// *************************************************************************** *
// *                                                                           *
// *                      Mentor Graphics Corporation                          *
// *                          All rights reserved                              *
// *                                                                           *
// *************************************************************************** *
// *                                                                           *
// * Description:         CANDB File                                           *
// * Generated at:        2022-07-01 13:40                                     *
// * System:              ZSDB122200                                           *
// * Variant:             DC1E_EU                                              *
// * Network:             BodyExposedCAN                                       *
// *                                                                           *
// *************************************************************************** *
// *                                                                           *
// *             THIS CONFIGURATION MIGHT CONTAIN SOME ERRORS                  *
// *              IF THE INPUT MODEL WAS NOT PROPERLY FORMED!                  *
// *                    Do Not Use this File directly!                         *
// *                                                                           *
// *************************************************************************** *
VERSION "BodyExposedCAN"

NS_ :

BS_ :

BU_ :  CEM ETC HCML HCMR RCML RCMM RCMR

BO_ 1322 CemBodyCanExposedNMFr : 8 CEM
 SG_ PNC16_CEM : 16|1@0+ (1,0) [0|0] "" Vector_XXX
 SG_ PNC17_CEM : 17|1@0+ (1,0) [0|0] "" Vector_XXX
 SG_ PNC18_CEM : 18|1@0+ (1,0) [0|0] "" Vector_XXX
 SG_ PNC19_CEM : 19|1@0+ (1,0) [0|0] "" Vector_XXX
 SG_ PNC20_CEM : 20|1@0+ (1,0) [0|0] "" Vector_XXX
 SG_ PNC21_CEM : 21|1@0+ (1,0) [0|0] "" Vector_XXX
 SG_ PNC22_CEM : 22|1@0+ (1,0) [0|0] "" Vector_XXX
 SG_ PNC23_CEM : 23|1@0+ (1,0) [0|0] "" Vector_XXX
 SG_ PNC24_CEM : 24|1@0+ (1,0) [0|0] "" Vector_XXX
 SG_ PNC25_CEM : 25|1@0+ (1,0) [0|0] "" Vector_XXX
 SG_ PNC26_CEM : 26|1@0+ (1,0) [0|0] "" Vector_XXX
 SG_ PNC27_CEM : 27|1@0+ (1,0) [0|0] "" Vector_XXX
 SG_ PNC28_CEM : 28|1@0+ (1,0) [0|0] "" Vector_XXX
 SG_ PNC29_CEM : 29|1@0+ (1,0) [0|0] "" Vector_XXX
 SG_ PNC30_CEM : 30|1@0+ (1,0) [0|0] "" Vector_XXX
 SG_ PNC31_CEM : 31|1@0+ (1,0) [0|0] "" Vector_XXX
 SG_ PNC32_CEM : 32|1@0+ (1,0) [0|0] "" Vector_XXX
 SG_ PNC33_CEM : 33|1@0+ (1,0) [0|0] "" Vector_XXX
 SG_ PNC34_CEM : 34|1@0+ (1,0) [0|0] "" Vector_XXX
 SG_ PNC35_CEM : 35|1@0+ (1,0) [0|0] "" Vector_XXX
 SG_ PNC36_CEM : 36|1@0+ (1,0) [0|0] "" Vector_XXX
 SG_ PNC37_CEM : 37|1@0+ (1,0) [0|0] "" Vector_XXX
 SG_ PNC38_CEM : 38|1@0+ (1,0) [0|0] "" Vector_XXX
 SG_ PNC39_CEM : 39|1@0+ (1,0) [0|0] "" Vector_XXX
 SG_ PNC40_CEM : 40|1@0+ (1,0) [0|0] "" Vector_XXX
 SG_ PNC41_CEM : 41|1@0+ (1,0) [0|0] "" Vector_XXX
 SG_ PNC42_CEM : 42|1@0+ (1,0) [0|0] "" Vector_XXX
 SG_ NM_PNI_CEM : 14|1@0+ (1,0) [0|0] "" Vector_XXX
 SG_ NM_AW_CEM : 12|1@0+ (1,0) [0|0] "" Vector_XXX
 SG_ NM_CS_CEM : 11|1@0+ (1,0) [0|0] "" Vector_XXX
 SG_ NM_RMR_CEM : 8|1@0+ (1,0) [0|0] "" Vector_XXX
 SG_ NM_NodeID_CEM : 7|8@0+ (1,0) [0|0] "" Vector_XXX

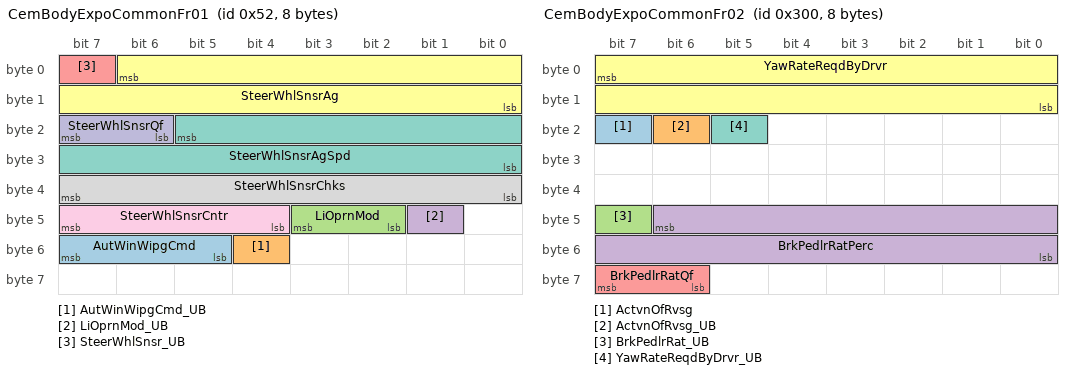
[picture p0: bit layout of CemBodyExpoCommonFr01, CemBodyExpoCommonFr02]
BO_ 82 CemBodyExpoCommonFr01 : 8 CEM
 SG_ AutWinWipgCmd : 55|3@0+ (1,0) [0|7] "" HCML,HCMR
 SG_ AutWinWipgCmd_UB : 52|1@0+ (1,0) [0|1] "" HCML,HCMR
 SG_ LiOprnMod : 43|2@0+ (1,0) [0|3] "" HCML,HCMR
 SG_ LiOprnMod_UB : 41|1@0+ (1,0) [0|1] "" HCML,HCMR
 SG_ SteerWhlSnsr_UB : 7|1@0+ (1,0) [0|1] "" HCML,HCMR
 SG_ SteerWhlSnsrAg : 6|15@0- (0.0009765625,0.0) [-14.5|14.5] "rad" HCML,HCMR
 SG_ SteerWhlSnsrAgSpd : 21|14@0- (0.0078125,0.0) [-50.0|50.0] "rad/s" HCML,HCMR
 SG_ SteerWhlSnsrChks : 39|8@0+ (1.0,0.0) [0.0|255.0] "Unitless" HCML,HCMR
 SG_ SteerWhlSnsrCntr : 47|4@0+ (1.0,0.0) [0.0|15.0] "Unitless" HCML,HCMR
 SG_ SteerWhlSnsrQf : 23|2@0+ (1,0) [0|3] "" HCML,HCMR

BO_ 768 CemBodyExpoCommonFr02 : 8 CEM
 SG_ ActvnOfRvsg : 23|1@0+ (1,0) [0|1] "" RCML,RCMM,RCMR
 SG_ ActvnOfRvsg_UB : 22|1@0+ (1,0) [0|1] "" RCML,RCMM,RCMR
 SG_ BrkPedlrRat_UB : 47|1@0+ (1,0) [0|1] "" HCML,HCMR
 SG_ BrkPedlrRatPerc : 46|15@0+ (0.00390625,0.0) [0.0|100.0] "%" HCML,HCMR
 SG_ BrkPedlrRatQf : 63|2@0+ (1,0) [0|3] "" HCML,HCMR
 SG_ YawRateReqdByDrvr : 7|16@0- (0.000244140625,0.0) [-5.0|5.0] "rad/s" HCML,HCMR
 SG_ YawRateReqdByDrvr_UB : 21|1@0+ (1,0) [0|1] "" HCML,HCMR

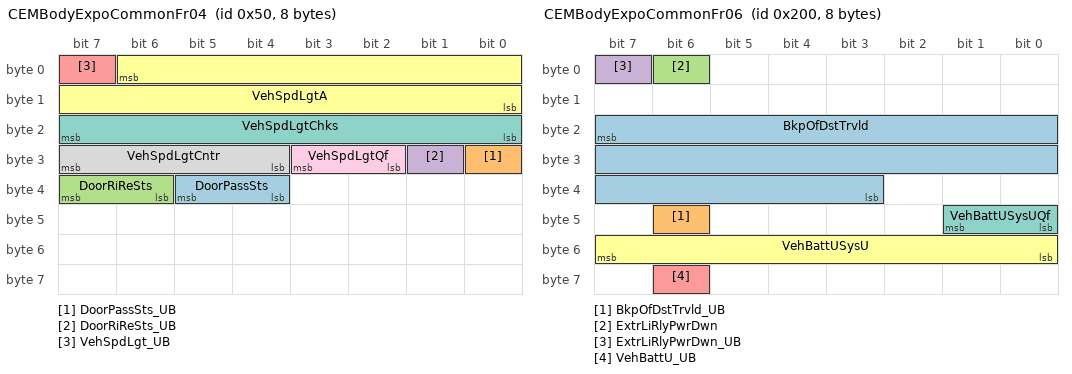
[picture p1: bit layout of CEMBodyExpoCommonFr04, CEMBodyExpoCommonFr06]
BO_ 80 CEMBodyExpoCommonFr04 : 8 CEM
 SG_ DoorPassSts : 37|2@0+ (1,0) [0|3] "" Vector_XXX
 SG_ DoorPassSts_UB : 24|1@0+ (1,0) [0|1] "" Vector_XXX
 SG_ DoorRiReSts : 39|2@0+ (1,0) [0|3] "" Vector_XXX
 SG_ DoorRiReSts_UB : 25|1@0+ (1,0) [0|1] "" Vector_XXX
 SG_ VehSpdLgt_UB : 7|1@0+ (1,0) [0|1] "" HCML,HCMR,RCML,RCMM,RCMR
 SG_ VehSpdLgtA : 6|15@0+ (0.00391,0.0) [0.0|125.0027] "m/s" HCML,HCMR,RCML,RCMM,RCMR
 SG_ VehSpdLgtChks : 23|8@0+ (1.0,0.0) [0.0|255.0] "Unitless" HCML,HCMR,RCML,RCMM,RCMR
 SG_ VehSpdLgtCntr : 31|4@0+ (1.0,0.0) [0.0|15.0] "Unitless" HCML,HCMR,RCML,RCMM,RCMR
 SG_ VehSpdLgtQf : 27|2@0+ (1,0) [0|3] "" HCML,HCMR,RCML,RCMM,RCMR

BO_ 384 CemBodyExpoCommonFr05 : 8 CEM
 SG_ VehCfgPrmBlkIDBytePosn1 : 7|8@0+ (1.0,0.0) [0.0|255.0] "Unitless" HCML,HCMR,RCML,RCMM,RCMR
 SG_ VehCfgPrmCCPBytePosn2 : 15|8@0+ (1.0,0.0) [0.0|255.0] "Unitless" HCML,HCMR,RCML,RCMM,RCMR
 SG_ VehCfgPrmCCPBytePosn3 : 23|8@0+ (1.0,0.0) [0.0|255.0] "Unitless" HCML,HCMR,RCML,RCMM,RCMR
 SG_ VehCfgPrmCCPBytePosn4 : 31|8@0+ (1.0,0.0) [0.0|255.0] "Unitless" HCML,HCMR,RCML,RCMM,RCMR
 SG_ VehCfgPrmCCPBytePosn5 : 39|8@0+ (1.0,0.0) [0.0|255.0] "Unitless" HCML,HCMR,RCML,RCMM,RCMR
 SG_ VehCfgPrmCCPBytePosn6 : 47|8@0+ (1.0,0.0) [0.0|255.0] "Unitless" HCML,HCMR,RCML,RCMM,RCMR
 SG_ VehCfgPrmCCPBytePosn7 : 55|8@0+ (1.0,0.0) [0.0|255.0] "Unitless" HCML,HCMR,RCML,RCMM,RCMR
 SG_ VehCfgPrmCCPBytePosn8 : 63|8@0+ (1.0,0.0) [0.0|255.0] "Unitless" HCML,HCMR,RCML,RCMM,RCMR

BO_ 512 CEMBodyExpoCommonFr06 : 8 CEM
 SG_ BkpOfDstTrvld : 23|21@0+ (1.0,0.0) [0.0|2000000.0] "km" HCML,HCMR,RCML,RCMM,RCMR
 SG_ BkpOfDstTrvld_UB : 46|1@0+ (1,0) [0|1] "" HCML,HCMR,RCML,RCMM,RCMR
 SG_ ExtrLiRlyPwrDwn : 6|1@0+ (1,0) [0|1] "" HCML,HCMR
 SG_ ExtrLiRlyPwrDwn_UB : 7|1@0+ (1,0) [0|1] "" HCML,HCMR
 SG_ VehBattU_UB : 62|1@0+ (1,0) [0|1] "" HCML,HCMR,RCML,RCMM,RCMR
 SG_ VehBattUSysU : 55|8@0+ (0.1,0.0) [0.0|25.0] "Volt" HCML,HCMR,RCML,RCMM,RCMR
 SG_ VehBattUSysUQf : 41|2@0+ (1,0) [0|3] "" HCML,HCMR,RCML,RCMM,RCMR

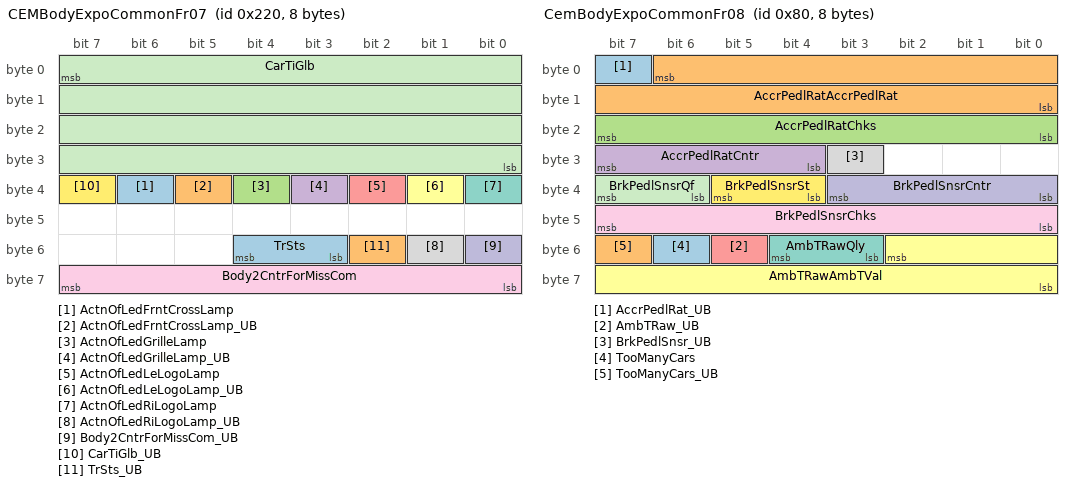
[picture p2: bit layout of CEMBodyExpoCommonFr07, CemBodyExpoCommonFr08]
BO_ 544 CEMBodyExpoCommonFr07 : 8 CEM
 SG_ ActnOfLedFrntCrossLamp : 38|1@0+ (1,0) [0|1] "" HCML,HCMR
 SG_ ActnOfLedFrntCrossLamp_UB : 37|1@0+ (1,0) [0|1] "" HCML,HCMR
 SG_ ActnOfLedGrilleLamp : 36|1@0+ (1,0) [0|1] "" HCML,HCMR
 SG_ ActnOfLedGrilleLamp_UB : 35|1@0+ (1,0) [0|1] "" HCML,HCMR
 SG_ ActnOfLedLeLogoLamp : 34|1@0+ (1,0) [0|1] "" HCML
 SG_ ActnOfLedLeLogoLamp_UB : 33|1@0+ (1,0) [0|1] "" HCML
 SG_ ActnOfLedRiLogoLamp : 32|1@0+ (1,0) [0|1] "" HCMR
 SG_ ActnOfLedRiLogoLamp_UB : 49|1@0+ (1,0) [0|1] "" HCMR
 SG_ Body2CntrForMissCom : 63|8@0+ (1.0,0.0) [0.0|255.0] "Unitless" HCML,HCMR
 SG_ Body2CntrForMissCom_UB : 48|1@0+ (1,0) [0|1] "" HCML,HCMR
 SG_ CarTiGlb : 7|32@0+ (0.1,0.0) [0.0|429496729.5] "s" HCML,HCMR,RCML,RCMM,RCMR
 SG_ CarTiGlb_UB : 39|1@0+ (1,0) [0|1] "" HCML,HCMR,RCML,RCMM,RCMR
 SG_ TrSts : 52|2@0+ (1,0) [0|3] "" RCML,RCMM,RCMR
 SG_ TrSts_UB : 50|1@0+ (1,0) [0|1] "" RCML,RCMM,RCMR

BO_ 128 CemBodyExpoCommonFr08 : 8 CEM
 SG_ AccrPedlRat_UB : 7|1@0+ (1,0) [0|1] "" HCML,HCMR
 SG_ AccrPedlRatAccrPedlRat : 6|15@0+ (0.00390625,0.0) [0.0|100.0] "%" HCML,HCMR
 SG_ AccrPedlRatChks : 23|8@0+ (1.0,0.0) [0.0|255.0] "Unitless" HCML,HCMR
 SG_ AccrPedlRatCntr : 31|4@0+ (1.0,0.0) [0.0|15.0] "Unitless" HCML,HCMR
 SG_ AmbTRaw_UB : 53|1@0+ (1,0) [0|1] "" HCML,HCMR
 SG_ AmbTRawAmbTVal : 50|11@0+ (0.1,-70.0) [-70.0|134.70000000000002] "degC" HCML,HCMR
 SG_ AmbTRawQly : 52|2@0+ (1,0) [0|3] "" HCML,HCMR
 SG_ BrkPedlSnsr_UB : 27|1@0+ (1,0) [0|1] "" HCML,HCMR
 SG_ BrkPedlSnsrChks : 47|8@0+ (1.0,0.0) [0.0|255.0] "Unitless" HCML,HCMR
 SG_ BrkPedlSnsrCntr : 35|4@0+ (1.0,0.0) [0.0|15.0] "Unitless" HCML,HCMR
 SG_ BrkPedlSnsrQf : 39|2@0+ (1,0) [0|3] "" HCML,HCMR
 SG_ BrkPedlSnsrSt : 37|2@0+ (1,0) [0|3] "" HCML,HCMR
 SG_ TooManyCars : 54|1@0+ (1,0) [0|1] "" HCML,HCMR
 SG_ TooManyCars_UB : 55|1@0+ (1,0) [0|1] "" HCML,HCMR

BO_ 387 CemBodyExpoCommonFr09 : 8 CEM
 SG_ VehCfgPrmExtBlkIDBytePosn1 : 7|8@0+ (1.0,0.0) [0.0|255.0] "Unitless" HCML,HCMR,RCML,RCMM,RCMR
 SG_ VehCfgPrmExtCCPBytePosn2 : 15|8@0+ (1.0,0.0) [0.0|255.0] "Unitless" HCML,HCMR,RCML,RCMM,RCMR
 SG_ VehCfgPrmExtCCPBytePosn3 : 23|8@0+ (1.0,0.0) [0.0|255.0] "Unitless" HCML,HCMR,RCML,RCMM,RCMR
 SG_ VehCfgPrmExtCCPBytePosn4 : 31|8@0+ (1.0,0.0) [0.0|255.0] "Unitless" HCML,HCMR,RCML,RCMM,RCMR
 SG_ VehCfgPrmExtCCPBytePosn5 : 39|8@0+ (1.0,0.0) [0.0|255.0] "Unitless" HCML,HCMR,RCML,RCMM,RCMR
 SG_ VehCfgPrmExtCCPBytePosn6 : 47|8@0+ (1.0,0.0) [0.0|255.0] "Unitless" HCML,HCMR,RCML,RCMM,RCMR
 SG_ VehCfgPrmExtCCPBytePosn7 : 55|8@0+ (1.0,0.0) [0.0|255.0] "Unitless" HCML,HCMR,RCML,RCMM,RCMR
 SG_ VehCfgPrmExtCCPBytePosn8 : 63|8@0+ (1.0,0.0) [0.0|255.0] "Unitless" HCML,HCMR,RCML,RCMM,RCMR

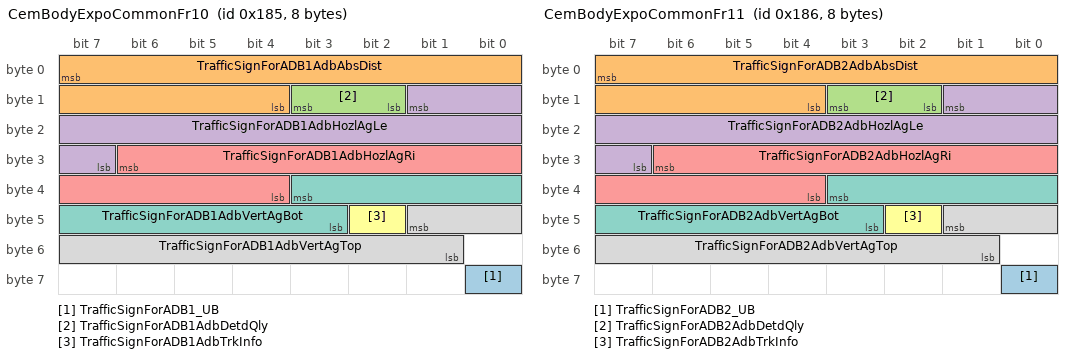
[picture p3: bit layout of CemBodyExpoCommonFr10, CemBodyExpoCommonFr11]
BO_ 389 CemBodyExpoCommonFr10 : 8 CEM
 SG_ TrafficSignForADB1_UB : 56|1@0+ (1,0) [0|1] "" HCML,HCMR
 SG_ TrafficSignForADB1AdbAbsDist : 7|12@0+ (0.2,0.0) [0.0|819.0] "m" HCML,HCMR
 SG_ TrafficSignForADB1AdbDetdQly : 11|2@0+ (1,0) [0|3] "" HCML,HCMR
 SG_ TrafficSignForADB1AdbHozlAgLe : 9|11@0+ (0.05,-40.0) [-40.0|40.0] "Deg" HCML,HCMR
 SG_ TrafficSignForADB1AdbHozlAgRi : 30|11@0+ (0.05,-40.0) [-40.0|40.0] "Deg" HCML,HCMR
 SG_ TrafficSignForADB1AdbTrkInfo : 42|1@0+ (1,0) [0|1] "" HCML,HCMR
 SG_ TrafficSignForADB1AdbVertAgBot : 35|9@0+ (0.05,-3.0) [-3.0|22.55] "Deg" HCML,HCMR
 SG_ TrafficSignForADB1AdbVertAgTop : 41|9@0+ (0.05,-3.0) [-3.0|22.55] "Deg" HCML,HCMR

BO_ 390 CemBodyExpoCommonFr11 : 8 CEM
 SG_ TrafficSignForADB2_UB : 56|1@0+ (1,0) [0|1] "" HCML,HCMR
 SG_ TrafficSignForADB2AdbAbsDist : 7|12@0+ (0.2,0.0) [0.0|819.0] "m" HCML,HCMR
 SG_ TrafficSignForADB2AdbDetdQly : 11|2@0+ (1,0) [0|3] "" HCML,HCMR
 SG_ TrafficSignForADB2AdbHozlAgLe : 9|11@0+ (0.05,-40.0) [-40.0|40.0] "Deg" HCML,HCMR
 SG_ TrafficSignForADB2AdbHozlAgRi : 30|11@0+ (0.05,-40.0) [-40.0|40.0] "Deg" HCML,HCMR
 SG_ TrafficSignForADB2AdbTrkInfo : 42|1@0+ (1,0) [0|1] "" HCML,HCMR
 SG_ TrafficSignForADB2AdbVertAgBot : 35|9@0+ (0.05,-3.0) [-3.0|22.55] "Deg" HCML,HCMR
 SG_ TrafficSignForADB2AdbVertAgTop : 41|9@0+ (0.05,-3.0) [-3.0|22.55] "Deg" HCML,HCMR

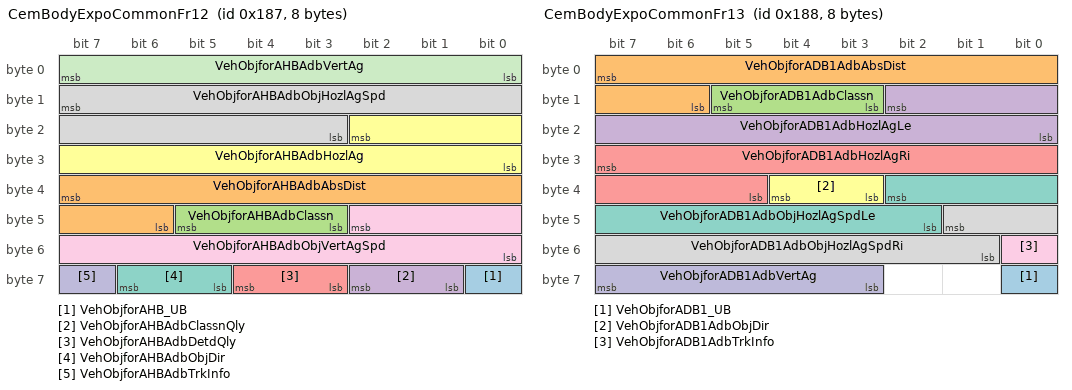
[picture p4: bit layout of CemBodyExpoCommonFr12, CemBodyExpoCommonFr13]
BO_ 391 CemBodyExpoCommonFr12 : 8 CEM
 SG_ VehObjforAHB_UB : 56|1@0+ (1,0) [0|1] "" HCML,HCMR
 SG_ VehObjforAHBAdbAbsDist : 39|10@0+ (1.0,0.0) [0.0|1000.0] "m" HCML,HCMR
 SG_ VehObjforAHBAdbClassn : 45|3@0+ (1,0) [0|7] "" HCML,HCMR
 SG_ VehObjforAHBAdbClassnQly : 58|2@0+ (1,0) [0|3] "" HCML,HCMR
 SG_ VehObjforAHBAdbDetdQly : 60|2@0+ (1,0) [0|3] "" HCML,HCMR
 SG_ VehObjforAHBAdbHozlAg : 18|11@0+ (0.05,-40.0) [-40.0|40.0] "Deg" HCML,HCMR
 SG_ VehObjforAHBAdbObjDir : 62|2@0+ (1,0) [0|3] "" HCML,HCMR
 SG_ VehObjforAHBAdbObjHozlAgSpd : 15|13@0+ (0.05,-144.0) [-144.0|144.0] "DegPerSec" HCML,HCMR
 SG_ VehObjforAHBAdbObjVertAgSpd : 42|11@0+ (0.2,-144.0) [-144.0|144.0] "DegPerSec" HCML,HCMR
 SG_ VehObjforAHBAdbTrkInfo : 63|1@0+ (1,0) [0|1] "" HCML,HCMR
 SG_ VehObjforAHBAdbVertAg : 7|8@0+ (0.2,-15.0) [-15.0|15.0] "Deg" HCML,HCMR

BO_ 392 CemBodyExpoCommonFr13 : 8 CEM
 SG_ VehObjforADB1_UB : 56|1@0+ (1,0) [0|1] "" HCML,HCMR
 SG_ VehObjforADB1AdbAbsDist : 7|10@0+ (1.0,0.0) [0.0|1000.0] "m" HCML,HCMR
 SG_ VehObjforADB1AdbClassn : 13|3@0+ (1,0) [0|7] "" HCML,HCMR
 SG_ VehObjforADB1AdbHozlAgLe : 10|11@0+ (0.05,-40.0) [-40.0|40.0] "Deg" HCML,HCMR
 SG_ VehObjforADB1AdbHozlAgRi : 31|11@0+ (0.05,-40.0) [-40.0|40.0] "Deg" HCML,HCMR
 SG_ VehObjforADB1AdbObjDir : 36|2@0+ (1,0) [0|3] "" HCML,HCMR
 SG_ VehObjforADB1AdbObjHozlAgSpdLe : 34|9@0+ (0.2,-50.0) [-50.0|52.2] "DegPerSec" HCML,HCMR
 SG_ VehObjforADB1AdbObjHozlAgSpdRi : 41|9@0+ (0.2,-50.0) [-50.0|52.2] "DegPerSec" HCML,HCMR
 SG_ VehObjforADB1AdbTrkInfo : 48|1@0+ (1,0) [0|1] "" HCML,HCMR
 SG_ VehObjforADB1AdbVertAg : 63|5@0+ (0.5,-3.0) [-3.0|12.5] "Deg" HCML,HCMR

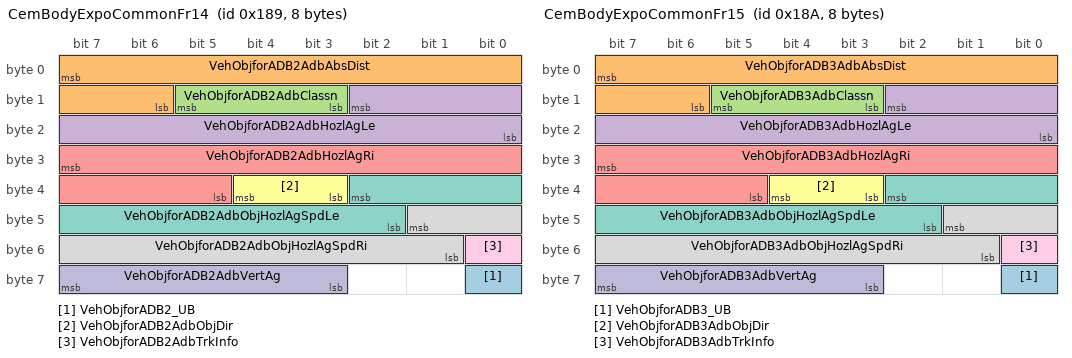
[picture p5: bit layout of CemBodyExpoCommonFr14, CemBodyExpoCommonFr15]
BO_ 393 CemBodyExpoCommonFr14 : 8 CEM
 SG_ VehObjforADB2_UB : 56|1@0+ (1,0) [0|1] "" HCML,HCMR
 SG_ VehObjforADB2AdbAbsDist : 7|10@0+ (1.0,0.0) [0.0|1000.0] "m" HCML,HCMR
 SG_ VehObjforADB2AdbClassn : 13|3@0+ (1,0) [0|7] "" HCML,HCMR
 SG_ VehObjforADB2AdbHozlAgLe : 10|11@0+ (0.05,-40.0) [-40.0|40.0] "Deg" HCML,HCMR
 SG_ VehObjforADB2AdbHozlAgRi : 31|11@0+ (0.05,-40.0) [-40.0|40.0] "Deg" HCML,HCMR
 SG_ VehObjforADB2AdbObjDir : 36|2@0+ (1,0) [0|3] "" HCML,HCMR
 SG_ VehObjforADB2AdbObjHozlAgSpdLe : 34|9@0+ (0.2,-50.0) [-50.0|52.2] "DegPerSec" HCML,HCMR
 SG_ VehObjforADB2AdbObjHozlAgSpdRi : 41|9@0+ (0.2,-50.0) [-50.0|52.2] "DegPerSec" HCML,HCMR
 SG_ VehObjforADB2AdbTrkInfo : 48|1@0+ (1,0) [0|1] "" HCML,HCMR
 SG_ VehObjforADB2AdbVertAg : 63|5@0+ (0.5,-3.0) [-3.0|12.5] "Deg" HCML,HCMR

BO_ 394 CemBodyExpoCommonFr15 : 8 CEM
 SG_ VehObjforADB3_UB : 56|1@0+ (1,0) [0|1] "" HCML,HCMR
 SG_ VehObjforADB3AdbAbsDist : 7|10@0+ (1.0,0.0) [0.0|1000.0] "m" HCML,HCMR
 SG_ VehObjforADB3AdbClassn : 13|3@0+ (1,0) [0|7] "" HCML,HCMR
 SG_ VehObjforADB3AdbHozlAgLe : 10|11@0+ (0.05,-40.0) [-40.0|40.0] "Deg" HCML,HCMR
 SG_ VehObjforADB3AdbHozlAgRi : 31|11@0+ (0.05,-40.0) [-40.0|40.0] "Deg" HCML,HCMR
 SG_ VehObjforADB3AdbObjDir : 36|2@0+ (1,0) [0|3] "" HCML,HCMR
 SG_ VehObjforADB3AdbObjHozlAgSpdLe : 34|9@0+ (0.2,-50.0) [-50.0|52.2] "DegPerSec" HCML,HCMR
 SG_ VehObjforADB3AdbObjHozlAgSpdRi : 41|9@0+ (0.2,-50.0) [-50.0|52.2] "DegPerSec" HCML,HCMR
 SG_ VehObjforADB3AdbTrkInfo : 48|1@0+ (1,0) [0|1] "" HCML,HCMR
 SG_ VehObjforADB3AdbVertAg : 63|5@0+ (0.5,-3.0) [-3.0|12.5] "Deg" HCML,HCMR

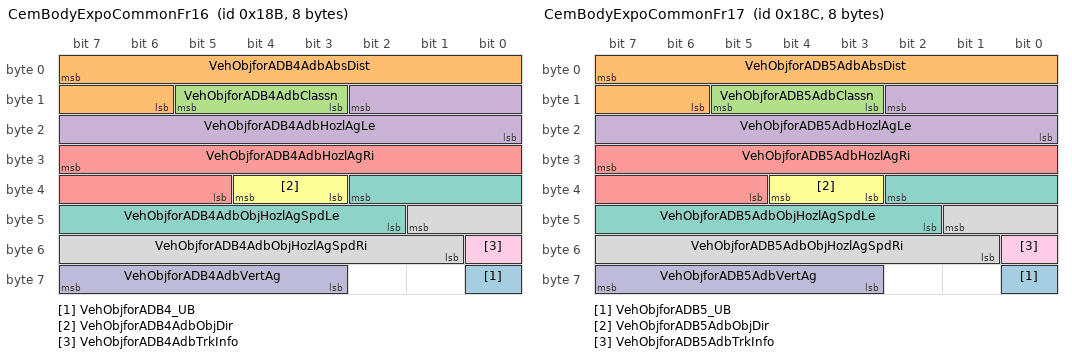
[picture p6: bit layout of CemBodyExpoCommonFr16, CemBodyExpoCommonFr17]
BO_ 395 CemBodyExpoCommonFr16 : 8 CEM
 SG_ VehObjforADB4_UB : 56|1@0+ (1,0) [0|1] "" HCML,HCMR
 SG_ VehObjforADB4AdbAbsDist : 7|10@0+ (1.0,0.0) [0.0|1000.0] "m" HCML,HCMR
 SG_ VehObjforADB4AdbClassn : 13|3@0+ (1,0) [0|7] "" HCML,HCMR
 SG_ VehObjforADB4AdbHozlAgLe : 10|11@0+ (0.05,-40.0) [-40.0|40.0] "Deg" HCML,HCMR
 SG_ VehObjforADB4AdbHozlAgRi : 31|11@0+ (0.05,-40.0) [-40.0|40.0] "Deg" HCML,HCMR
 SG_ VehObjforADB4AdbObjDir : 36|2@0+ (1,0) [0|3] "" HCML,HCMR
 SG_ VehObjforADB4AdbObjHozlAgSpdLe : 34|9@0+ (0.2,-50.0) [-50.0|52.2] "DegPerSec" HCML,HCMR
 SG_ VehObjforADB4AdbObjHozlAgSpdRi : 41|9@0+ (0.2,-50.0) [-50.0|52.2] "DegPerSec" HCML,HCMR
 SG_ VehObjforADB4AdbTrkInfo : 48|1@0+ (1,0) [0|1] "" HCML,HCMR
 SG_ VehObjforADB4AdbVertAg : 63|5@0+ (0.5,-3.0) [-3.0|12.5] "Deg" HCML,HCMR

BO_ 396 CemBodyExpoCommonFr17 : 8 CEM
 SG_ VehObjforADB5_UB : 56|1@0+ (1,0) [0|1] "" HCML,HCMR
 SG_ VehObjforADB5AdbAbsDist : 7|10@0+ (1.0,0.0) [0.0|1000.0] "m" HCML,HCMR
 SG_ VehObjforADB5AdbClassn : 13|3@0+ (1,0) [0|7] "" HCML,HCMR
 SG_ VehObjforADB5AdbHozlAgLe : 10|11@0+ (0.05,-40.0) [-40.0|40.0] "Deg" HCML,HCMR
 SG_ VehObjforADB5AdbHozlAgRi : 31|11@0+ (0.05,-40.0) [-40.0|40.0] "Deg" HCML,HCMR
 SG_ VehObjforADB5AdbObjDir : 36|2@0+ (1,0) [0|3] "" HCML,HCMR
 SG_ VehObjforADB5AdbObjHozlAgSpdLe : 34|9@0+ (0.2,-50.0) [-50.0|52.2] "DegPerSec" HCML,HCMR
 SG_ VehObjforADB5AdbObjHozlAgSpdRi : 41|9@0+ (0.2,-50.0) [-50.0|52.2] "DegPerSec" HCML,HCMR
 SG_ VehObjforADB5AdbTrkInfo : 48|1@0+ (1,0) [0|1] "" HCML,HCMR
 SG_ VehObjforADB5AdbVertAg : 63|5@0+ (0.5,-3.0) [-3.0|12.5] "Deg" HCML,HCMR

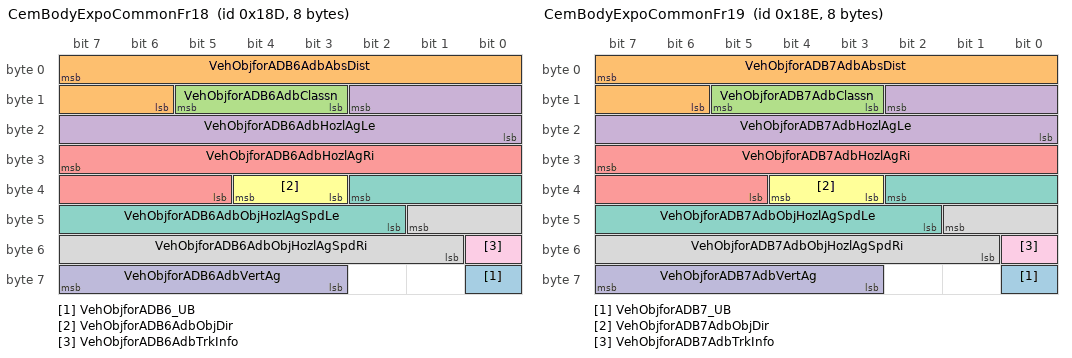
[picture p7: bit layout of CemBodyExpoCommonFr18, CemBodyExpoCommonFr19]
BO_ 397 CemBodyExpoCommonFr18 : 8 CEM
 SG_ VehObjforADB6_UB : 56|1@0+ (1,0) [0|1] "" HCML,HCMR
 SG_ VehObjforADB6AdbAbsDist : 7|10@0+ (1.0,0.0) [0.0|1000.0] "m" HCML,HCMR
 SG_ VehObjforADB6AdbClassn : 13|3@0+ (1,0) [0|7] "" HCML,HCMR
 SG_ VehObjforADB6AdbHozlAgLe : 10|11@0+ (0.05,-40.0) [-40.0|40.0] "Deg" HCML,HCMR
 SG_ VehObjforADB6AdbHozlAgRi : 31|11@0+ (0.05,-40.0) [-40.0|40.0] "Deg" HCML,HCMR
 SG_ VehObjforADB6AdbObjDir : 36|2@0+ (1,0) [0|3] "" HCML,HCMR
 SG_ VehObjforADB6AdbObjHozlAgSpdLe : 34|9@0+ (0.2,-50.0) [-50.0|52.2] "DegPerSec" HCML,HCMR
 SG_ VehObjforADB6AdbObjHozlAgSpdRi : 41|9@0+ (0.2,-50.0) [-50.0|52.2] "DegPerSec" HCML,HCMR
 SG_ VehObjforADB6AdbTrkInfo : 48|1@0+ (1,0) [0|1] "" HCML,HCMR
 SG_ VehObjforADB6AdbVertAg : 63|5@0+ (0.5,-3.0) [-3.0|12.5] "Deg" HCML,HCMR

BO_ 398 CemBodyExpoCommonFr19 : 8 CEM
 SG_ VehObjforADB7_UB : 56|1@0+ (1,0) [0|1] "" HCML,HCMR
 SG_ VehObjforADB7AdbAbsDist : 7|10@0+ (1.0,0.0) [0.0|1000.0] "m" HCML,HCMR
 SG_ VehObjforADB7AdbClassn : 13|3@0+ (1,0) [0|7] "" HCML,HCMR
 SG_ VehObjforADB7AdbHozlAgLe : 10|11@0+ (0.05,-40.0) [-40.0|40.0] "Deg" HCML,HCMR
 SG_ VehObjforADB7AdbHozlAgRi : 31|11@0+ (0.05,-40.0) [-40.0|40.0] "Deg" HCML,HCMR
 SG_ VehObjforADB7AdbObjDir : 36|2@0+ (1,0) [0|3] "" HCML,HCMR
 SG_ VehObjforADB7AdbObjHozlAgSpdLe : 34|9@0+ (0.2,-50.0) [-50.0|52.2] "DegPerSec" HCML,HCMR
 SG_ VehObjforADB7AdbObjHozlAgSpdRi : 41|9@0+ (0.2,-50.0) [-50.0|52.2] "DegPerSec" HCML,HCMR
 SG_ VehObjforADB7AdbTrkInfo : 48|1@0+ (1,0) [0|1] "" HCML,HCMR
 SG_ VehObjforADB7AdbVertAg : 63|5@0+ (0.5,-3.0) [-3.0|12.5] "Deg" HCML,HCMR

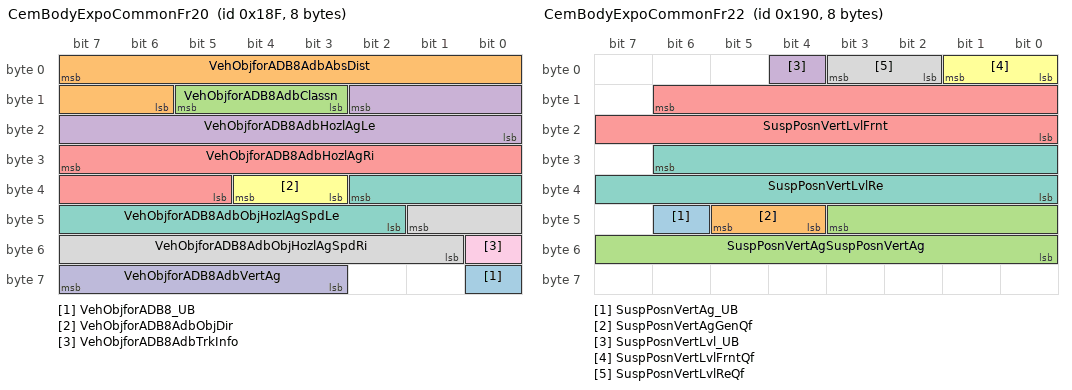
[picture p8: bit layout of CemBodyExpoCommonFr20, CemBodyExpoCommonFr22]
BO_ 399 CemBodyExpoCommonFr20 : 8 CEM
 SG_ VehObjforADB8_UB : 56|1@0+ (1,0) [0|1] "" HCML,HCMR
 SG_ VehObjforADB8AdbAbsDist : 7|10@0+ (1.0,0.0) [0.0|1000.0] "m" HCML,HCMR
 SG_ VehObjforADB8AdbClassn : 13|3@0+ (1,0) [0|7] "" HCML,HCMR
 SG_ VehObjforADB8AdbHozlAgLe : 10|11@0+ (0.05,-40.0) [-40.0|40.0] "Deg" HCML,HCMR
 SG_ VehObjforADB8AdbHozlAgRi : 31|11@0+ (0.05,-40.0) [-40.0|40.0] "Deg" HCML,HCMR
 SG_ VehObjforADB8AdbObjDir : 36|2@0+ (1,0) [0|3] "" HCML,HCMR
 SG_ VehObjforADB8AdbObjHozlAgSpdLe : 34|9@0+ (0.2,-50.0) [-50.0|52.2] "DegPerSec" HCML,HCMR
 SG_ VehObjforADB8AdbObjHozlAgSpdRi : 41|9@0+ (0.2,-50.0) [-50.0|52.2] "DegPerSec" HCML,HCMR
 SG_ VehObjforADB8AdbTrkInfo : 48|1@0+ (1,0) [0|1] "" HCML,HCMR
 SG_ VehObjforADB8AdbVertAg : 63|5@0+ (0.5,-3.0) [-3.0|12.5] "Deg" HCML,HCMR

BO_ 64 CemBodyExpoCommonFr21 : 8 CEM
 SG_ CameraStsforAHBC : 62|2@0+ (1,0) [0|3] "" HCML,HCMR
 SG_ CameraStsforAHBC_UB : 60|1@0+ (1,0) [0|1] "" HCML,HCMR
 SG_ RainLi : 47|1@0+ (1,0) [0|1] "" HCML,HCMR
 SG_ RainLi_UB : 63|1@0+ (1,0) [0|1] "" HCML,HCMR
 SG_ VehModMngtGlbSafe1_UB : 32|1@0+ (1,0) [0|1] "" HCML,HCMR,RCML,RCMM,RCMR
 SG_ VehModMngtGlbSafe1CarModSts1 : 39|3@0+ (1,0) [0|7] "" HCML,HCMR,RCML,RCMM,RCMR
 SG_ VehModMngtGlbSafe1CarModSubtypWdCarModSubtyp : 35|3@0+ (1.0,0.0) [0.0|7.0] "Unitless" HCML,HCMR,RCML,RCMM,RCMR
 SG_ VehModMngtGlbSafe1Chks : 7|8@0+ (1.0,0.0) [0.0|255.0] "Unitless" HCML,HCMR,RCML,RCMM,RCMR
 SG_ VehModMngtGlbSafe1Cntr : 15|4@0+ (1.0,0.0) [0.0|15.0] "Unitless" HCML,HCMR,RCML,RCMM,RCMR
 SG_ VehModMngtGlbSafe1EgyLvlElecMai : 27|4@0+ (1.0,0.0) [0.0|15.0] "Unitless" HCML,HCMR,RCML,RCMM,RCMR
 SG_ VehModMngtGlbSafe1EgyLvlElecSubtyp : 31|4@0+ (1.0,0.0) [0.0|15.0] "Unitless" HCML,HCMR,RCML,RCMM,RCMR
 SG_ VehModMngtGlbSafe1FltEgyCnsWdSts : 36|1@0+ (1,0) [0|1] "" HCML,HCMR,RCML,RCMM,RCMR
 SG_ VehModMngtGlbSafe1PwrLvlElecMai : 19|4@0+ (1.0,0.0) [0.0|15.0] "Unitless" HCML,HCMR,RCML,RCMM,RCMR
 SG_ VehModMngtGlbSafe1PwrLvlElecSubtyp : 23|4@0+ (1.0,0.0) [0.0|15.0] "Unitless" HCML,HCMR,RCML,RCMM,RCMR
 SG_ VehModMngtGlbSafe1UsgModSts : 11|4@0+ (1,0) [0|15] "" HCML,HCMR,RCML,RCMM,RCMR
 SG_ WipgAutFrntMod : 59|2@0+ (1,0) [0|3] "" HCML,HCMR
 SG_ WipgAutFrntMod_UB : 57|1@0+ (1,0) [0|1] "" HCML,HCMR

BO_ 400 CemBodyExpoCommonFr22 : 8 CEM
 SG_ SuspPosnVertAg_UB : 46|1@0+ (1,0) [0|1] "" HCML,HCMR
 SG_ SuspPosnVertAgGenQf : 45|2@0+ (1,0) [0|3] "" HCML,HCMR
 SG_ SuspPosnVertAgSuspPosnVertAg : 43|12@0- (0.000127894181,0.0) [-0.26167149432599995|0.26179938850699996] "rad" HCML,HCMR
 SG_ SuspPosnVertLvl_UB : 4|1@0+ (1,0) [0|1] "" HCML,HCMR
 SG_ SuspPosnVertLvlFrnt : 14|15@0- (0.000062,0.0) [-0.999998|1.00006] "m" HCML,HCMR
 SG_ SuspPosnVertLvlFrntQf : 1|2@0+ (1,0) [0|3] "" HCML,HCMR
 SG_ SuspPosnVertLvlRe : 30|15@0- (0.000062,0.0) [-0.999998|1.00006] "m" HCML,HCMR
 SG_ SuspPosnVertLvlReQf : 3|2@0+ (1,0) [0|3] "" HCML,HCMR

BO_ 1432 CemBodyExpoDevDiagFr01 : 8 CEM
 SG_ CEMdevelpsignalgrouprespFunctiondevpsignalgroup1 : 7|8@0+ (1.0,0.0) [0.0|255.0] "Unitless" ETC
 SG_ CEMdevelpsignalgrouprespFunctiondevpsignalgroup2 : 15|8@0+ (1.0,0.0) [0.0|255.0] "Unitless" ETC
 SG_ CEMdevelpsignalgrouprespFunctiondevpsignalgroup3 : 23|8@0+ (1.0,0.0) [0.0|255.0] "Unitless" ETC
 SG_ CEMdevelpsignalgrouprespFunctiondevpsignalgroup4 : 31|8@0+ (1.0,0.0) [0.0|255.0] "Unitless" ETC
 SG_ CEMdevelpsignalgrouprespFunctiondevpsignalgroup5 : 39|8@0+ (1.0,0.0) [0.0|255.0] "Unitless" ETC
 SG_ CEMdevelpsignalgrouprespFunctiondevpsignalgroup6 : 47|8@0+ (1.0,0.0) [0.0|255.0] "Unitless" ETC
 SG_ CEMdevelpsignalgrouprespFunctiondevpsignalgroup7 : 55|8@0+ (1.0,0.0) [0.0|255.0] "Unitless" ETC
 SG_ CEMdevelpsignalgrouprespFunctiondevpsignalgroup8 : 63|8@0+ (1.0,0.0) [0.0|255.0] "Unitless" ETC

BO_ 1431 CemBodyExpoDevFr02 : 8 CEM
 SG_ CEMdevelpsignalgroupcheckFunctiondevpsignalgroup1 : 7|8@0+ (1.0,0.0) [0.0|255.0] "Unitless" ETC
 SG_ CEMdevelpsignalgroupcheckFunctiondevpsignalgroup2 : 15|8@0+ (1.0,0.0) [0.0|255.0] "Unitless" ETC
 SG_ CEMdevelpsignalgroupcheckFunctiondevpsignalgroup3 : 23|8@0+ (1.0,0.0) [0.0|255.0] "Unitless" ETC
 SG_ CEMdevelpsignalgroupcheckFunctiondevpsignalgroup4 : 31|8@0+ (1.0,0.0) [0.0|255.0] "Unitless" ETC
 SG_ CEMdevelpsignalgroupcheckFunctiondevpsignalgroup5 : 39|8@0+ (1.0,0.0) [0.0|255.0] "Unitless" ETC
 SG_ CEMdevelpsignalgroupcheckFunctiondevpsignalgroup6 : 47|8@0+ (1.0,0.0) [0.0|255.0] "Unitless" ETC
 SG_ CEMdevelpsignalgroupcheckFunctiondevpsignalgroup7 : 55|8@0+ (1.0,0.0) [0.0|255.0] "Unitless" ETC
 SG_ CEMdevelpsignalgroupcheckFunctiondevpsignalgroup8 : 63|8@0+ (1.0,0.0) [0.0|255.0] "Unitless" ETC

BO_ 28 CemBodyExpoFr01 : 8 CEM
 SG_ CarpetLiActvReq : 47|2@0+ (1,0) [0|3] "" Vector_XXX
 SG_ CarpetLiActvReq_UB : 45|1@0+ (1,0) [0|1] "" Vector_XXX
 SG_ ExtrLiShowActvnReq : 44|1@0+ (1,0) [0|1] "" HCML,HCMR,RCML,RCMM,RCMR
 SG_ ExtrLiShowActvnReq_UB : 43|1@0+ (1,0) [0|1] "" HCML,HCMR,RCML,RCMM,RCMR
 SG_ ExtrLiShowFileTxReq : 42|1@0+ (1,0) [0|1] "" HCML,HCMR,RCML,RCMM,RCMR
 SG_ ExtrLiShowFileTxReq_UB : 41|1@0+ (1,0) [0|1] "" HCML,HCMR,RCML,RCMM,RCMR

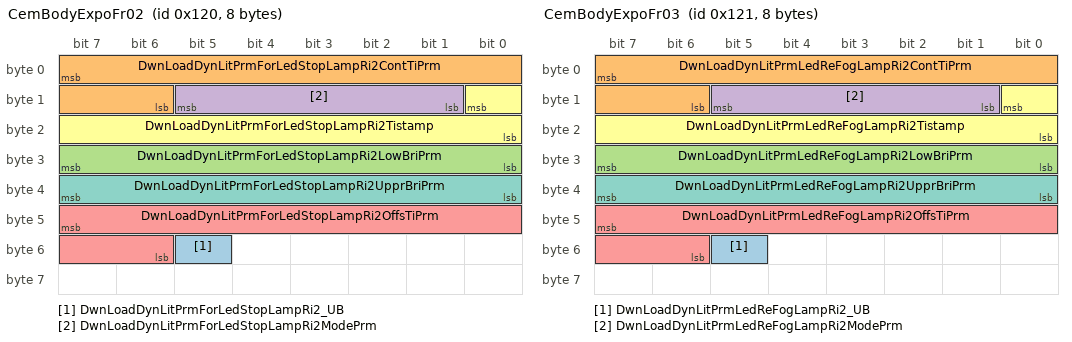
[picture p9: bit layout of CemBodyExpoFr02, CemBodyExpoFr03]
BO_ 288 CemBodyExpoFr02 : 8 CEM
 SG_ DwnLoadDynLitPrmForLedStopLampRi2_UB : 53|1@0+ (1,0) [0|1] "" RCMM,RCMR
 SG_ DwnLoadDynLitPrmForLedStopLampRi2ContTiPrm : 7|10@0+ (1.0,0.0) [0.0|1000.0] "Milliseconds" RCMM,RCMR
 SG_ DwnLoadDynLitPrmForLedStopLampRi2LowBriPrm : 31|8@0+ (1.0,0.0) [0.0|100.0] "%" RCMM,RCMR
 SG_ DwnLoadDynLitPrmForLedStopLampRi2ModePrm : 13|5@0+ (1,0) [0|31] "" RCMM,RCMR
 SG_ DwnLoadDynLitPrmForLedStopLampRi2OffsTiPrm : 47|10@0+ (1.0,0.0) [0.0|1000.0] "Milliseconds" RCMM,RCMR
 SG_ DwnLoadDynLitPrmForLedStopLampRi2Tistamp : 8|9@0+ (1.0,0.0) [0.0|511.0] "Unitless" RCMM,RCMR
 SG_ DwnLoadDynLitPrmForLedStopLampRi2UpprBriPrm : 39|8@0+ (1.0,0.0) [0.0|100.0] "%" RCMM,RCMR

BO_ 289 CemBodyExpoFr03 : 8 CEM
 SG_ DwnLoadDynLitPrmLedReFogLampRi2_UB : 53|1@0+ (1,0) [0|1] "" RCMM,RCMR
 SG_ DwnLoadDynLitPrmLedReFogLampRi2ContTiPrm : 7|10@0+ (1.0,0.0) [0.0|1000.0] "Milliseconds" RCMM,RCMR
 SG_ DwnLoadDynLitPrmLedReFogLampRi2LowBriPrm : 31|8@0+ (1.0,0.0) [0.0|100.0] "%" RCMM,RCMR
 SG_ DwnLoadDynLitPrmLedReFogLampRi2ModePrm : 13|5@0+ (1,0) [0|31] "" RCMM,RCMR
 SG_ DwnLoadDynLitPrmLedReFogLampRi2OffsTiPrm : 47|10@0+ (1.0,0.0) [0.0|1000.0] "Milliseconds" RCMM,RCMR
 SG_ DwnLoadDynLitPrmLedReFogLampRi2Tistamp : 8|9@0+ (1.0,0.0) [0.0|511.0] "Unitless" RCMM,RCMR
 SG_ DwnLoadDynLitPrmLedReFogLampRi2UpprBriPrm : 39|8@0+ (1.0,0.0) [0.0|100.0] "%" RCMM,RCMR

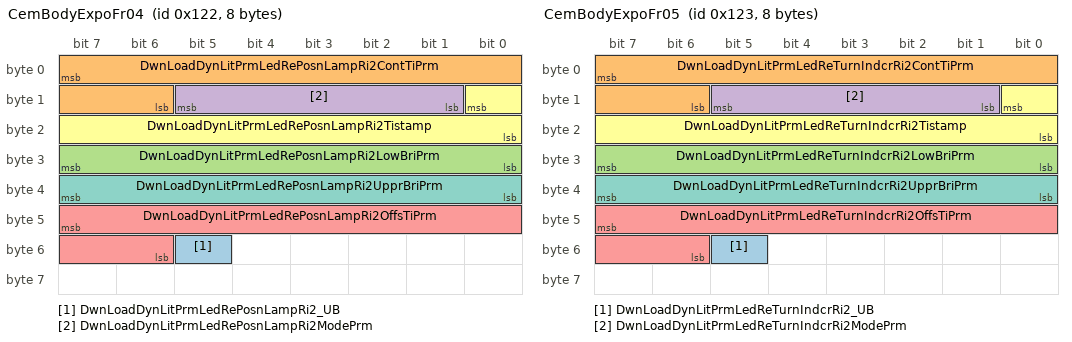
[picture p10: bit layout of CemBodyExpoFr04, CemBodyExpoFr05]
BO_ 290 CemBodyExpoFr04 : 8 CEM
 SG_ DwnLoadDynLitPrmLedRePosnLampRi2_UB : 53|1@0+ (1,0) [0|1] "" RCMM,RCMR
 SG_ DwnLoadDynLitPrmLedRePosnLampRi2ContTiPrm : 7|10@0+ (1.0,0.0) [0.0|1000.0] "Milliseconds" RCMM,RCMR
 SG_ DwnLoadDynLitPrmLedRePosnLampRi2LowBriPrm : 31|8@0+ (1.0,0.0) [0.0|100.0] "%" RCMM,RCMR
 SG_ DwnLoadDynLitPrmLedRePosnLampRi2ModePrm : 13|5@0+ (1,0) [0|31] "" RCMM,RCMR
 SG_ DwnLoadDynLitPrmLedRePosnLampRi2OffsTiPrm : 47|10@0+ (1.0,0.0) [0.0|1000.0] "Milliseconds" RCMM,RCMR
 SG_ DwnLoadDynLitPrmLedRePosnLampRi2Tistamp : 8|9@0+ (1.0,0.0) [0.0|511.0] "Unitless" RCMM,RCMR
 SG_ DwnLoadDynLitPrmLedRePosnLampRi2UpprBriPrm : 39|8@0+ (1.0,0.0) [0.0|100.0] "%" RCMM,RCMR

BO_ 291 CemBodyExpoFr05 : 8 CEM
 SG_ DwnLoadDynLitPrmLedReTurnIndcrRi2_UB : 53|1@0+ (1,0) [0|1] "" RCMM,RCMR
 SG_ DwnLoadDynLitPrmLedReTurnIndcrRi2ContTiPrm : 7|10@0+ (1.0,0.0) [0.0|1000.0] "Milliseconds" RCMM,RCMR
 SG_ DwnLoadDynLitPrmLedReTurnIndcrRi2LowBriPrm : 31|8@0+ (1.0,0.0) [0.0|100.0] "%" RCMM,RCMR
 SG_ DwnLoadDynLitPrmLedReTurnIndcrRi2ModePrm : 13|5@0+ (1,0) [0|31] "" RCMM,RCMR
 SG_ DwnLoadDynLitPrmLedReTurnIndcrRi2OffsTiPrm : 47|10@0+ (1.0,0.0) [0.0|1000.0] "Milliseconds" RCMM,RCMR
 SG_ DwnLoadDynLitPrmLedReTurnIndcrRi2Tistamp : 8|9@0+ (1.0,0.0) [0.0|511.0] "Unitless" RCMM,RCMR
 SG_ DwnLoadDynLitPrmLedReTurnIndcrRi2UpprBriPrm : 39|8@0+ (1.0,0.0) [0.0|100.0] "%" RCMM,RCMR

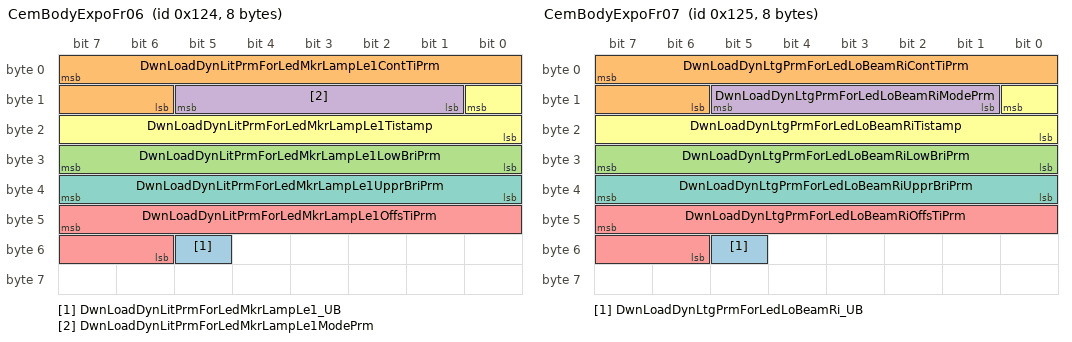
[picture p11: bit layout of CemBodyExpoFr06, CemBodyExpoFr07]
BO_ 292 CemBodyExpoFr06 : 8 CEM
 SG_ DwnLoadDynLitPrmForLedMkrLampLe1_UB : 53|1@0+ (1,0) [0|1] "" RCML
 SG_ DwnLoadDynLitPrmForLedMkrLampLe1ContTiPrm : 7|10@0+ (1.0,0.0) [0.0|1000.0] "Milliseconds" RCML
 SG_ DwnLoadDynLitPrmForLedMkrLampLe1LowBriPrm : 31|8@0+ (1.0,0.0) [0.0|100.0] "%" RCML
 SG_ DwnLoadDynLitPrmForLedMkrLampLe1ModePrm : 13|5@0+ (1,0) [0|31] "" RCML
 SG_ DwnLoadDynLitPrmForLedMkrLampLe1OffsTiPrm : 47|10@0+ (1.0,0.0) [0.0|1000.0] "Milliseconds" RCML
 SG_ DwnLoadDynLitPrmForLedMkrLampLe1Tistamp : 8|9@0+ (1.0,0.0) [0.0|511.0] "Unitless" RCML
 SG_ DwnLoadDynLitPrmForLedMkrLampLe1UpprBriPrm : 39|8@0+ (1.0,0.0) [0.0|100.0] "%" RCML

BO_ 293 CemBodyExpoFr07 : 8 CEM
 SG_ DwnLoadDynLtgPrmForLedLoBeamRi_UB : 53|1@0+ (1,0) [0|1] "" HCMR
 SG_ DwnLoadDynLtgPrmForLedLoBeamRiContTiPrm : 7|10@0+ (1.0,0.0) [0.0|1000.0] "Milliseconds" HCMR
 SG_ DwnLoadDynLtgPrmForLedLoBeamRiLowBriPrm : 31|8@0+ (1.0,0.0) [0.0|100.0] "%" HCMR
 SG_ DwnLoadDynLtgPrmForLedLoBeamRiModePrm : 13|5@0+ (1,0) [0|31] "" HCMR
 SG_ DwnLoadDynLtgPrmForLedLoBeamRiOffsTiPrm : 47|10@0+ (1.0,0.0) [0.0|1000.0] "Milliseconds" HCMR
 SG_ DwnLoadDynLtgPrmForLedLoBeamRiTistamp : 8|9@0+ (1.0,0.0) [0.0|511.0] "Unitless" HCMR
 SG_ DwnLoadDynLtgPrmForLedLoBeamRiUpprBriPrm : 39|8@0+ (1.0,0.0) [0.0|100.0] "%" HCMR

BO_ 294 CemBodyExpoFr08 : 8 CEM
 SG_ DwnLoadDynLitPrmForLedMkrLampLe2_UB : 53|1@0+ (1,0) [0|1] "" RCML,RCMM
 SG_ DwnLoadDynLitPrmForLedMkrLampLe2ContTiPrm : 7|10@0+ (1.0,0.0) [0.0|1000.0] "Milliseconds" RCML,RCMM
 SG_ DwnLoadDynLitPrmForLedMkrLampLe2LowBriPrm : 31|8@0+ (1.0,0.0) [0.0|100.0] "%" RCML,RCMM
 SG_ DwnLoadDynLitPrmForLedMkrLampLe2ModePrm : 13|5@0+ (1,0) [0|31] "" RCML,RCMM
 SG_ DwnLoadDynLitPrmForLedMkrLampLe2OffsTiPrm : 47|10@0+ (1.0,0.0) [0.0|1000.0] "Milliseconds" RCML,RCMM
 SG_ DwnLoadDynLitPrmForLedMkrLampLe2Tistamp : 8|9@0+ (1.0,0.0) [0.0|511.0] "Unitless" RCML,RCMM
 SG_ DwnLoadDynLitPrmForLedMkrLampLe2UpprBriPrm : 39|8@0+ (1.0,0.0) [0.0|100.0] "%" RCML,RCMM

BO_ 295 CemBodyExpoFr09 : 8 CEM
 SG_ DwnLoadDynLitPrmForLedMkrLampRi1_UB : 53|1@0+ (1,0) [0|1] "" RCMR
 SG_ DwnLoadDynLitPrmForLedMkrLampRi1ContTiPrm : 7|10@0+ (1.0,0.0) [0.0|1000.0] "Milliseconds" RCMR
 SG_ DwnLoadDynLitPrmForLedMkrLampRi1LowBriPrm : 31|8@0+ (1.0,0.0) [0.0|100.0] "%" RCMR
 SG_ DwnLoadDynLitPrmForLedMkrLampRi1ModePrm : 13|5@0+ (1,0) [0|31] "" RCMR
 SG_ DwnLoadDynLitPrmForLedMkrLampRi1OffsTiPrm : 47|10@0+ (1.0,0.0) [0.0|1000.0] "Milliseconds" RCMR
 SG_ DwnLoadDynLitPrmForLedMkrLampRi1Tistamp : 8|9@0+ (1.0,0.0) [0.0|511.0] "Unitless" RCMR
 SG_ DwnLoadDynLitPrmForLedMkrLampRi1UpprBriPrm : 39|8@0+ (1.0,0.0) [0.0|100.0] "%" RCMR

BO_ 296 CemBodyExpoFr10 : 8 CEM
 SG_ DwnLoadDynLitPrmForLedStopLampLe1_UB : 53|1@0+ (1,0) [0|1] "" RCML
 SG_ DwnLoadDynLitPrmForLedStopLampLe1ContTiPrm : 7|10@0+ (1.0,0.0) [0.0|1000.0] "Milliseconds" RCML
 SG_ DwnLoadDynLitPrmForLedStopLampLe1LowBriPrm : 31|8@0+ (1.0,0.0) [0.0|100.0] "%" RCML
 SG_ DwnLoadDynLitPrmForLedStopLampLe1ModePrm : 13|5@0+ (1,0) [0|31] "" RCML
 SG_ DwnLoadDynLitPrmForLedStopLampLe1OffsTiPrm : 47|10@0+ (1.0,0.0) [0.0|1000.0] "Milliseconds" RCML
 SG_ DwnLoadDynLitPrmForLedStopLampLe1Tistamp : 8|9@0+ (1.0,0.0) [0.0|511.0] "Unitless" RCML
 SG_ DwnLoadDynLitPrmForLedStopLampLe1UpprBriPrm : 39|8@0+ (1.0,0.0) [0.0|100.0] "%" RCML

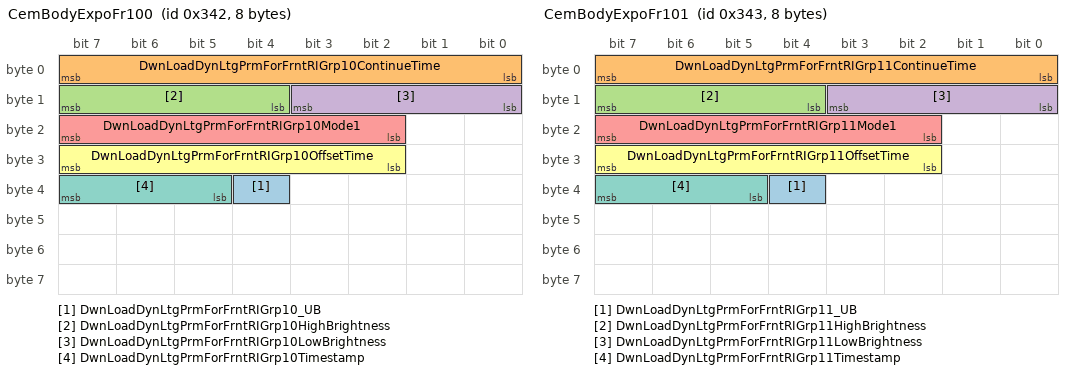
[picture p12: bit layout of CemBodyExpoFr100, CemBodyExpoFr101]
BO_ 834 CemBodyExpoFr100 : 8 CEM
 SG_ DwnLoadDynLtgPrmForFrntRIGrp10_UB : 36|1@0+ (1,0) [0|1] "" HCMR
 SG_ DwnLoadDynLtgPrmForFrntRIGrp10ContinueTime : 7|8@0+ (1.0,0.0) [0.0|255.0] "Unitless" HCMR
 SG_ DwnLoadDynLtgPrmForFrntRIGrp10HighBrightness : 15|4@0+ (1.0,0.0) [0.0|10.0] "Unitless" HCMR
 SG_ DwnLoadDynLtgPrmForFrntRIGrp10LowBrightness : 11|4@0+ (1.0,0.0) [0.0|10.0] "Unitless" HCMR
 SG_ DwnLoadDynLtgPrmForFrntRIGrp10Mode1 : 23|6@0+ (1,0) [0|63] "" HCMR
 SG_ DwnLoadDynLtgPrmForFrntRIGrp10OffsetTime : 31|6@0+ (1.0,0.0) [0.0|63.0] "Unitless" HCMR
 SG_ DwnLoadDynLtgPrmForFrntRIGrp10Timestamp : 39|3@0+ (1.0,0.0) [0.0|7.0] "Unitless" HCMR

BO_ 835 CemBodyExpoFr101 : 8 CEM
 SG_ DwnLoadDynLtgPrmForFrntRIGrp11_UB : 36|1@0+ (1,0) [0|1] "" HCMR
 SG_ DwnLoadDynLtgPrmForFrntRIGrp11ContinueTime : 7|8@0+ (1.0,0.0) [0.0|255.0] "Unitless" HCMR
 SG_ DwnLoadDynLtgPrmForFrntRIGrp11HighBrightness : 15|4@0+ (1.0,0.0) [0.0|10.0] "Unitless" HCMR
 SG_ DwnLoadDynLtgPrmForFrntRIGrp11LowBrightness : 11|4@0+ (1.0,0.0) [0.0|10.0] "Unitless" HCMR
 SG_ DwnLoadDynLtgPrmForFrntRIGrp11Mode1 : 23|6@0+ (1,0) [0|63] "" HCMR
 SG_ DwnLoadDynLtgPrmForFrntRIGrp11OffsetTime : 31|6@0+ (1.0,0.0) [0.0|63.0] "Unitless" HCMR
 SG_ DwnLoadDynLtgPrmForFrntRIGrp11Timestamp : 39|3@0+ (1.0,0.0) [0.0|7.0] "Unitless" HCMR

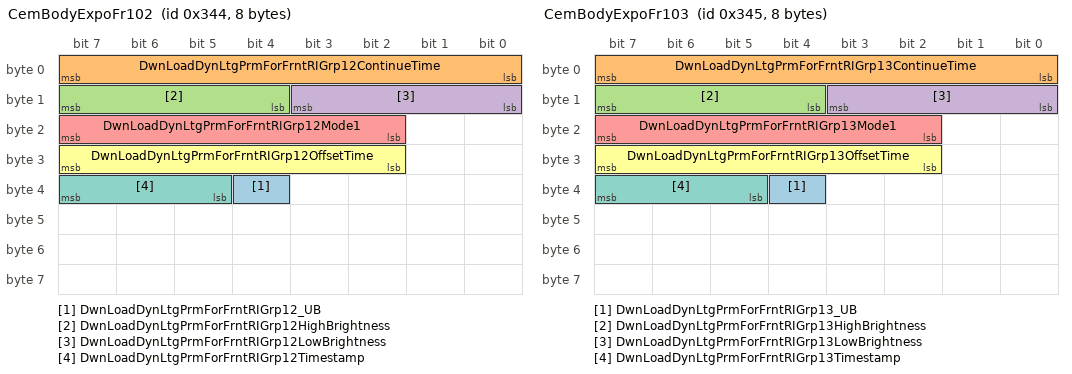
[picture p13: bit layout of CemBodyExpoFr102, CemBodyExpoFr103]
BO_ 836 CemBodyExpoFr102 : 8 CEM
 SG_ DwnLoadDynLtgPrmForFrntRIGrp12_UB : 36|1@0+ (1,0) [0|1] "" HCMR
 SG_ DwnLoadDynLtgPrmForFrntRIGrp12ContinueTime : 7|8@0+ (1.0,0.0) [0.0|255.0] "Unitless" HCMR
 SG_ DwnLoadDynLtgPrmForFrntRIGrp12HighBrightness : 15|4@0+ (1.0,0.0) [0.0|10.0] "Unitless" HCMR
 SG_ DwnLoadDynLtgPrmForFrntRIGrp12LowBrightness : 11|4@0+ (1.0,0.0) [0.0|10.0] "Unitless" HCMR
 SG_ DwnLoadDynLtgPrmForFrntRIGrp12Mode1 : 23|6@0+ (1,0) [0|63] "" HCMR
 SG_ DwnLoadDynLtgPrmForFrntRIGrp12OffsetTime : 31|6@0+ (1.0,0.0) [0.0|63.0] "Unitless" HCMR
 SG_ DwnLoadDynLtgPrmForFrntRIGrp12Timestamp : 39|3@0+ (1.0,0.0) [0.0|7.0] "Unitless" HCMR

BO_ 837 CemBodyExpoFr103 : 8 CEM
 SG_ DwnLoadDynLtgPrmForFrntRIGrp13_UB : 36|1@0+ (1,0) [0|1] "" HCMR
 SG_ DwnLoadDynLtgPrmForFrntRIGrp13ContinueTime : 7|8@0+ (1.0,0.0) [0.0|255.0] "Unitless" HCMR
 SG_ DwnLoadDynLtgPrmForFrntRIGrp13HighBrightness : 15|4@0+ (1.0,0.0) [0.0|10.0] "Unitless" HCMR
 SG_ DwnLoadDynLtgPrmForFrntRIGrp13LowBrightness : 11|4@0+ (1.0,0.0) [0.0|10.0] "Unitless" HCMR
 SG_ DwnLoadDynLtgPrmForFrntRIGrp13Mode1 : 23|6@0+ (1,0) [0|63] "" HCMR
 SG_ DwnLoadDynLtgPrmForFrntRIGrp13OffsetTime : 31|6@0+ (1.0,0.0) [0.0|63.0] "Unitless" HCMR
 SG_ DwnLoadDynLtgPrmForFrntRIGrp13Timestamp : 39|3@0+ (1.0,0.0) [0.0|7.0] "Unitless" HCMR

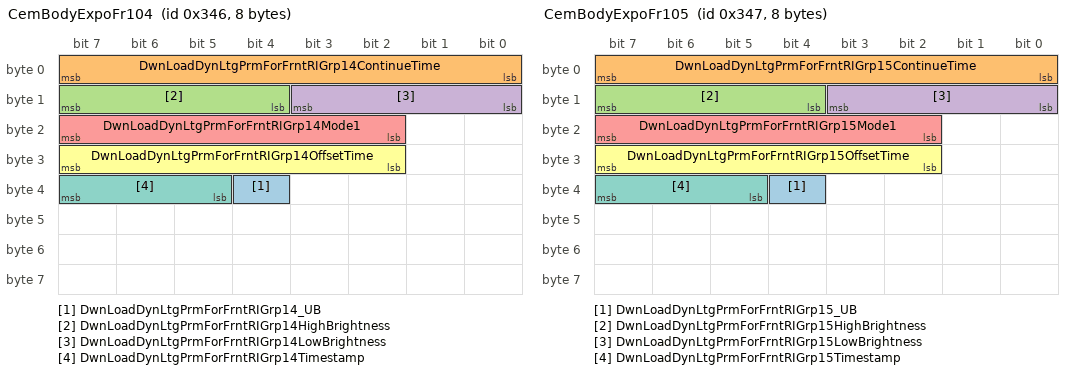
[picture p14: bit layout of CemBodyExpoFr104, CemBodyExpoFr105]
BO_ 838 CemBodyExpoFr104 : 8 CEM
 SG_ DwnLoadDynLtgPrmForFrntRIGrp14_UB : 36|1@0+ (1,0) [0|1] "" HCMR
 SG_ DwnLoadDynLtgPrmForFrntRIGrp14ContinueTime : 7|8@0+ (1.0,0.0) [0.0|255.0] "Unitless" HCMR
 SG_ DwnLoadDynLtgPrmForFrntRIGrp14HighBrightness : 15|4@0+ (1.0,0.0) [0.0|10.0] "Unitless" HCMR
 SG_ DwnLoadDynLtgPrmForFrntRIGrp14LowBrightness : 11|4@0+ (1.0,0.0) [0.0|10.0] "Unitless" HCMR
 SG_ DwnLoadDynLtgPrmForFrntRIGrp14Mode1 : 23|6@0+ (1,0) [0|63] "" HCMR
 SG_ DwnLoadDynLtgPrmForFrntRIGrp14OffsetTime : 31|6@0+ (1.0,0.0) [0.0|63.0] "Unitless" HCMR
 SG_ DwnLoadDynLtgPrmForFrntRIGrp14Timestamp : 39|3@0+ (1.0,0.0) [0.0|7.0] "Unitless" HCMR

BO_ 839 CemBodyExpoFr105 : 8 CEM
 SG_ DwnLoadDynLtgPrmForFrntRIGrp15_UB : 36|1@0+ (1,0) [0|1] "" HCMR
 SG_ DwnLoadDynLtgPrmForFrntRIGrp15ContinueTime : 7|8@0+ (1.0,0.0) [0.0|255.0] "Unitless" HCMR
 SG_ DwnLoadDynLtgPrmForFrntRIGrp15HighBrightness : 15|4@0+ (1.0,0.0) [0.0|10.0] "Unitless" HCMR
 SG_ DwnLoadDynLtgPrmForFrntRIGrp15LowBrightness : 11|4@0+ (1.0,0.0) [0.0|10.0] "Unitless" HCMR
 SG_ DwnLoadDynLtgPrmForFrntRIGrp15Mode1 : 23|6@0+ (1,0) [0|63] "" HCMR
 SG_ DwnLoadDynLtgPrmForFrntRIGrp15OffsetTime : 31|6@0+ (1.0,0.0) [0.0|63.0] "Unitless" HCMR
 SG_ DwnLoadDynLtgPrmForFrntRIGrp15Timestamp : 39|3@0+ (1.0,0.0) [0.0|7.0] "Unitless" HCMR

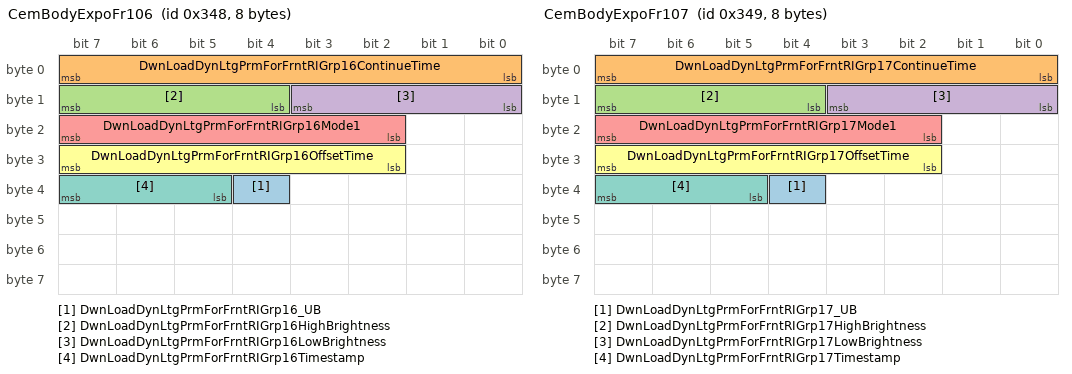
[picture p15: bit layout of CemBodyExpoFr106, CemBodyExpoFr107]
BO_ 840 CemBodyExpoFr106 : 8 CEM
 SG_ DwnLoadDynLtgPrmForFrntRIGrp16_UB : 36|1@0+ (1,0) [0|1] "" HCMR
 SG_ DwnLoadDynLtgPrmForFrntRIGrp16ContinueTime : 7|8@0+ (1.0,0.0) [0.0|255.0] "Unitless" HCMR
 SG_ DwnLoadDynLtgPrmForFrntRIGrp16HighBrightness : 15|4@0+ (1.0,0.0) [0.0|10.0] "Unitless" HCMR
 SG_ DwnLoadDynLtgPrmForFrntRIGrp16LowBrightness : 11|4@0+ (1.0,0.0) [0.0|10.0] "Unitless" HCMR
 SG_ DwnLoadDynLtgPrmForFrntRIGrp16Mode1 : 23|6@0+ (1,0) [0|63] "" HCMR
 SG_ DwnLoadDynLtgPrmForFrntRIGrp16OffsetTime : 31|6@0+ (1.0,0.0) [0.0|63.0] "Unitless" HCMR
 SG_ DwnLoadDynLtgPrmForFrntRIGrp16Timestamp : 39|3@0+ (1.0,0.0) [0.0|7.0] "Unitless" HCMR

BO_ 841 CemBodyExpoFr107 : 8 CEM
 SG_ DwnLoadDynLtgPrmForFrntRIGrp17_UB : 36|1@0+ (1,0) [0|1] "" HCMR
 SG_ DwnLoadDynLtgPrmForFrntRIGrp17ContinueTime : 7|8@0+ (1.0,0.0) [0.0|255.0] "Unitless" HCMR
 SG_ DwnLoadDynLtgPrmForFrntRIGrp17HighBrightness : 15|4@0+ (1.0,0.0) [0.0|10.0] "Unitless" HCMR
 SG_ DwnLoadDynLtgPrmForFrntRIGrp17LowBrightness : 11|4@0+ (1.0,0.0) [0.0|10.0] "Unitless" HCMR
 SG_ DwnLoadDynLtgPrmForFrntRIGrp17Mode1 : 23|6@0+ (1,0) [0|63] "" HCMR
 SG_ DwnLoadDynLtgPrmForFrntRIGrp17OffsetTime : 31|6@0+ (1.0,0.0) [0.0|63.0] "Unitless" HCMR
 SG_ DwnLoadDynLtgPrmForFrntRIGrp17Timestamp : 39|3@0+ (1.0,0.0) [0.0|7.0] "Unitless" HCMR

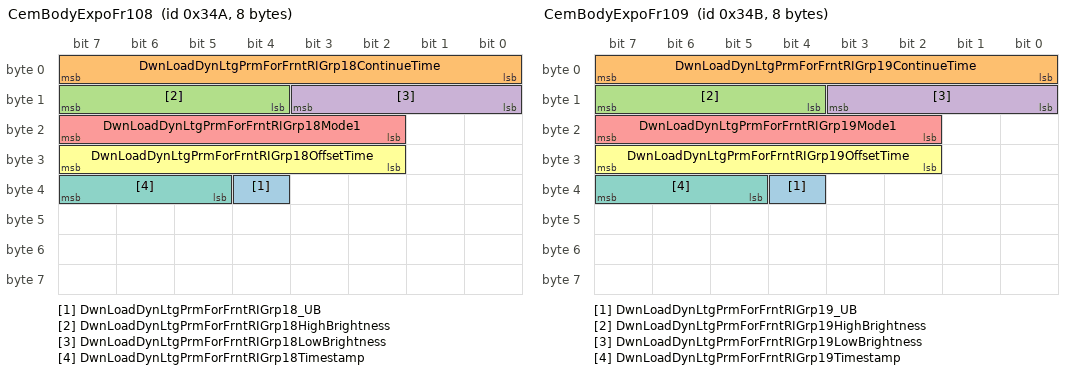
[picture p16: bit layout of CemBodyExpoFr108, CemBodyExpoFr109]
BO_ 842 CemBodyExpoFr108 : 8 CEM
 SG_ DwnLoadDynLtgPrmForFrntRIGrp18_UB : 36|1@0+ (1,0) [0|1] "" HCMR
 SG_ DwnLoadDynLtgPrmForFrntRIGrp18ContinueTime : 7|8@0+ (1.0,0.0) [0.0|255.0] "Unitless" HCMR
 SG_ DwnLoadDynLtgPrmForFrntRIGrp18HighBrightness : 15|4@0+ (1.0,0.0) [0.0|10.0] "Unitless" HCMR
 SG_ DwnLoadDynLtgPrmForFrntRIGrp18LowBrightness : 11|4@0+ (1.0,0.0) [0.0|10.0] "Unitless" HCMR
 SG_ DwnLoadDynLtgPrmForFrntRIGrp18Mode1 : 23|6@0+ (1,0) [0|63] "" HCMR
 SG_ DwnLoadDynLtgPrmForFrntRIGrp18OffsetTime : 31|6@0+ (1.0,0.0) [0.0|63.0] "Unitless" HCMR
 SG_ DwnLoadDynLtgPrmForFrntRIGrp18Timestamp : 39|3@0+ (1.0,0.0) [0.0|7.0] "Unitless" HCMR

BO_ 843 CemBodyExpoFr109 : 8 CEM
 SG_ DwnLoadDynLtgPrmForFrntRIGrp19_UB : 36|1@0+ (1,0) [0|1] "" HCMR
 SG_ DwnLoadDynLtgPrmForFrntRIGrp19ContinueTime : 7|8@0+ (1.0,0.0) [0.0|255.0] "Unitless" HCMR
 SG_ DwnLoadDynLtgPrmForFrntRIGrp19HighBrightness : 15|4@0+ (1.0,0.0) [0.0|10.0] "Unitless" HCMR
 SG_ DwnLoadDynLtgPrmForFrntRIGrp19LowBrightness : 11|4@0+ (1.0,0.0) [0.0|10.0] "Unitless" HCMR
 SG_ DwnLoadDynLtgPrmForFrntRIGrp19Mode1 : 23|6@0+ (1,0) [0|63] "" HCMR
 SG_ DwnLoadDynLtgPrmForFrntRIGrp19OffsetTime : 31|6@0+ (1.0,0.0) [0.0|63.0] "Unitless" HCMR
 SG_ DwnLoadDynLtgPrmForFrntRIGrp19Timestamp : 39|3@0+ (1.0,0.0) [0.0|7.0] "Unitless" HCMR

BO_ 297 CemBodyExpoFr11 : 8 CEM
 SG_ DwnLoadDynLitPrmForLedStopLampLe2_UB : 53|1@0+ (1,0) [0|1] "" RCML,RCMM
 SG_ DwnLoadDynLitPrmForLedStopLampLe2ContTiPrm : 7|10@0+ (1.0,0.0) [0.0|1000.0] "Milliseconds" RCML,RCMM
 SG_ DwnLoadDynLitPrmForLedStopLampLe2LowBriPrm : 31|8@0+ (1.0,0.0) [0.0|100.0] "%" RCML,RCMM
 SG_ DwnLoadDynLitPrmForLedStopLampLe2ModePrm : 13|5@0+ (1,0) [0|31] "" RCML,RCMM
 SG_ DwnLoadDynLitPrmForLedStopLampLe2OffsTiPrm : 47|10@0+ (1.0,0.0) [0.0|1000.0] "Milliseconds" RCML,RCMM
 SG_ DwnLoadDynLitPrmForLedStopLampLe2Tistamp : 8|9@0+ (1.0,0.0) [0.0|511.0] "Unitless" RCML,RCMM
 SG_ DwnLoadDynLitPrmForLedStopLampLe2UpprBriPrm : 39|8@0+ (1.0,0.0) [0.0|100.0] "%" RCML,RCMM

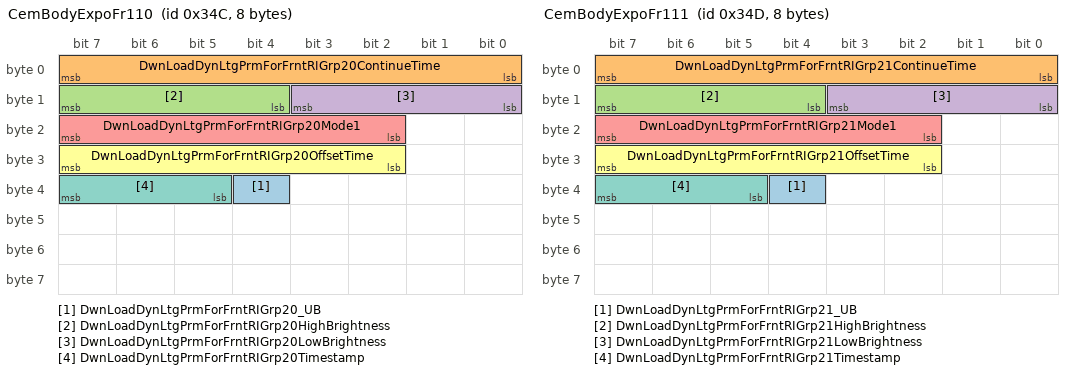
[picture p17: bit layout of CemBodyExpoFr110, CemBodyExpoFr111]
BO_ 844 CemBodyExpoFr110 : 8 CEM
 SG_ DwnLoadDynLtgPrmForFrntRIGrp20_UB : 36|1@0+ (1,0) [0|1] "" HCMR
 SG_ DwnLoadDynLtgPrmForFrntRIGrp20ContinueTime : 7|8@0+ (1.0,0.0) [0.0|255.0] "Unitless" HCMR
 SG_ DwnLoadDynLtgPrmForFrntRIGrp20HighBrightness : 15|4@0+ (1.0,0.0) [0.0|10.0] "Unitless" HCMR
 SG_ DwnLoadDynLtgPrmForFrntRIGrp20LowBrightness : 11|4@0+ (1.0,0.0) [0.0|10.0] "Unitless" HCMR
 SG_ DwnLoadDynLtgPrmForFrntRIGrp20Mode1 : 23|6@0+ (1,0) [0|63] "" HCMR
 SG_ DwnLoadDynLtgPrmForFrntRIGrp20OffsetTime : 31|6@0+ (1.0,0.0) [0.0|63.0] "Unitless" HCMR
 SG_ DwnLoadDynLtgPrmForFrntRIGrp20Timestamp : 39|3@0+ (1.0,0.0) [0.0|7.0] "Unitless" HCMR

BO_ 845 CemBodyExpoFr111 : 8 CEM
 SG_ DwnLoadDynLtgPrmForFrntRIGrp21_UB : 36|1@0+ (1,0) [0|1] "" HCMR
 SG_ DwnLoadDynLtgPrmForFrntRIGrp21ContinueTime : 7|8@0+ (1.0,0.0) [0.0|255.0] "Unitless" HCMR
 SG_ DwnLoadDynLtgPrmForFrntRIGrp21HighBrightness : 15|4@0+ (1.0,0.0) [0.0|10.0] "Unitless" HCMR
 SG_ DwnLoadDynLtgPrmForFrntRIGrp21LowBrightness : 11|4@0+ (1.0,0.0) [0.0|10.0] "Unitless" HCMR
 SG_ DwnLoadDynLtgPrmForFrntRIGrp21Mode1 : 23|6@0+ (1,0) [0|63] "" HCMR
 SG_ DwnLoadDynLtgPrmForFrntRIGrp21OffsetTime : 31|6@0+ (1.0,0.0) [0.0|63.0] "Unitless" HCMR
 SG_ DwnLoadDynLtgPrmForFrntRIGrp21Timestamp : 39|3@0+ (1.0,0.0) [0.0|7.0] "Unitless" HCMR

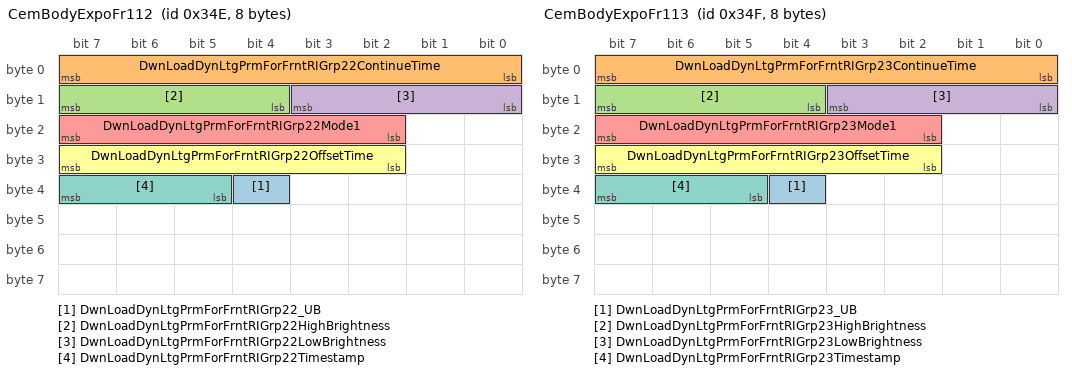
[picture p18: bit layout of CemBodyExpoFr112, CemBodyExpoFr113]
BO_ 846 CemBodyExpoFr112 : 8 CEM
 SG_ DwnLoadDynLtgPrmForFrntRIGrp22_UB : 36|1@0+ (1,0) [0|1] "" HCMR
 SG_ DwnLoadDynLtgPrmForFrntRIGrp22ContinueTime : 7|8@0+ (1.0,0.0) [0.0|255.0] "Unitless" HCMR
 SG_ DwnLoadDynLtgPrmForFrntRIGrp22HighBrightness : 15|4@0+ (1.0,0.0) [0.0|10.0] "Unitless" HCMR
 SG_ DwnLoadDynLtgPrmForFrntRIGrp22LowBrightness : 11|4@0+ (1.0,0.0) [0.0|10.0] "Unitless" HCMR
 SG_ DwnLoadDynLtgPrmForFrntRIGrp22Mode1 : 23|6@0+ (1,0) [0|63] "" HCMR
 SG_ DwnLoadDynLtgPrmForFrntRIGrp22OffsetTime : 31|6@0+ (1.0,0.0) [0.0|63.0] "Unitless" HCMR
 SG_ DwnLoadDynLtgPrmForFrntRIGrp22Timestamp : 39|3@0+ (1.0,0.0) [0.0|7.0] "Unitless" HCMR

BO_ 847 CemBodyExpoFr113 : 8 CEM
 SG_ DwnLoadDynLtgPrmForFrntRIGrp23_UB : 36|1@0+ (1,0) [0|1] "" HCMR
 SG_ DwnLoadDynLtgPrmForFrntRIGrp23ContinueTime : 7|8@0+ (1.0,0.0) [0.0|255.0] "Unitless" HCMR
 SG_ DwnLoadDynLtgPrmForFrntRIGrp23HighBrightness : 15|4@0+ (1.0,0.0) [0.0|10.0] "Unitless" HCMR
 SG_ DwnLoadDynLtgPrmForFrntRIGrp23LowBrightness : 11|4@0+ (1.0,0.0) [0.0|10.0] "Unitless" HCMR
 SG_ DwnLoadDynLtgPrmForFrntRIGrp23Mode1 : 23|6@0+ (1,0) [0|63] "" HCMR
 SG_ DwnLoadDynLtgPrmForFrntRIGrp23OffsetTime : 31|6@0+ (1.0,0.0) [0.0|63.0] "Unitless" HCMR
 SG_ DwnLoadDynLtgPrmForFrntRIGrp23Timestamp : 39|3@0+ (1.0,0.0) [0.0|7.0] "Unitless" HCMR

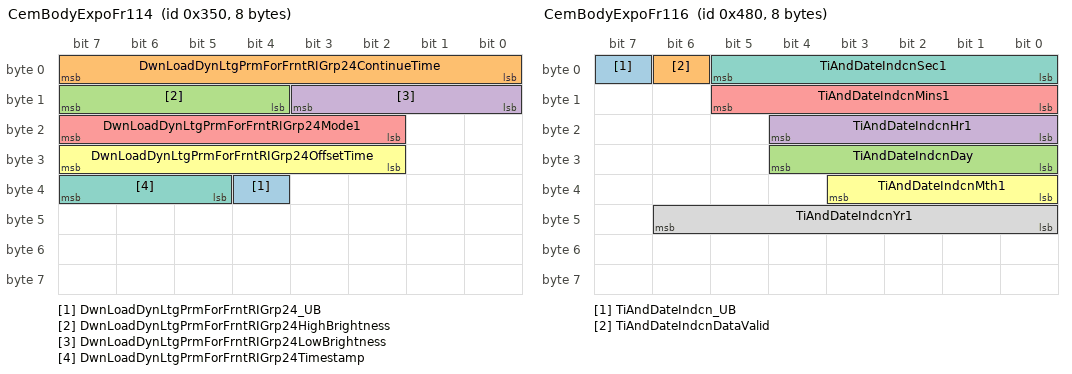
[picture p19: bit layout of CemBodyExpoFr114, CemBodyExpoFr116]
BO_ 848 CemBodyExpoFr114 : 8 CEM
 SG_ DwnLoadDynLtgPrmForFrntRIGrp24_UB : 36|1@0+ (1,0) [0|1] "" HCMR
 SG_ DwnLoadDynLtgPrmForFrntRIGrp24ContinueTime : 7|8@0+ (1.0,0.0) [0.0|255.0] "Unitless" HCMR
 SG_ DwnLoadDynLtgPrmForFrntRIGrp24HighBrightness : 15|4@0+ (1.0,0.0) [0.0|10.0] "Unitless" HCMR
 SG_ DwnLoadDynLtgPrmForFrntRIGrp24LowBrightness : 11|4@0+ (1.0,0.0) [0.0|10.0] "Unitless" HCMR
 SG_ DwnLoadDynLtgPrmForFrntRIGrp24Mode1 : 23|6@0+ (1,0) [0|63] "" HCMR
 SG_ DwnLoadDynLtgPrmForFrntRIGrp24OffsetTime : 31|6@0+ (1.0,0.0) [0.0|63.0] "Unitless" HCMR
 SG_ DwnLoadDynLtgPrmForFrntRIGrp24Timestamp : 39|3@0+ (1.0,0.0) [0.0|7.0] "Unitless" HCMR

BO_ 784 CemBodyExpoFr115 : 8 CEM
 SG_ ActvnOfADB : 1|1@0+ (1,0) [0|1] "" HCML,HCMR
 SG_ ActvnOfADB_UB : 0|1@0+ (1,0) [0|1] "" HCML,HCMR
 SG_ ActvnOfLiForComity : 7|1@0+ (1,0) [0|1] "" HCML,HCMR
 SG_ ActvnOfLiForComity_UB : 6|1@0+ (1,0) [0|1] "" HCML,HCMR
 SG_ ActvnOfLiForSpkr : 5|1@0+ (1,0) [0|1] "" HCML,HCMR
 SG_ ActvnOfLiForSpkr_UB : 4|1@0+ (1,0) [0|1] "" HCML,HCMR
 SG_ ActvnOfLiForWait : 3|1@0+ (1,0) [0|1] "" HCML,HCMR
 SG_ ActvnOfLiForWait_UB : 2|1@0+ (1,0) [0|1] "" HCML,HCMR
 SG_ CabPressPodCalc : 15|3@0+ (1,0) [0|7] "" Vector_XXX
 SG_ CabPressPodCalc_UB : 12|1@0+ (1,0) [0|1] "" Vector_XXX
 SG_ DoorDrvrLatPawlSt : 11|2@0+ (1,0) [0|3] "" Vector_XXX
 SG_ DoorDrvrLatPawlSt_UB : 9|1@0+ (1,0) [0|1] "" Vector_XXX
 SG_ DoorDrvrLatPosn : 31|2@0+ (1,0) [0|3] "" Vector_XXX
 SG_ DoorDrvrLatPosn_UB : 29|1@0+ (1,0) [0|1] "" Vector_XXX
 SG_ DoorLeReLatPawlSt : 23|2@0+ (1,0) [0|3] "" Vector_XXX
 SG_ DoorLeReLatPawlSt_UB : 21|1@0+ (1,0) [0|1] "" Vector_XXX
 SG_ DoorLeReLatPosn : 28|2@0+ (1,0) [0|3] "" Vector_XXX
 SG_ DoorLeReLatPosn_UB : 26|1@0+ (1,0) [0|1] "" Vector_XXX
 SG_ DoorPassLatPawlSt : 20|2@0+ (1,0) [0|3] "" Vector_XXX
 SG_ DoorPassLatPawlSt_UB : 18|1@0+ (1,0) [0|1] "" Vector_XXX
 SG_ DoorPassLatPosn : 25|2@0+ (1,0) [0|3] "" Vector_XXX
 SG_ DoorPassLatPosn_UB : 39|1@0+ (1,0) [0|1] "" Vector_XXX
 SG_ DoorRiReLatPawlSt : 17|2@0+ (1,0) [0|3] "" Vector_XXX
 SG_ DoorRiReLatPawlSt_UB : 8|1@0+ (1,0) [0|1] "" Vector_XXX
 SG_ DoorRiReLatPosn : 38|2@0+ (1,0) [0|3] "" Vector_XXX
 SG_ DoorRiReLatPosn_UB : 36|1@0+ (1,0) [0|1] "" Vector_XXX
 SG_ LockgCenSts_UB : 56|1@0+ (1,0) [0|1] "" Vector_XXX
 SG_ LockgCenStsLockSt : 59|2@0+ (1,0) [0|3] "" Vector_XXX
 SG_ LockgCenStsTrigSrc : 63|4@0+ (1,0) [0|15] "" Vector_XXX
 SG_ LockgCenStsUpdEve : 57|1@0+ (1,0) [0|1] "" Vector_XXX
 SG_ VehMtnSt_UB : 47|1@0+ (1,0) [0|1] "" Vector_XXX
 SG_ VehMtnStChks : 55|8@0+ (1.0,0.0) [0.0|255.0] "Unitless" Vector_XXX
 SG_ VehMtnStCntr : 46|4@0+ (1.0,0.0) [0.0|15.0] "Unitless" Vector_XXX
 SG_ VehMtnStVehMtnSt : 42|3@0+ (1,0) [0|7] "" Vector_XXX

BO_ 1152 CemBodyExpoFr116 : 8 CEM
 SG_ TiAndDateIndcn_UB : 7|1@0+ (1,0) [0|1] "" HCML,HCMR,RCML,RCMM,RCMR
 SG_ TiAndDateIndcnDataValid : 6|1@0+ (1,0) [0|1] "" HCML,HCMR,RCML,RCMM,RCMR
 SG_ TiAndDateIndcnDay : 28|5@0+ (1.0,0.0) [1.0|31.0] "Days" HCML,HCMR,RCML,RCMM,RCMR
 SG_ TiAndDateIndcnHr1 : 20|5@0+ (1.0,0.0) [0.0|23.0] "hours" HCML,HCMR,RCML,RCMM,RCMR
 SG_ TiAndDateIndcnMins1 : 13|6@0+ (1.0,0.0) [0.0|59.0] "Mins" HCML,HCMR,RCML,RCMM,RCMR
 SG_ TiAndDateIndcnMth1 : 35|4@0+ (1.0,0.0) [1.0|12.0] "Month" HCML,HCMR,RCML,RCMM,RCMR
 SG_ TiAndDateIndcnSec1 : 5|6@0+ (1.0,0.0) [0.0|59.0] "s" HCML,HCMR,RCML,RCMM,RCMR
 SG_ TiAndDateIndcnYr1 : 46|7@0+ (1.0,0.0) [0.0|99.0] "Year" HCML,HCMR,RCML,RCMM,RCMR

BO_ 361 CemBodyExpoFr117 : 8 CEM
 SG_ CarpetLiDownloadFinish : 58|1@0+ (1,0) [0|1] "" Vector_XXX
 SG_ CarpetLiDownloadFinish_UB : 56|1@0+ (1,0) [0|1] "" Vector_XXX
 SG_ CarpetLiDownloadReq : 57|1@0+ (1,0) [0|1] "" Vector_XXX
 SG_ CarpetLiDownloadReq_UB : 40|1@0+ (1,0) [0|1] "" Vector_XXX
 SG_ CarpetLiDowSwt : 60|1@0+ (1,0) [0|1] "" Vector_XXX
 SG_ CarpetLiDowSwt_UB : 59|1@0+ (1,0) [0|1] "" Vector_XXX
 SG_ DoorDrvrAutoManReq : 63|2@0+ (1,0) [0|3] "" Vector_XXX
 SG_ DoorDrvrAutoManReq_UB : 61|1@0+ (1,0) [0|1] "" Vector_XXX
 SG_ DoorOpenerDrvrReq_UB : 21|1@0+ (1,0) [0|1] "" Vector_XXX
 SG_ DoorOpenerDrvrReqChks : 7|8@0+ (1.0,0.0) [0.0|255.0] "Unitless" Vector_XXX
 SG_ DoorOpenerDrvrReqCntr : 15|4@0+ (1.0,0.0) [0.0|15.0] "Unitless" Vector_XXX
 SG_ DoorOpenerDrvrReqDoorOpenerReq : 23|2@0+ (1,0) [0|3] "" Vector_XXX
 SG_ DoorOpenerDrvrReqTrigSrc : 11|3@0+ (1,0) [0|7] "" Vector_XXX
 SG_ DoorOpenerLeReReq_UB : 45|1@0+ (1,0) [0|1] "" Vector_XXX
 SG_ DoorOpenerLeReReqChks : 31|8@0+ (1.0,0.0) [0.0|255.0] "Unitless" Vector_XXX
 SG_ DoorOpenerLeReReqCntr : 39|4@0+ (1.0,0.0) [0.0|15.0] "Unitless" Vector_XXX
 SG_ DoorOpenerLeReReqDoorOpenerReq : 47|2@0+ (1,0) [0|3] "" Vector_XXX
 SG_ DoorOpenerLeReReqTrigSrc : 35|3@0+ (1,0) [0|7] "" Vector_XXX
 SG_ OpenDrvrSwt : 20|1@0+ (1,0) [0|1] "" Vector_XXX
 SG_ OpenDrvrSwt_UB : 19|1@0+ (1,0) [0|1] "" Vector_XXX
 SG_ OpenLeReSwt : 18|1@0+ (1,0) [0|1] "" Vector_XXX
 SG_ OpenLeReSwt_UB : 17|1@0+ (1,0) [0|1] "" Vector_XXX
 SG_ OpenPassSwt : 44|1@0+ (1,0) [0|1] "" Vector_XXX
 SG_ OpenPassSwt_UB : 43|1@0+ (1,0) [0|1] "" Vector_XXX
 SG_ OpenRiReSwt : 42|1@0+ (1,0) [0|1] "" Vector_XXX
 SG_ OpenRiReSwt_UB : 41|1@0+ (1,0) [0|1] "" Vector_XXX
 SG_ PawlDrvrSwt : 55|1@0+ (1,0) [0|1] "" Vector_XXX
 SG_ PawlDrvrSwt_UB : 54|1@0+ (1,0) [0|1] "" Vector_XXX
 SG_ PawlLeReSwt : 53|1@0+ (1,0) [0|1] "" Vector_XXX
 SG_ PawlLeReSwt_UB : 52|1@0+ (1,0) [0|1] "" Vector_XXX
 SG_ PawlPassSwt : 51|1@0+ (1,0) [0|1] "" Vector_XXX
 SG_ PawlPassSwt_UB : 50|1@0+ (1,0) [0|1] "" Vector_XXX
 SG_ PawlRiReSwt : 49|1@0+ (1,0) [0|1] "" Vector_XXX
 SG_ PawlRiReSwt_UB : 48|1@0+ (1,0) [0|1] "" Vector_XXX

// Node Comments
CM_ BU_ CEM "Central Electronic Module";
CM_ BU_ ETC "External Tester Connector";
CM_ BU_ HCML "Headlamp Control Module Left";
CM_ BU_ HCMR "Headlamp Control Module Right";

// Signal Comments
CM_ SG_ 82 AutWinWipgCmd "Wiping speed command.";
CM_ SG_ 82 LiOprnMod "Information about day, night, twilight and tunnel detection.";
CM_ SG_ 82 SteerWhlSnsrAg "Actual steering wheel angle from the actual centre position of the steering wheel. ";
CM_ SG_ 82 SteerWhlSnsrAgSpd "Actual steering wheel angle from the actual centre position of the steering wheel. Steering angle speed with steering wheel rotation direction.  ";
CM_ SG_ 82 SteerWhlSnsrChks "Checksum for steering wheel sensor data.";
CM_ SG_ 82 SteerWhlSnsrCntr "Counter value for steering wheel sensor data.";
CM_ SG_ 82 SteerWhlSnsrQf "Qf for steering wheel sensor information";
CM_ SG_ 768 ActvnOfRvsg "Activation of Reverse Light";
CM_ SG_ 768 BrkPedlrRatPerc "Brake pedal Ratio in percentage value";
CM_ SG_ 768 BrkPedlrRatQf "quality factor";
CM_ SG_ 768 YawRateReqdByDrvr "When the vehicle is making a left turn this signal is supposed to show positive numbers. Unfiltered and offset compensated plausibility check";
CM_ SG_ 80 DoorPassSts "DoorPassSts - Passenger Door Status
Ukwn - Unknown status
Opend - Opened
Clsd - Closed";
CM_ SG_ 80 DoorRiReSts "DoorRiReSts - Right Rear Side Door Status
Ukwn - Unknown status
Opend - Opened
Clsd - Closed";
CM_ SG_ 80 VehSpdLgtA "Vehicle speed longitudinal based on wheel speed sensors and longitudinal acceleration.";
CM_ SG_ 80 VehSpdLgtChks "Checksum";
CM_ SG_ 80 VehSpdLgtCntr "Counter";
CM_ SG_ 80 VehSpdLgtQf "Quality factor for vehicle speed as measured by wheel speed sensors and longitudinal acceleration.";
CM_ SG_ 384 VehCfgPrmBlkIDBytePosn1 "signal block counter.";
CM_ SG_ 384 VehCfgPrmCCPBytePosn2 " (BlockID-1)*7 + 1. ";
CM_ SG_ 384 VehCfgPrmCCPBytePosn3 " (BlockID-1)*7 + 2. ";
CM_ SG_ 384 VehCfgPrmCCPBytePosn4 " (BlockID-1)*7 + 3. ";
CM_ SG_ 384 VehCfgPrmCCPBytePosn5 " (BlockID-1)*7 + 4. ";
CM_ SG_ 384 VehCfgPrmCCPBytePosn6 " (BlockID-1)*7 + 5. ";
CM_ SG_ 384 VehCfgPrmCCPBytePosn7 " (BlockID-1)*7 + 6. ";
CM_ SG_ 384 VehCfgPrmCCPBytePosn8 " (BlockID-1)*7 + 7. ";
CM_ SG_ 512 BkpOfDstTrvld "total traveled distance.";
CM_ SG_ 512 ExtrLiRlyPwrDwn "Informs HCMs about upcoming shut down of Exterior Light Relay.";
CM_ SG_ 512 VehBattUSysU "Vehicle System Voltage At 12V side";
CM_ SG_ 512 VehBattUSysUQf "Present vehicle voltage measured by CEM with QF";
CM_ SG_ 544 ActnOfLedFrntCrossLamp "Activate LED Front Middle Cross Lamp.";
CM_ SG_ 544 ActnOfLedGrilleLamp "Activate LED Front Grille Lamp.";
CM_ SG_ 544 ActnOfLedLeLogoLamp "Activate LED Left Logo Light Lamp.";
CM_ SG_ 544 ActnOfLedRiLogoLamp "Activate LED Right Logo Light Lamp.";
CM_ SG_ 544 Body2CntrForMissCom "Body Exposed detection for Diagnostic";
CM_ SG_ 544 CarTiGlb "Presents a tiime value that shall be used by all ECUs to time-stamp diagnsotic trouble codes (DTC) according to the requirements for Global DTC snapshot data.";
CM_ SG_ 544 TrSts "TrSts - Tailgate or Bootlid Status
Ukwn - Unknown status
Opend - Opened
Clsd - Closed";
CM_ SG_ 128 AccrPedlRatAccrPedlRat "Accelerator Pedal Position with adapted 0 point. Value as percentage of fully pressed pedal";
CM_ SG_ 128 AccrPedlRatChks "Accelerator Pedal Position with adapted 0 point. Value as percentage of fully pressed pedal. Checksum";
CM_ SG_ 128 AccrPedlRatCntr "Accelerator Pedal Position with adapted 0 point. Value as percentage of fully pressed pedal. Counter";
CM_ SG_ 128 AmbTRawAmbTVal "Unfiltered ambient temp raw data in deg C. Ambient temp value";
CM_ SG_ 128 AmbTRawQly "Unfiltered ambient temp raw data in deg C. Quality Factor of the ambient temp";
CM_ SG_ 128 BrkPedlSnsrChks "E2E protection, checksum. ";
CM_ SG_ 128 BrkPedlSnsrCntr "E2E protection, counter.";
CM_ SG_ 128 BrkPedlSnsrQf "Brake pedal state, quality factor";
CM_ SG_ 128 BrkPedlSnsrSt "brake pedal state, pressed or not pressed.";
CM_ SG_ 128 TooManyCars "Whether there are too many cars";
CM_ SG_ 387 VehCfgPrmExtBlkIDBytePosn1 "CarConfigExtended BlockID";
CM_ SG_ 387 VehCfgPrmExtCCPBytePosn2 "CarConfigExtended BytePos2";
CM_ SG_ 387 VehCfgPrmExtCCPBytePosn3 "CarConfigExtended BytePos3";
CM_ SG_ 387 VehCfgPrmExtCCPBytePosn4 "CarConfigExtended BytePos4";
CM_ SG_ 387 VehCfgPrmExtCCPBytePosn5 "CarConfigExtended BytePos5";
CM_ SG_ 387 VehCfgPrmExtCCPBytePosn6 "CarConfigExtended BytePos6";
CM_ SG_ 387 VehCfgPrmExtCCPBytePosn7 "CarConfigExtended BytePos7";
CM_ SG_ 387 VehCfgPrmExtCCPBytePosn8 "CarConfigExtended BytePos8";
CM_ SG_ 389 TrafficSignForADB1AdbAbsDist "refer to VehObjforADB1";
CM_ SG_ 389 TrafficSignForADB1AdbDetdQly "refer to VehObjforADB1";
CM_ SG_ 389 TrafficSignForADB1AdbHozlAgLe "refer to VehObjforADB1";
CM_ SG_ 389 TrafficSignForADB1AdbHozlAgRi "refer to VehObjforADB1";
CM_ SG_ 389 TrafficSignForADB1AdbTrkInfo "refer to VehObjforADB1";
CM_ SG_ 389 TrafficSignForADB1AdbVertAgBot "angle between ego vehicle camera and the bottom of object ";
CM_ SG_ 389 TrafficSignForADB1AdbVertAgTop "angle between ego vehicle camera and the top of object ";
CM_ SG_ 390 TrafficSignForADB2AdbAbsDist "refer to VehObjforADB1";
CM_ SG_ 390 TrafficSignForADB2AdbDetdQly "refer to VehObjforADB1";
CM_ SG_ 390 TrafficSignForADB2AdbHozlAgLe "refer to VehObjforADB1";
CM_ SG_ 390 TrafficSignForADB2AdbHozlAgRi "refer to VehObjforADB1";
CM_ SG_ 390 TrafficSignForADB2AdbTrkInfo "refer to VehObjforADB1";
CM_ SG_ 390 TrafficSignForADB2AdbVertAgBot "angle between ego vehicle camera and the bottom of object ";
CM_ SG_ 390 TrafficSignForADB2AdbVertAgTop "angle between ego vehicle camera and the top of object ";
CM_ SG_ 391 VehObjforAHBAdbAbsDist "refer to VehObjforADB1";
CM_ SG_ 391 VehObjforAHBAdbClassn "refer to VehObjforADB1";
CM_ SG_ 391 VehObjforAHBAdbClassnQly "refer to VehObjforADB1";
CM_ SG_ 391 VehObjforAHBAdbDetdQly "refer to VehObjforADB1";
CM_ SG_ 391 VehObjforAHBAdbHozlAg "refer to VehObjforADB1";
CM_ SG_ 391 VehObjforAHBAdbObjDir "refer to VehObjforADB1";
CM_ SG_ 391 VehObjforAHBAdbObjHozlAgSpd "refer to VehObjforADB1";
CM_ SG_ 391 VehObjforAHBAdbObjVertAgSpd "refer to VehObjforADB1";
CM_ SG_ 391 VehObjforAHBAdbTrkInfo "refer to VehObjforADB1";
CM_ SG_ 391 VehObjforAHBAdbVertAg "refer to VehObjforADB1";
CM_ SG_ 392 VehObjforADB1AdbAbsDist "Absolute distance between ego vehicle/camera and object";
CM_ SG_ 392 VehObjforADB1AdbClassn "Object Type";
CM_ SG_ 392 VehObjforADB1AdbHozlAgLe "horizontal angle between left of object front or tail lamp and the ego vehicle camera";
CM_ SG_ 392 VehObjforADB1AdbHozlAgRi "horizontal angle between right of object front or tail lamp and the ego vehicle camera";
CM_ SG_ 392 VehObjforADB1AdbObjDir "Object moving direction";
CM_ SG_ 392 VehObjforADB1AdbObjHozlAgSpdLe "Object left angle moving speed";
CM_ SG_ 392 VehObjforADB1AdbObjHozlAgSpdRi "Object right angle moving speed";
CM_ SG_ 392 VehObjforADB1AdbTrkInfo "Is the object a tracked one or a spontaneously occuring one";
CM_ SG_ 392 VehObjforADB1AdbVertAg "angle between ego vehicle camera and the bottom of object ";
CM_ SG_ 393 VehObjforADB2AdbAbsDist "Absolute distance between ego vehicle/camera and object";
CM_ SG_ 393 VehObjforADB2AdbClassn "Object Type";
CM_ SG_ 393 VehObjforADB2AdbHozlAgLe "horizontal angle between left of object front or tail lamp and the ego vehicle camera";
CM_ SG_ 393 VehObjforADB2AdbHozlAgRi "horizontal angle between right of object front or tail lamp and the ego vehicle camera";
CM_ SG_ 393 VehObjforADB2AdbObjDir "Object moving direction";
CM_ SG_ 393 VehObjforADB2AdbObjHozlAgSpdLe "Object left angle moving speed";
CM_ SG_ 393 VehObjforADB2AdbObjHozlAgSpdRi "Object right angle moving speed";
CM_ SG_ 393 VehObjforADB2AdbTrkInfo "Is the object a tracked one or a spontaneously occuring one";
CM_ SG_ 393 VehObjforADB2AdbVertAg "angle between ego vehicle camera and the bottom of object ";
CM_ SG_ 394 VehObjforADB3AdbAbsDist "Absolute distance between ego vehicle/camera and object";
CM_ SG_ 394 VehObjforADB3AdbClassn "Object Type";
CM_ SG_ 394 VehObjforADB3AdbHozlAgLe "horizontal angle between left of object front or tail lamp and the ego vehicle camera";
CM_ SG_ 394 VehObjforADB3AdbHozlAgRi "horizontal angle between right of object front or tail lamp and the ego vehicle camera";
CM_ SG_ 394 VehObjforADB3AdbObjDir "Object moving direction";
CM_ SG_ 394 VehObjforADB3AdbObjHozlAgSpdLe "Object left angle moving speed";
CM_ SG_ 394 VehObjforADB3AdbObjHozlAgSpdRi "Object right angle moving speed";
CM_ SG_ 394 VehObjforADB3AdbTrkInfo "Is the object a tracked one or a spontaneously occuring one";
CM_ SG_ 394 VehObjforADB3AdbVertAg "angle between ego vehicle camera and the bottom of object ";
CM_ SG_ 395 VehObjforADB4AdbAbsDist "Absolute distance between ego vehicle/camera and object";
CM_ SG_ 395 VehObjforADB4AdbClassn "Object Type";
CM_ SG_ 395 VehObjforADB4AdbHozlAgLe "horizontal angle between left of object front or tail lamp and the ego vehicle camera";
CM_ SG_ 395 VehObjforADB4AdbHozlAgRi "horizontal angle between right of object front or tail lamp and the ego vehicle camera";
CM_ SG_ 395 VehObjforADB4AdbObjDir "Object moving direction";
CM_ SG_ 395 VehObjforADB4AdbObjHozlAgSpdLe "Object left angle moving speed";
CM_ SG_ 395 VehObjforADB4AdbObjHozlAgSpdRi "Object right angle moving speed";
CM_ SG_ 395 VehObjforADB4AdbTrkInfo "Is the object a tracked one or a spontaneously occuring one";
CM_ SG_ 395 VehObjforADB4AdbVertAg "angle between ego vehicle camera and the bottom of object ";
CM_ SG_ 396 VehObjforADB5AdbAbsDist "Absolute distance between ego vehicle/camera and object";
CM_ SG_ 396 VehObjforADB5AdbClassn "Object Type";
CM_ SG_ 396 VehObjforADB5AdbHozlAgLe "horizontal angle between left of object front or tail lamp and the ego vehicle camera";
CM_ SG_ 396 VehObjforADB5AdbHozlAgRi "horizontal angle between right of object front or tail lamp and the ego vehicle camera";
CM_ SG_ 396 VehObjforADB5AdbObjDir "Object moving direction";
CM_ SG_ 396 VehObjforADB5AdbObjHozlAgSpdLe "Object left angle moving speed";
CM_ SG_ 396 VehObjforADB5AdbObjHozlAgSpdRi "Object right angle moving speed";
CM_ SG_ 396 VehObjforADB5AdbTrkInfo "Is the object a tracked one or a spontaneously occuring one";
CM_ SG_ 396 VehObjforADB5AdbVertAg "angle between ego vehicle camera and the bottom of object ";
CM_ SG_ 397 VehObjforADB6AdbAbsDist "Absolute distance between ego vehicle/camera and object";
CM_ SG_ 397 VehObjforADB6AdbClassn "Object Type";
CM_ SG_ 397 VehObjforADB6AdbHozlAgLe "horizontal angle between left of object front or tail lamp and the ego vehicle camera";
CM_ SG_ 397 VehObjforADB6AdbHozlAgRi "horizontal angle between right of object front or tail lamp and the ego vehicle camera";
CM_ SG_ 397 VehObjforADB6AdbObjDir "Object moving direction";
CM_ SG_ 397 VehObjforADB6AdbObjHozlAgSpdLe "Object left angle moving speed";
CM_ SG_ 397 VehObjforADB6AdbObjHozlAgSpdRi "Object right angle moving speed";
CM_ SG_ 397 VehObjforADB6AdbTrkInfo "Is the object a tracked one or a spontaneously occuring one";
CM_ SG_ 397 VehObjforADB6AdbVertAg "angle between ego vehicle camera and the bottom of object ";
CM_ SG_ 398 VehObjforADB7AdbAbsDist "Absolute distance between ego vehicle/camera and object";
CM_ SG_ 398 VehObjforADB7AdbClassn "Object Type";
CM_ SG_ 398 VehObjforADB7AdbHozlAgLe "horizontal angle between left of object front or tail lamp and the ego vehicle camera";
CM_ SG_ 398 VehObjforADB7AdbHozlAgRi "horizontal angle between right of object front or tail lamp and the ego vehicle camera";
CM_ SG_ 398 VehObjforADB7AdbObjDir "Object moving direction";
CM_ SG_ 398 VehObjforADB7AdbObjHozlAgSpdLe "Object left angle moving speed";
CM_ SG_ 398 VehObjforADB7AdbObjHozlAgSpdRi "Object right angle moving speed";
CM_ SG_ 398 VehObjforADB7AdbTrkInfo "Is the object a tracked one or a spontaneously occuring one";
CM_ SG_ 398 VehObjforADB7AdbVertAg "angle between ego vehicle camera and the bottom of object ";
CM_ SG_ 399 VehObjforADB8AdbAbsDist "Absolute distance between ego vehicle/camera and object";
CM_ SG_ 399 VehObjforADB8AdbClassn "Object Type";
CM_ SG_ 399 VehObjforADB8AdbHozlAgLe "horizontal angle between left of object front or tail lamp and the ego vehicle camera";
CM_ SG_ 399 VehObjforADB8AdbHozlAgRi "horizontal angle between right of object front or tail lamp and the ego vehicle camera";
CM_ SG_ 399 VehObjforADB8AdbObjDir "Object moving direction";
CM_ SG_ 399 VehObjforADB8AdbObjHozlAgSpdLe "Object left angle moving speed";
CM_ SG_ 399 VehObjforADB8AdbObjHozlAgSpdRi "Object right angle moving speed";
CM_ SG_ 399 VehObjforADB8AdbTrkInfo "Is the object a tracked one or a spontaneously occuring one";
CM_ SG_ 399 VehObjforADB8AdbVertAg "angle between ego vehicle camera and the bottom of object ";
CM_ SG_ 64 CameraStsforAHBC "To discribe camera can working or not.";
CM_ SG_ 64 RainLi "Information about rain detection for light activation/deactivation.";
CM_ SG_ 64 VehModMngtGlbSafe1CarModSts1 "CarMode Status";
CM_ SG_ 64 VehModMngtGlbSafe1CarModSubtypWdCarModSubtyp "CarMode substate status";
CM_ SG_ 64 VehModMngtGlbSafe1Chks "Checksum";
CM_ SG_ 64 VehModMngtGlbSafe1Cntr "Counter";
CM_ SG_ 64 VehModMngtGlbSafe1EgyLvlElecMai "Main energy level in the vehicle.";
CM_ SG_ 64 VehModMngtGlbSafe1EgyLvlElecSubtyp "Substate of the energy level in the vehicle.";
CM_ SG_ 64 VehModMngtGlbSafe1FltEgyCnsWdSts "High quiescent current detected by CEM via BMS.";
CM_ SG_ 64 VehModMngtGlbSafe1PwrLvlElecMai "Main Power level in the vehicle.";
CM_ SG_ 64 VehModMngtGlbSafe1PwrLvlElecSubtyp "Substate of the power level in the vehicle.";
CM_ SG_ 64 VehModMngtGlbSafe1UsgModSts "UsageMode Status";
CM_ SG_ 64 WipgAutFrntMod "Information regarding rain sensor operational mode.";
CM_ SG_ 400 SuspPosnVertAgGenQf "External CAN signal for inform the rear angle that are calculated from front and rear body height. This signal are used for head lamp control.";
CM_ SG_ 400 SuspPosnVertAgSuspPosnVertAg "External CAN signal for inform the rear angle that are calculated from front and rear body height. This signal are used for head lamp control.";
CM_ SG_ 400 SuspPosnVertLvlFrnt "Front suspension level";
CM_ SG_ 400 SuspPosnVertLvlFrntQf "Front Qf";
CM_ SG_ 400 SuspPosnVertLvlRe "Rear suspension level";
CM_ SG_ 400 SuspPosnVertLvlReQf "Rear Qf";
CM_ SG_ 1432 CEMdevelpsignalgrouprespFunctiondevpsignalgroup1 "develop signal group response";
CM_ SG_ 1432 CEMdevelpsignalgrouprespFunctiondevpsignalgroup2 "develop signal group response";
CM_ SG_ 1432 CEMdevelpsignalgrouprespFunctiondevpsignalgroup3 "develop signal group response";
CM_ SG_ 1432 CEMdevelpsignalgrouprespFunctiondevpsignalgroup4 "develop signal group response";
CM_ SG_ 1432 CEMdevelpsignalgrouprespFunctiondevpsignalgroup5 "develop signal group response";
CM_ SG_ 1432 CEMdevelpsignalgrouprespFunctiondevpsignalgroup6 "develop signal group response";
CM_ SG_ 1432 CEMdevelpsignalgrouprespFunctiondevpsignalgroup7 "develop signal group response";
CM_ SG_ 1432 CEMdevelpsignalgrouprespFunctiondevpsignalgroup8 "develop signal group response";
CM_ SG_ 1431 CEMdevelpsignalgroupcheckFunctiondevpsignalgroup1 "develop signal group check";
CM_ SG_ 1431 CEMdevelpsignalgroupcheckFunctiondevpsignalgroup2 "develop signal group check";
CM_ SG_ 1431 CEMdevelpsignalgroupcheckFunctiondevpsignalgroup3 "develop signal group check";
CM_ SG_ 1431 CEMdevelpsignalgroupcheckFunctiondevpsignalgroup4 "develop signal group check";
CM_ SG_ 1431 CEMdevelpsignalgroupcheckFunctiondevpsignalgroup5 "develop signal group check";
CM_ SG_ 1431 CEMdevelpsignalgroupcheckFunctiondevpsignalgroup6 "develop signal group check";
CM_ SG_ 1431 CEMdevelpsignalgroupcheckFunctiondevpsignalgroup7 "develop signal group check";
CM_ SG_ 1431 CEMdevelpsignalgroupcheckFunctiondevpsignalgroup8 "develop signal group check";
CM_ SG_ 28 CarpetLiActvReq "0: no command ,default value
1:active ,request active to carpet light
2:deactive ,request deactive to carpet light";
CM_ SG_ 28 ExtrLiShowActvnReq "Request signal for activating Light show, if the value has been set to on. ";
CM_ SG_ 28 ExtrLiShowFileTxReq "Request signal for transferring sequence table. If the value has been set to on, the parameter of lamp elements can be downloaded from IHU to HCM/RCM. ";
CM_ SG_ 288 DwnLoadDynLitPrmForLedStopLampRi2ContTiPrm "Light Show Continue Time Parameter 1";
CM_ SG_ 288 DwnLoadDynLitPrmForLedStopLampRi2LowBriPrm "Light Show Lower Brightness Parameter 1";
CM_ SG_ 288 DwnLoadDynLitPrmForLedStopLampRi2ModePrm "Light Show Mode Parameter 1";
CM_ SG_ 288 DwnLoadDynLitPrmForLedStopLampRi2OffsTiPrm "Light Show Offset Time Parameter 1";
CM_ SG_ 288 DwnLoadDynLitPrmForLedStopLampRi2Tistamp "Light Show time stamp";
CM_ SG_ 288 DwnLoadDynLitPrmForLedStopLampRi2UpprBriPrm "Light Show Upper Brightness Parameter 1";
CM_ SG_ 289 DwnLoadDynLitPrmLedReFogLampRi2ContTiPrm "Light Show Continue Time Parameter 1";
CM_ SG_ 289 DwnLoadDynLitPrmLedReFogLampRi2LowBriPrm "Light Show Lower Brightness Parameter 1";
CM_ SG_ 289 DwnLoadDynLitPrmLedReFogLampRi2ModePrm "Light Show Mode Parameter 1";
CM_ SG_ 289 DwnLoadDynLitPrmLedReFogLampRi2OffsTiPrm "Light Show Offset Time Parameter 1";
CM_ SG_ 289 DwnLoadDynLitPrmLedReFogLampRi2Tistamp "Light Show time stamp";
CM_ SG_ 289 DwnLoadDynLitPrmLedReFogLampRi2UpprBriPrm "Light Show Upper Brightness Parameter 1";
CM_ SG_ 290 DwnLoadDynLitPrmLedRePosnLampRi2ContTiPrm "Light Show Continue Time Parameter 1";
CM_ SG_ 290 DwnLoadDynLitPrmLedRePosnLampRi2LowBriPrm "Light Show Lower Brightness Parameter 1";
CM_ SG_ 290 DwnLoadDynLitPrmLedRePosnLampRi2ModePrm "Light Show Mode Parameter 1";
CM_ SG_ 290 DwnLoadDynLitPrmLedRePosnLampRi2OffsTiPrm "Light Show Offset Time Parameter 1";
CM_ SG_ 290 DwnLoadDynLitPrmLedRePosnLampRi2Tistamp "Light Show time stamp";
CM_ SG_ 290 DwnLoadDynLitPrmLedRePosnLampRi2UpprBriPrm "Light Show Upper Brightness Parameter 1";
CM_ SG_ 291 DwnLoadDynLitPrmLedReTurnIndcrRi2ContTiPrm "Light Show Continue Time Parameter 1";
CM_ SG_ 291 DwnLoadDynLitPrmLedReTurnIndcrRi2LowBriPrm "Light Show Lower Brightness Parameter 1";
CM_ SG_ 291 DwnLoadDynLitPrmLedReTurnIndcrRi2ModePrm "Light Show Mode Parameter 1";
CM_ SG_ 291 DwnLoadDynLitPrmLedReTurnIndcrRi2OffsTiPrm "Light Show Offset Time Parameter 1";
CM_ SG_ 291 DwnLoadDynLitPrmLedReTurnIndcrRi2Tistamp "Light Show time stamp";
CM_ SG_ 291 DwnLoadDynLitPrmLedReTurnIndcrRi2UpprBriPrm "Light Show Upper Brightness Parameter 1";
CM_ SG_ 292 DwnLoadDynLitPrmForLedMkrLampLe1ContTiPrm "Light Show Continue Time Parameter 1";
CM_ SG_ 292 DwnLoadDynLitPrmForLedMkrLampLe1LowBriPrm "Light Show Lower Brightness Parameter 1";
CM_ SG_ 292 DwnLoadDynLitPrmForLedMkrLampLe1ModePrm "Light Show Mode Parameter 1";
CM_ SG_ 292 DwnLoadDynLitPrmForLedMkrLampLe1OffsTiPrm "Light Show Offset Time Parameter 1";
CM_ SG_ 292 DwnLoadDynLitPrmForLedMkrLampLe1Tistamp "Light Show time stamp";
CM_ SG_ 292 DwnLoadDynLitPrmForLedMkrLampLe1UpprBriPrm "Light Show Upper Brightness Parameter 1";
CM_ SG_ 293 DwnLoadDynLtgPrmForLedLoBeamRiContTiPrm "Light Show Continue Time Parameter 1";
CM_ SG_ 293 DwnLoadDynLtgPrmForLedLoBeamRiLowBriPrm "Light Show Lower Brightness Parameter 1";
CM_ SG_ 293 DwnLoadDynLtgPrmForLedLoBeamRiModePrm "Light Show Mode Parameter 1";
CM_ SG_ 293 DwnLoadDynLtgPrmForLedLoBeamRiOffsTiPrm "Light Show Offset Time Parameter 1";
CM_ SG_ 293 DwnLoadDynLtgPrmForLedLoBeamRiTistamp "Light Show time stamp";
CM_ SG_ 293 DwnLoadDynLtgPrmForLedLoBeamRiUpprBriPrm "Light Show Upper Brightness Parameter 1";
CM_ SG_ 294 DwnLoadDynLitPrmForLedMkrLampLe2ContTiPrm "Light Show Continue Time Parameter 1";
CM_ SG_ 294 DwnLoadDynLitPrmForLedMkrLampLe2LowBriPrm "Light Show Lower Brightness Parameter 1";
CM_ SG_ 294 DwnLoadDynLitPrmForLedMkrLampLe2ModePrm "Light Show Mode Parameter 1";
CM_ SG_ 294 DwnLoadDynLitPrmForLedMkrLampLe2OffsTiPrm "Light Show Offset Time Parameter 1";
CM_ SG_ 294 DwnLoadDynLitPrmForLedMkrLampLe2Tistamp "Light Show time stamp";
CM_ SG_ 294 DwnLoadDynLitPrmForLedMkrLampLe2UpprBriPrm "Light Show Upper Brightness Parameter 1";
CM_ SG_ 295 DwnLoadDynLitPrmForLedMkrLampRi1ContTiPrm "Light Show Continue Time Parameter 1";
CM_ SG_ 295 DwnLoadDynLitPrmForLedMkrLampRi1LowBriPrm "Light Show Lower Brightness Parameter 1";
CM_ SG_ 295 DwnLoadDynLitPrmForLedMkrLampRi1ModePrm "Light Show Mode Parameter 1";
CM_ SG_ 295 DwnLoadDynLitPrmForLedMkrLampRi1OffsTiPrm "Light Show Offset Time Parameter 1";
CM_ SG_ 295 DwnLoadDynLitPrmForLedMkrLampRi1Tistamp "Light Show time stamp";
CM_ SG_ 295 DwnLoadDynLitPrmForLedMkrLampRi1UpprBriPrm "Light Show Upper Brightness Parameter 1";
CM_ SG_ 296 DwnLoadDynLitPrmForLedStopLampLe1ContTiPrm "Light Show Continue Time Parameter 1";
CM_ SG_ 296 DwnLoadDynLitPrmForLedStopLampLe1LowBriPrm "Light Show Lower Brightness Parameter 1";
CM_ SG_ 296 DwnLoadDynLitPrmForLedStopLampLe1ModePrm "Light Show Mode Parameter 1";
CM_ SG_ 296 DwnLoadDynLitPrmForLedStopLampLe1OffsTiPrm "Light Show Offset Time Parameter 1";
CM_ SG_ 296 DwnLoadDynLitPrmForLedStopLampLe1Tistamp "Light Show time stamp";
CM_ SG_ 296 DwnLoadDynLitPrmForLedStopLampLe1UpprBriPrm "Light Show Upper Brightness Parameter 1";
CM_ SG_ 834 DwnLoadDynLtgPrmForFrntRIGrp10ContinueTime "Light Show Continue Time Parameter 2";
CM_ SG_ 834 DwnLoadDynLtgPrmForFrntRIGrp10HighBrightness "Light Show Upper Brightness Parameter 2";
CM_ SG_ 834 DwnLoadDynLtgPrmForFrntRIGrp10LowBrightness "Light Show Lower Brightness Parameter 2";
CM_ SG_ 834 DwnLoadDynLtgPrmForFrntRIGrp10Mode1 "Light Show Mode Parameter 2";
CM_ SG_ 834 DwnLoadDynLtgPrmForFrntRIGrp10OffsetTime "Light Show Offset Time Parameter 2";
CM_ SG_ 834 DwnLoadDynLtgPrmForFrntRIGrp10Timestamp "Light Show time stamp 2";
CM_ SG_ 835 DwnLoadDynLtgPrmForFrntRIGrp11ContinueTime "Light Show Continue Time Parameter 2";
CM_ SG_ 835 DwnLoadDynLtgPrmForFrntRIGrp11HighBrightness "Light Show Upper Brightness Parameter 2";
CM_ SG_ 835 DwnLoadDynLtgPrmForFrntRIGrp11LowBrightness "Light Show Lower Brightness Parameter 2";
CM_ SG_ 835 DwnLoadDynLtgPrmForFrntRIGrp11Mode1 "Light Show Mode Parameter 2";
CM_ SG_ 835 DwnLoadDynLtgPrmForFrntRIGrp11OffsetTime "Light Show Offset Time Parameter 2";
CM_ SG_ 835 DwnLoadDynLtgPrmForFrntRIGrp11Timestamp "Light Show time stamp 2";
CM_ SG_ 836 DwnLoadDynLtgPrmForFrntRIGrp12ContinueTime "Light Show Continue Time Parameter 2";
CM_ SG_ 836 DwnLoadDynLtgPrmForFrntRIGrp12HighBrightness "Light Show Upper Brightness Parameter 2";
CM_ SG_ 836 DwnLoadDynLtgPrmForFrntRIGrp12LowBrightness "Light Show Lower Brightness Parameter 2";
CM_ SG_ 836 DwnLoadDynLtgPrmForFrntRIGrp12Mode1 "Light Show Mode Parameter 2";
CM_ SG_ 836 DwnLoadDynLtgPrmForFrntRIGrp12OffsetTime "Light Show Offset Time Parameter 2";
CM_ SG_ 836 DwnLoadDynLtgPrmForFrntRIGrp12Timestamp "Light Show time stamp 2";
CM_ SG_ 837 DwnLoadDynLtgPrmForFrntRIGrp13ContinueTime "Light Show Continue Time Parameter 2";
CM_ SG_ 837 DwnLoadDynLtgPrmForFrntRIGrp13HighBrightness "Light Show Upper Brightness Parameter 2";
CM_ SG_ 837 DwnLoadDynLtgPrmForFrntRIGrp13LowBrightness "Light Show Lower Brightness Parameter 2";
CM_ SG_ 837 DwnLoadDynLtgPrmForFrntRIGrp13Mode1 "Light Show Mode Parameter 2";
CM_ SG_ 837 DwnLoadDynLtgPrmForFrntRIGrp13OffsetTime "Light Show Offset Time Parameter 2";
CM_ SG_ 837 DwnLoadDynLtgPrmForFrntRIGrp13Timestamp "Light Show time stamp 2";
CM_ SG_ 838 DwnLoadDynLtgPrmForFrntRIGrp14ContinueTime "Light Show Continue Time Parameter 2";
CM_ SG_ 838 DwnLoadDynLtgPrmForFrntRIGrp14HighBrightness "Light Show Upper Brightness Parameter 2";
CM_ SG_ 838 DwnLoadDynLtgPrmForFrntRIGrp14LowBrightness "Light Show Lower Brightness Parameter 2";
CM_ SG_ 838 DwnLoadDynLtgPrmForFrntRIGrp14Mode1 "Light Show Mode Parameter 2";
CM_ SG_ 838 DwnLoadDynLtgPrmForFrntRIGrp14OffsetTime "Light Show Offset Time Parameter 2";
CM_ SG_ 838 DwnLoadDynLtgPrmForFrntRIGrp14Timestamp "Light Show time stamp 2";
CM_ SG_ 839 DwnLoadDynLtgPrmForFrntRIGrp15ContinueTime "Light Show Continue Time Parameter 2";
CM_ SG_ 839 DwnLoadDynLtgPrmForFrntRIGrp15HighBrightness "Light Show Upper Brightness Parameter 2";
CM_ SG_ 839 DwnLoadDynLtgPrmForFrntRIGrp15LowBrightness "Light Show Lower Brightness Parameter 2";
CM_ SG_ 839 DwnLoadDynLtgPrmForFrntRIGrp15Mode1 "Light Show Mode Parameter 2";
CM_ SG_ 839 DwnLoadDynLtgPrmForFrntRIGrp15OffsetTime "Light Show Offset Time Parameter 2";
CM_ SG_ 839 DwnLoadDynLtgPrmForFrntRIGrp15Timestamp "Light Show time stamp 2";
CM_ SG_ 840 DwnLoadDynLtgPrmForFrntRIGrp16ContinueTime "Light Show Continue Time Parameter 2";
CM_ SG_ 840 DwnLoadDynLtgPrmForFrntRIGrp16HighBrightness "Light Show Upper Brightness Parameter 2";
CM_ SG_ 840 DwnLoadDynLtgPrmForFrntRIGrp16LowBrightness "Light Show Lower Brightness Parameter 2";
CM_ SG_ 840 DwnLoadDynLtgPrmForFrntRIGrp16Mode1 "Light Show Mode Parameter 2";
CM_ SG_ 840 DwnLoadDynLtgPrmForFrntRIGrp16OffsetTime "Light Show Offset Time Parameter 2";
CM_ SG_ 840 DwnLoadDynLtgPrmForFrntRIGrp16Timestamp "Light Show time stamp 2";
CM_ SG_ 841 DwnLoadDynLtgPrmForFrntRIGrp17ContinueTime "Light Show Continue Time Parameter 2";
CM_ SG_ 841 DwnLoadDynLtgPrmForFrntRIGrp17HighBrightness "Light Show Upper Brightness Parameter 2";
CM_ SG_ 841 DwnLoadDynLtgPrmForFrntRIGrp17LowBrightness "Light Show Lower Brightness Parameter 2";
CM_ SG_ 841 DwnLoadDynLtgPrmForFrntRIGrp17Mode1 "Light Show Mode Parameter 2";
CM_ SG_ 841 DwnLoadDynLtgPrmForFrntRIGrp17OffsetTime "Light Show Offset Time Parameter 2";
CM_ SG_ 841 DwnLoadDynLtgPrmForFrntRIGrp17Timestamp "Light Show time stamp 2";
CM_ SG_ 842 DwnLoadDynLtgPrmForFrntRIGrp18ContinueTime "Light Show Continue Time Parameter 2";
CM_ SG_ 842 DwnLoadDynLtgPrmForFrntRIGrp18HighBrightness "Light Show Upper Brightness Parameter 2";
CM_ SG_ 842 DwnLoadDynLtgPrmForFrntRIGrp18LowBrightness "Light Show Lower Brightness Parameter 2";
CM_ SG_ 842 DwnLoadDynLtgPrmForFrntRIGrp18Mode1 "Light Show Mode Parameter 2";
CM_ SG_ 842 DwnLoadDynLtgPrmForFrntRIGrp18OffsetTime "Light Show Offset Time Parameter 2";
CM_ SG_ 842 DwnLoadDynLtgPrmForFrntRIGrp18Timestamp "Light Show time stamp 2";
CM_ SG_ 843 DwnLoadDynLtgPrmForFrntRIGrp19ContinueTime "Light Show Continue Time Parameter 2";
CM_ SG_ 843 DwnLoadDynLtgPrmForFrntRIGrp19HighBrightness "Light Show Upper Brightness Parameter 2";
CM_ SG_ 843 DwnLoadDynLtgPrmForFrntRIGrp19LowBrightness "Light Show Lower Brightness Parameter 2";
CM_ SG_ 843 DwnLoadDynLtgPrmForFrntRIGrp19Mode1 "Light Show Mode Parameter 2";
CM_ SG_ 843 DwnLoadDynLtgPrmForFrntRIGrp19OffsetTime "Light Show Offset Time Parameter 2";
CM_ SG_ 843 DwnLoadDynLtgPrmForFrntRIGrp19Timestamp "Light Show time stamp 2";
CM_ SG_ 297 DwnLoadDynLitPrmForLedStopLampLe2ContTiPrm "Light Show Continue Time Parameter 1";
CM_ SG_ 297 DwnLoadDynLitPrmForLedStopLampLe2LowBriPrm "Light Show Lower Brightness Parameter 1";
CM_ SG_ 297 DwnLoadDynLitPrmForLedStopLampLe2ModePrm "Light Show Mode Parameter 1";
CM_ SG_ 297 DwnLoadDynLitPrmForLedStopLampLe2OffsTiPrm "Light Show Offset Time Parameter 1";
CM_ SG_ 297 DwnLoadDynLitPrmForLedStopLampLe2Tistamp "Light Show time stamp";
CM_ SG_ 297 DwnLoadDynLitPrmForLedStopLampLe2UpprBriPrm "Light Show Upper Brightness Parameter 1";
CM_ SG_ 844 DwnLoadDynLtgPrmForFrntRIGrp20ContinueTime "Light Show Continue Time Parameter 2";
CM_ SG_ 844 DwnLoadDynLtgPrmForFrntRIGrp20HighBrightness "Light Show Upper Brightness Parameter 2";
CM_ SG_ 844 DwnLoadDynLtgPrmForFrntRIGrp20LowBrightness "Light Show Lower Brightness Parameter 2";
CM_ SG_ 844 DwnLoadDynLtgPrmForFrntRIGrp20Mode1 "Light Show Mode Parameter 2";
CM_ SG_ 844 DwnLoadDynLtgPrmForFrntRIGrp20OffsetTime "Light Show Offset Time Parameter 2";
CM_ SG_ 844 DwnLoadDynLtgPrmForFrntRIGrp20Timestamp "Light Show time stamp 2";
CM_ SG_ 845 DwnLoadDynLtgPrmForFrntRIGrp21ContinueTime "Light Show Continue Time Parameter 2";
CM_ SG_ 845 DwnLoadDynLtgPrmForFrntRIGrp21HighBrightness "Light Show Upper Brightness Parameter 2";
CM_ SG_ 845 DwnLoadDynLtgPrmForFrntRIGrp21LowBrightness "Light Show Lower Brightness Parameter 2";
CM_ SG_ 845 DwnLoadDynLtgPrmForFrntRIGrp21Mode1 "Light Show Mode Parameter 2";
CM_ SG_ 845 DwnLoadDynLtgPrmForFrntRIGrp21OffsetTime "Light Show Offset Time Parameter 2";
CM_ SG_ 845 DwnLoadDynLtgPrmForFrntRIGrp21Timestamp "Light Show time stamp 2";
CM_ SG_ 846 DwnLoadDynLtgPrmForFrntRIGrp22ContinueTime "Light Show Continue Time Parameter 2";
CM_ SG_ 846 DwnLoadDynLtgPrmForFrntRIGrp22HighBrightness "Light Show Upper Brightness Parameter 2";
CM_ SG_ 846 DwnLoadDynLtgPrmForFrntRIGrp22LowBrightness "Light Show Lower Brightness Parameter 2";
CM_ SG_ 846 DwnLoadDynLtgPrmForFrntRIGrp22Mode1 "Light Show Mode Parameter 2";
CM_ SG_ 846 DwnLoadDynLtgPrmForFrntRIGrp22OffsetTime "Light Show Offset Time Parameter 2";
CM_ SG_ 846 DwnLoadDynLtgPrmForFrntRIGrp22Timestamp "Light Show time stamp 2";
CM_ SG_ 847 DwnLoadDynLtgPrmForFrntRIGrp23ContinueTime "Light Show Continue Time Parameter 2";
CM_ SG_ 847 DwnLoadDynLtgPrmForFrntRIGrp23HighBrightness "Light Show Upper Brightness Parameter 2";
CM_ SG_ 847 DwnLoadDynLtgPrmForFrntRIGrp23LowBrightness "Light Show Lower Brightness Parameter 2";
CM_ SG_ 847 DwnLoadDynLtgPrmForFrntRIGrp23Mode1 "Light Show Mode Parameter 2";
CM_ SG_ 847 DwnLoadDynLtgPrmForFrntRIGrp23OffsetTime "Light Show Offset Time Parameter 2";
CM_ SG_ 847 DwnLoadDynLtgPrmForFrntRIGrp23Timestamp "Light Show time stamp 2";
CM_ SG_ 848 DwnLoadDynLtgPrmForFrntRIGrp24ContinueTime "Light Show Continue Time Parameter 2";
CM_ SG_ 848 DwnLoadDynLtgPrmForFrntRIGrp24HighBrightness "Light Show Upper Brightness Parameter 2";
CM_ SG_ 848 DwnLoadDynLtgPrmForFrntRIGrp24LowBrightness "Light Show Lower Brightness Parameter 2";
CM_ SG_ 848 DwnLoadDynLtgPrmForFrntRIGrp24Mode1 "Light Show Mode Parameter 2";
CM_ SG_ 848 DwnLoadDynLtgPrmForFrntRIGrp24OffsetTime "Light Show Offset Time Parameter 2";
CM_ SG_ 848 DwnLoadDynLtgPrmForFrntRIGrp24Timestamp "Light Show time stamp 2";
CM_ SG_ 784 ActvnOfADB "activation of ADB";
CM_ SG_ 784 ActvnOfLiForComity "signal send to actuator to activate dynamic light for comity function";
CM_ SG_ 784 ActvnOfLiForSpkr "signal send to actuator to activate dynamic light for showing speaker";
CM_ SG_ 784 ActvnOfLiForWait "signal send to actuator to activate dynamic light for wait function";
CM_ SG_ 784 CabPressPodCalc "Cabine pressure calculation for closing power operated doors. 0 Undefined, 1 VeryLow, 2 Low, 3 Medium, 4High, 5 VeryHigh";
CM_ SG_ 784 DoorDrvrLatPawlSt "Used to indicate if the driver door actuator must be triggered based in the pawl switch status AND other conditions from Driver door latch. [Close] Door is fully closed, the Pawl switch has changed value to PSD and timer to reach ajar is out without reaching ajar. [Open] Pawl Switch has not changed status to [PSD] OR latch successfully reach Ajar position within time. [Undefined] Not enough information about Pawl Switch status is found";
CM_ SG_ 784 DoorDrvrLatPosn "Driver door Cinch position. x01 equal fully open, x02 equal secondary position, x03 equal fully closed.";
CM_ SG_ 784 DoorLeReLatPawlSt "Used to indicate if the Left Rear door actuator must be triggered based in the pawl switch status AND other conditions from Left Rear door latch. [Close] Door is fully closed, the Pawl switch has changed value to PSD and timer to reach ajar is out without reaching ajar. [Open] Pawl Switch has not changed status to [PSD] OR latch successfully reach Ajar position within time. [Undefined] Not enough information about Pawl Switch status is found";
CM_ SG_ 784 DoorLeReLatPosn "Left rear door Cinch position. x01 equal fully open, x02 equal secondary position, x03 equal fully closed.";
CM_ SG_ 784 DoorPassLatPawlSt "Used to indicate if the passenger door actuator must be triggered based in the pawl switch status AND other conditions from passenger door latch. [Close] Door is fully closed, the Pawl switch has changed value to PSD and timer to reach ajar is out without reaching ajar. [Open] Pawl Switch has not changed status to [PSD] OR latch successfully reach Ajar position within time. [Undefined] Not enough information about Pawl Switch status is found";
CM_ SG_ 784 DoorPassLatPosn "Passenger door Cinch position. x01 equal fully open, x02 equal secondary position, x03 equal fully closed.";
CM_ SG_ 784 DoorRiReLatPawlSt "Used to indicate if the Right Rear door actuator must be triggered based in the pawl switch status AND other conditions from Right Rear door latch. [Close] Door is fully closed, the Pawl switch has changed value to PSD and timer to reach ajar is out without reaching ajar. [Open] Pawl Switch has not changed status to [PSD] OR latch successfully reach Ajar position within time. [Undefined] Not enough information about Pawl Switch status is found";
CM_ SG_ 784 DoorRiReLatPosn "Right rear door Cinch position. x01 equal fully open, x02 equal secondary position, x03 equal fully closed.";
CM_ SG_ 784 LockgCenStsLockSt "Signal LockgCenSts provides central locking status to other subsystems.
Signal is a record with three items
- LockSt (Lock State)
- TrigSrc (Trig Source)
- UpdEve (Will be set to TRUE during one second at each new central locking or unlocking event)";
CM_ SG_ 784 LockgCenStsTrigSrc "Signal LockgCenSts provides central locking status to other subsystems.
Signal is a record with three items
- LockSt (Lock State)
- TrigSrc (Trig Source)
- UpdEve (Will be set to TRUE during one second at each new central locking or unlocking event)";
CM_ SG_ 784 LockgCenStsUpdEve "Signal LockgCenSts provides central locking status to other subsystems.
Signal is a record with three items
- LockSt (Lock State)
- TrigSrc (Trig Source)
- UpdEve (Will be set to TRUE during one second at each new central locking or unlocking event)";
CM_ SG_ 784 VehMtnStChks "Vehicle motion state information based on wheel speed sensors. Provides information about vehicle stand still and vehicle rolling direction. Checksum for vehicle motion state";
CM_ SG_ 784 VehMtnStCntr "Vehicle motion state information based on wheel speed sensors. Provides information about vehicle stand still and vehicle rolling direction. Counter for vehicle motion state";
CM_ SG_ 784 VehMtnStVehMtnSt "Vehicle motion state information based on wheel speed sensors. Provides information about vehicle stand still and vehicle rolling direction. Vehicle motion state";
CM_ SG_ 1152 TiAndDateIndcnDataValid "Current time (Hr, Min and Sec) and date (Year, Months and days) data for indication. See requirement for more information about the signals. Signal qualifier, No means values should be ignored.";
CM_ SG_ 1152 TiAndDateIndcnDay "Current time (Hr, Min and Sec) and date (Year, Months and days) data for indication. See requirement for more information about the signals. Day";
CM_ SG_ 1152 TiAndDateIndcnHr1 "Current time (Hr, Min and Sec) and date (Year, Months and days) data for indication. See requirement for more information about the signals. Hour";
CM_ SG_ 1152 TiAndDateIndcnMins1 "Current time (Hr, Min and Sec) and date (Year, Months and days) data for indication. See requirement for more information about the signals. Minutes";
CM_ SG_ 1152 TiAndDateIndcnMth1 "Current time (Hr, Min and Sec) and date (Year, Months and days) data for indication. See requirement for more information about the signals. Month, 1-12";
CM_ SG_ 1152 TiAndDateIndcnSec1 "Current time (Hr, Min and Sec) and date (Year, Months and days) data for indication. See requirement for more information about the signals. Seconds";
CM_ SG_ 1152 TiAndDateIndcnYr1 "Current time (Hr, Min and Sec) and date (Year, Months and days) data for indication. See requirement for more information about the signals. Year, 0-99";
CM_ SG_ 361 CarpetLiDownloadFinish "Carpet lamp download complete";
CM_ SG_ 361 CarpetLiDownloadReq "Carpet lamp theme download request";
CM_ SG_ 361 CarpetLiDowSwt "Carpet lamp door opening warning switch";
CM_ SG_ 361 DoorDrvrAutoManReq "Driver side door auto or manul selection";
CM_ SG_ 361 DoorOpenerDrvrReqChks "Checksum for E2E";
CM_ SG_ 361 DoorOpenerDrvrReqCntr "Counter for E2E";
CM_ SG_ 361 DoorOpenerDrvrReqDoorOpenerReq "DoorOpenerReq
DoorOpenerIdle - No request
DoorOpenerOpen - Request to Open
DoorOpenerCls - Request to Close
DoorOpenerStop - Request to stop any ongoing power side door movement";
CM_ SG_ 361 DoorOpenerDrvrReqTrigSrc "TrigSrc
NoTrigSrc - No trig source
KeyRem - Remote Key
HMI - Center stack display
Telm - Telematics
OutdSwt - Outer door switch
InsdSwt - Inside door switch";
CM_ SG_ 361 DoorOpenerLeReReqChks "Checksum for E2E";
CM_ SG_ 361 DoorOpenerLeReReqCntr "Counter for E2E";
CM_ SG_ 361 DoorOpenerLeReReqDoorOpenerReq "DoorOpenerReq
DoorOpenerIdle - No request
DoorOpenerOpen - Request to Open
DoorOpenerCls - Request to Close
DoorOpenerStop - Request to stop any ongoing power side door movement";
CM_ SG_ 361 DoorOpenerLeReReqTrigSrc "TrigSrc
NoTrigSrc - No trig source
KeyRem - Remote Key
HMI - Center stack display
Telm - Telematics
OutdSwt - Outer door switch
InsdSwt - Inside door switch";
CM_ SG_ 361 OpenDrvrSwt "driver door open switch status";
CM_ SG_ 361 OpenLeReSwt "Left rear door open switch status";
CM_ SG_ 361 OpenPassSwt "passenger door open switch status";
CM_ SG_ 361 OpenRiReSwt " Rigth rear door open switch status";
CM_ SG_ 361 PawlDrvrSwt "driver door pawl switch status";
CM_ SG_ 361 PawlLeReSwt " Left rear door pawl switch status";
CM_ SG_ 361 PawlPassSwt "passenger door pawl switch status";
CM_ SG_ 361 PawlRiReSwt " Rigth rear door pawl switch status";

// Attribute definitions
BA_DEF_  "Baudrate" INT 1000 1000000; // [bps]
BA_DEF_ BO_ "GenMsgSendType" ENUM "cyclic", "spontaneous", "not-used", "not-used", "not-used", "cyclicAndSpontaneous", "not-used", "cyclicIfActive", "NoMsgSendType"; // [us]
BA_DEF_ BO_ "GenMsgCycleTime" INT 0 65536; // [ms]
BA_DEF_ BO_ "GenMsgStartDelayTime" INT 0 65536; // [ms]
BA_DEF_ BO_ "GenMsgDelayTime" INT 0 65536; // [ms]
BA_DEF_ SG_ "GenSigSendType" ENUM "Cyclic","OnWrite","OnWriteWithRepetition","OnChange","OnChangeWithRepetition","IfActive","IfActiveWithRepetition","NoSigSendType";
BA_DEF_ SG_ "GenSigStartValue" HEX 0 80000000;
BA_DEF_ BU_ "NmAsrNodeIdentifier" INT 0 255;
BA_DEF_ BU_ "NmAsrNode" ENUM "No","Yes";
BA_DEF_  "DBName" STRING;
BA_DEF_  "BusType" STRING;
BA_DEF_  "ProtocolType" STRING;
BA_DEF_ BO_ "GenMsgILSupport" ENUM "No","Yes";
BA_DEF_ BO_ "NmAsrMessage" ENUM "No","Yes";
BA_DEF_  "NmAsrBaseAddress" HEX 0 536870911;
BA_DEF_  "NmAsrMessageCount" INT 0 255;
BA_DEF_ BU_ "NodeLayerModules" STRING;
BA_DEF_ BU_ "ILused" ENUM "No","Yes";
BA_DEF_ SG_ "GenSigFuncType" ENUM "NoFunction","n/a","n/a","n/a","n/a","n/a","n/a","n/a","n/a","n/a","n/a","n/a","n/a","n/a","n/a","CHK","CNTR","n/a","n/a","n/a","CNTR_AR_01","CRC_AR_01_BOTH","CRC_AR_01_ALT","CRC_AR_01_LOW","CRC_AR_01_NIBBLE","CNTR_AR_04","CRC_AR_04A","CNTR_AR_05","CRC_AR_05";
BA_DEF_ SG_ "GenSigDataID" STRING;
BA_DEF_ SG_ "SigGroup" STRING;

BA_DEF_DEF_ "GenSigStartValue" 0;
BA_DEF_DEF_ "GenSigSendType" "NoSigSendType";
BA_DEF_DEF_ "NmAsrNodeIdentifier" 0;
BA_DEF_DEF_ "NmAsrNode" "No";
BA_DEF_DEF_ "DBName" "";
BA_DEF_DEF_ "BusType" "";
BA_DEF_DEF_ "ProtocolType" "";
BA_DEF_DEF_ "GenMsgCycleTime" 0;
BA_DEF_DEF_ "GenMsgDelayTime" 0;
BA_DEF_DEF_ "GenMsgStartDelayTime" 0;
BA_DEF_DEF_ "GenMsgSendType" "NoMsgSendType";
BA_DEF_DEF_ "GenMsgILSupport" "Yes";
BA_DEF_DEF_ "NmAsrMessage" "No";
BA_DEF_DEF_ "NmAsrBaseAddress" 1280;
BA_DEF_DEF_ "NmAsrMessageCount" 64;
BA_DEF_DEF_ "NodeLayerModules" "CANoeILNLSPA.dll";
BA_DEF_DEF_ "ILused" "Yes";
BA_DEF_DEF_ "GenSigFuncType" "NoFunction";
BA_DEF_DEF_ "GenSigDataID" "";
BA_DEF_DEF_ "SigGroup" "";

// Network
BA_ "DBName" "BodyExposedCAN";
BA_ "BusType" "CAN";
BA_ "ProtocolType" "CAN";
BA_ "Baudrate" 500000;
// ECU: CEM
BA_ "NmAsrNodeIdentifier" BU_ CEM 42;
BA_ "NmAsrNode" BU_ CEM 1;
BA_ "NodeLayerModules" BU_ CEM "CANoeILNLSPA.dll,AsrNM33.dll";
// ECU: ETC
BA_ "ILused" BU_ ETC 0;
// ECU: HCML
BA_ "NmAsrNodeIdentifier" BU_ HCML 49;
BA_ "NmAsrNode" BU_ HCML 1;
BA_ "NodeLayerModules" BU_ HCML "CANoeILNLSPA.dll,AsrNM33.dll";
// ECU: HCMR
BA_ "NmAsrNodeIdentifier" BU_ HCMR 50;
BA_ "NmAsrNode" BU_ HCMR 1;
BA_ "NodeLayerModules" BU_ HCMR "CANoeILNLSPA.dll,AsrNM33.dll";
// ECU: RCML
BA_ "NmAsrNodeIdentifier" BU_ RCML 51;
BA_ "NmAsrNode" BU_ RCML 1;
BA_ "NodeLayerModules" BU_ RCML "CANoeILNLSPA.dll,AsrNM33.dll";
// ECU: RCMM
BA_ "NmAsrNodeIdentifier" BU_ RCMM 53;
BA_ "NmAsrNode" BU_ RCMM 1;
BA_ "NodeLayerModules" BU_ RCMM "CANoeILNLSPA.dll,AsrNM33.dll";
// ECU: RCMR
BA_ "NmAsrNodeIdentifier" BU_ RCMR 52;
BA_ "NmAsrNode" BU_ RCMR 1;
BA_ "NodeLayerModules" BU_ RCMR "CANoeILNLSPA.dll,AsrNM33.dll";
// Frame: CemBodyCanExposedNMFr
BA_ "GenMsgSendType" BO_ 1322 1;
BA_ "GenMsgDelayTime" BO_ 1322 20.000;
BA_ "GenMsgILSupport" BO_ 1322 0;
BA_ "NmAsrMessage" BO_ 1322 1;
// Frame: CemBodyExpoCommonFr01
BA_ "GenMsgSendType" BO_ 82 0;
BA_ "GenMsgCycleTime" BO_ 82 10.000;
BA_ "GenSigSendType" SG_ 82 AutWinWipgCmd 0;
BA_ "GenSigSendType" SG_ 82 LiOprnMod 0;
BA_ "GenSigSendType" SG_ 82 SteerWhlSnsrAg 0;
BA_ "GenSigSendType" SG_ 82 SteerWhlSnsrAgSpd 0;
BA_ "GenSigSendType" SG_ 82 SteerWhlSnsrChks 0;
BA_ "GenSigFuncType" SG_ 82 SteerWhlSnsrChks 15;
BA_ "GenSigDataID" SG_ 82 SteerWhlSnsrChks "0x33";
BA_ "GenSigSendType" SG_ 82 SteerWhlSnsrCntr 0;
BA_ "GenSigFuncType" SG_ 82 SteerWhlSnsrCntr 16;
BA_ "GenSigStartValue" SG_ 82 SteerWhlSnsrQf 1;
BA_ "GenSigSendType" SG_ 82 SteerWhlSnsrQf 0;
// Frame: CemBodyExpoCommonFr02
BA_ "GenMsgSendType" BO_ 768 0;
BA_ "GenMsgCycleTime" BO_ 768 45.000;
BA_ "GenSigSendType" SG_ 768 ActvnOfRvsg 0;
BA_ "GenSigSendType" SG_ 768 BrkPedlrRatPerc 0;
BA_ "GenSigSendType" SG_ 768 BrkPedlrRatQf 0;
BA_ "GenSigSendType" SG_ 768 YawRateReqdByDrvr 0;
// Frame: CEMBodyExpoCommonFr04
BA_ "GenMsgSendType" BO_ 80 0;
BA_ "GenMsgCycleTime" BO_ 80 40.000;
BA_ "GenSigSendType" SG_ 80 DoorPassSts 0;
BA_ "GenSigSendType" SG_ 80 DoorRiReSts 0;
BA_ "GenSigSendType" SG_ 80 VehSpdLgtA 0;
BA_ "GenSigSendType" SG_ 80 VehSpdLgtChks 0;
BA_ "GenSigFuncType" SG_ 80 VehSpdLgtChks 15;
BA_ "GenSigDataID" SG_ 80 VehSpdLgtChks "0x37";
BA_ "GenSigSendType" SG_ 80 VehSpdLgtCntr 0;
BA_ "GenSigFuncType" SG_ 80 VehSpdLgtCntr 16;
BA_ "GenSigStartValue" SG_ 80 VehSpdLgtQf 1;
BA_ "GenSigSendType" SG_ 80 VehSpdLgtQf 0;
// Frame: CemBodyExpoCommonFr05
BA_ "GenMsgSendType" BO_ 384 1;
BA_ "GenMsgDelayTime" BO_ 384 120.000;
BA_ "GenSigSendType" SG_ 384 VehCfgPrmBlkIDBytePosn1 1;
BA_ "GenSigSendType" SG_ 384 VehCfgPrmCCPBytePosn2 1;
BA_ "GenSigSendType" SG_ 384 VehCfgPrmCCPBytePosn3 1;
BA_ "GenSigSendType" SG_ 384 VehCfgPrmCCPBytePosn4 1;
BA_ "GenSigSendType" SG_ 384 VehCfgPrmCCPBytePosn5 1;
BA_ "GenSigSendType" SG_ 384 VehCfgPrmCCPBytePosn6 1;
BA_ "GenSigSendType" SG_ 384 VehCfgPrmCCPBytePosn7 1;
BA_ "GenSigSendType" SG_ 384 VehCfgPrmCCPBytePosn8 1;
// Frame: CEMBodyExpoCommonFr06
BA_ "GenMsgSendType" BO_ 512 0;
BA_ "GenMsgCycleTime" BO_ 512 50.000;
BA_ "GenSigSendType" SG_ 512 BkpOfDstTrvld 0;
BA_ "GenSigSendType" SG_ 512 ExtrLiRlyPwrDwn 0;
BA_ "GenSigSendType" SG_ 512 VehBattUSysU 0;
BA_ "GenSigStartValue" SG_ 512 VehBattUSysUQf 1;
BA_ "GenSigSendType" SG_ 512 VehBattUSysUQf 0;
// Frame: CEMBodyExpoCommonFr07
BA_ "GenMsgSendType" BO_ 544 0;
BA_ "GenMsgCycleTime" BO_ 544 60.000;
BA_ "GenSigSendType" SG_ 544 ActnOfLedFrntCrossLamp 0;
BA_ "GenSigSendType" SG_ 544 ActnOfLedGrilleLamp 0;
BA_ "GenSigSendType" SG_ 544 ActnOfLedLeLogoLamp 0;
BA_ "GenSigSendType" SG_ 544 ActnOfLedRiLogoLamp 0;
BA_ "GenSigSendType" SG_ 544 Body2CntrForMissCom 0;
BA_ "GenSigSendType" SG_ 544 CarTiGlb 0;
BA_ "GenSigSendType" SG_ 544 TrSts 0;
// Frame: CemBodyExpoCommonFr08
BA_ "GenMsgSendType" BO_ 128 0;
BA_ "GenMsgCycleTime" BO_ 128 20.000;
BA_ "GenSigSendType" SG_ 128 AccrPedlRatAccrPedlRat 0;
BA_ "GenSigSendType" SG_ 128 AccrPedlRatChks 0;
BA_ "GenSigFuncType" SG_ 128 AccrPedlRatChks 15;
BA_ "GenSigDataID" SG_ 128 AccrPedlRatChks "0x364";
BA_ "GenSigSendType" SG_ 128 AccrPedlRatCntr 0;
BA_ "GenSigFuncType" SG_ 128 AccrPedlRatCntr 16;
BA_ "GenSigStartValue" SG_ 128 AmbTRawAmbTVal 700;
BA_ "GenSigSendType" SG_ 128 AmbTRawAmbTVal 0;
BA_ "GenSigSendType" SG_ 128 AmbTRawQly 0;
BA_ "GenSigSendType" SG_ 128 BrkPedlSnsrChks 0;
BA_ "GenSigFuncType" SG_ 128 BrkPedlSnsrChks 15;
BA_ "GenSigDataID" SG_ 128 BrkPedlSnsrChks "0xAF";
BA_ "GenSigSendType" SG_ 128 BrkPedlSnsrCntr 0;
BA_ "GenSigFuncType" SG_ 128 BrkPedlSnsrCntr 16;
BA_ "GenSigSendType" SG_ 128 BrkPedlSnsrQf 0;
BA_ "GenSigSendType" SG_ 128 BrkPedlSnsrSt 0;
BA_ "GenSigSendType" SG_ 128 TooManyCars 0;
// Frame: CemBodyExpoCommonFr09
BA_ "GenMsgSendType" BO_ 387 1;
BA_ "GenMsgDelayTime" BO_ 387 120.000;
BA_ "GenSigSendType" SG_ 387 VehCfgPrmExtBlkIDBytePosn1 1;
BA_ "GenSigSendType" SG_ 387 VehCfgPrmExtCCPBytePosn2 1;
BA_ "GenSigSendType" SG_ 387 VehCfgPrmExtCCPBytePosn3 1;
BA_ "GenSigSendType" SG_ 387 VehCfgPrmExtCCPBytePosn4 1;
BA_ "GenSigSendType" SG_ 387 VehCfgPrmExtCCPBytePosn5 1;
BA_ "GenSigSendType" SG_ 387 VehCfgPrmExtCCPBytePosn6 1;
BA_ "GenSigSendType" SG_ 387 VehCfgPrmExtCCPBytePosn7 1;
BA_ "GenSigSendType" SG_ 387 VehCfgPrmExtCCPBytePosn8 1;
// Frame: CemBodyExpoCommonFr10
BA_ "GenMsgSendType" BO_ 389 0;
BA_ "GenMsgCycleTime" BO_ 389 45.000;
BA_ "GenSigSendType" SG_ 389 TrafficSignForADB1AdbAbsDist 0;
BA_ "GenSigSendType" SG_ 389 TrafficSignForADB1AdbDetdQly 0;
BA_ "GenSigStartValue" SG_ 389 TrafficSignForADB1AdbHozlAgLe 800;
BA_ "GenSigSendType" SG_ 389 TrafficSignForADB1AdbHozlAgLe 0;
BA_ "GenSigStartValue" SG_ 389 TrafficSignForADB1AdbHozlAgRi 800;
BA_ "GenSigSendType" SG_ 389 TrafficSignForADB1AdbHozlAgRi 0;
BA_ "GenSigSendType" SG_ 389 TrafficSignForADB1AdbTrkInfo 0;
BA_ "GenSigStartValue" SG_ 389 TrafficSignForADB1AdbVertAgBot 60;
BA_ "GenSigSendType" SG_ 389 TrafficSignForADB1AdbVertAgBot 0;
BA_ "GenSigStartValue" SG_ 389 TrafficSignForADB1AdbVertAgTop 60;
BA_ "GenSigSendType" SG_ 389 TrafficSignForADB1AdbVertAgTop 0;
// Frame: CemBodyExpoCommonFr11
BA_ "GenMsgSendType" BO_ 390 0;
BA_ "GenMsgCycleTime" BO_ 390 45.000;
BA_ "GenSigSendType" SG_ 390 TrafficSignForADB2AdbAbsDist 0;
BA_ "GenSigSendType" SG_ 390 TrafficSignForADB2AdbDetdQly 0;
BA_ "GenSigStartValue" SG_ 390 TrafficSignForADB2AdbHozlAgLe 800;
BA_ "GenSigSendType" SG_ 390 TrafficSignForADB2AdbHozlAgLe 0;
BA_ "GenSigStartValue" SG_ 390 TrafficSignForADB2AdbHozlAgRi 800;
BA_ "GenSigSendType" SG_ 390 TrafficSignForADB2AdbHozlAgRi 0;
BA_ "GenSigSendType" SG_ 390 TrafficSignForADB2AdbTrkInfo 0;
BA_ "GenSigStartValue" SG_ 390 TrafficSignForADB2AdbVertAgBot 60;
BA_ "GenSigSendType" SG_ 390 TrafficSignForADB2AdbVertAgBot 0;
BA_ "GenSigStartValue" SG_ 390 TrafficSignForADB2AdbVertAgTop 60;
BA_ "GenSigSendType" SG_ 390 TrafficSignForADB2AdbVertAgTop 0;
// Frame: CemBodyExpoCommonFr12
BA_ "GenMsgSendType" BO_ 391 0;
BA_ "GenMsgCycleTime" BO_ 391 45.000;
BA_ "GenSigSendType" SG_ 391 VehObjforAHBAdbAbsDist 0;
BA_ "GenSigSendType" SG_ 391 VehObjforAHBAdbClassn 0;
BA_ "GenSigSendType" SG_ 391 VehObjforAHBAdbClassnQly 0;
BA_ "GenSigSendType" SG_ 391 VehObjforAHBAdbDetdQly 0;
BA_ "GenSigStartValue" SG_ 391 VehObjforAHBAdbHozlAg 800;
BA_ "GenSigSendType" SG_ 391 VehObjforAHBAdbHozlAg 0;
BA_ "GenSigSendType" SG_ 391 VehObjforAHBAdbObjDir 0;
BA_ "GenSigStartValue" SG_ 391 VehObjforAHBAdbObjHozlAgSpd 2880;
BA_ "GenSigSendType" SG_ 391 VehObjforAHBAdbObjHozlAgSpd 0;
BA_ "GenSigStartValue" SG_ 391 VehObjforAHBAdbObjVertAgSpd 720;
BA_ "GenSigSendType" SG_ 391 VehObjforAHBAdbObjVertAgSpd 0;
BA_ "GenSigSendType" SG_ 391 VehObjforAHBAdbTrkInfo 0;
BA_ "GenSigStartValue" SG_ 391 VehObjforAHBAdbVertAg 75;
BA_ "GenSigSendType" SG_ 391 VehObjforAHBAdbVertAg 0;
// Frame: CemBodyExpoCommonFr13
BA_ "GenMsgSendType" BO_ 392 0;
BA_ "GenMsgCycleTime" BO_ 392 45.000;
BA_ "GenSigSendType" SG_ 392 VehObjforADB1AdbAbsDist 0;
BA_ "GenSigSendType" SG_ 392 VehObjforADB1AdbClassn 0;
BA_ "GenSigStartValue" SG_ 392 VehObjforADB1AdbHozlAgLe 800;
BA_ "GenSigSendType" SG_ 392 VehObjforADB1AdbHozlAgLe 0;
BA_ "GenSigStartValue" SG_ 392 VehObjforADB1AdbHozlAgRi 800;
BA_ "GenSigSendType" SG_ 392 VehObjforADB1AdbHozlAgRi 0;
BA_ "GenSigSendType" SG_ 392 VehObjforADB1AdbObjDir 0;
BA_ "GenSigStartValue" SG_ 392 VehObjforADB1AdbObjHozlAgSpdLe 250;
BA_ "GenSigSendType" SG_ 392 VehObjforADB1AdbObjHozlAgSpdLe 0;
BA_ "GenSigStartValue" SG_ 392 VehObjforADB1AdbObjHozlAgSpdRi 250;
BA_ "GenSigSendType" SG_ 392 VehObjforADB1AdbObjHozlAgSpdRi 0;
BA_ "GenSigSendType" SG_ 392 VehObjforADB1AdbTrkInfo 0;
BA_ "GenSigStartValue" SG_ 392 VehObjforADB1AdbVertAg 6;
BA_ "GenSigSendType" SG_ 392 VehObjforADB1AdbVertAg 0;
// Frame: CemBodyExpoCommonFr14
BA_ "GenMsgSendType" BO_ 393 0;
BA_ "GenMsgCycleTime" BO_ 393 45.000;
BA_ "GenSigSendType" SG_ 393 VehObjforADB2AdbAbsDist 0;
BA_ "GenSigSendType" SG_ 393 VehObjforADB2AdbClassn 0;
BA_ "GenSigStartValue" SG_ 393 VehObjforADB2AdbHozlAgLe 800;
BA_ "GenSigSendType" SG_ 393 VehObjforADB2AdbHozlAgLe 0;
BA_ "GenSigStartValue" SG_ 393 VehObjforADB2AdbHozlAgRi 800;
BA_ "GenSigSendType" SG_ 393 VehObjforADB2AdbHozlAgRi 0;
BA_ "GenSigSendType" SG_ 393 VehObjforADB2AdbObjDir 0;
BA_ "GenSigStartValue" SG_ 393 VehObjforADB2AdbObjHozlAgSpdLe 250;
BA_ "GenSigSendType" SG_ 393 VehObjforADB2AdbObjHozlAgSpdLe 0;
BA_ "GenSigStartValue" SG_ 393 VehObjforADB2AdbObjHozlAgSpdRi 250;
BA_ "GenSigSendType" SG_ 393 VehObjforADB2AdbObjHozlAgSpdRi 0;
BA_ "GenSigSendType" SG_ 393 VehObjforADB2AdbTrkInfo 0;
BA_ "GenSigStartValue" SG_ 393 VehObjforADB2AdbVertAg 6;
BA_ "GenSigSendType" SG_ 393 VehObjforADB2AdbVertAg 0;
// Frame: CemBodyExpoCommonFr15
BA_ "GenMsgSendType" BO_ 394 0;
BA_ "GenMsgCycleTime" BO_ 394 45.000;
BA_ "GenSigSendType" SG_ 394 VehObjforADB3AdbAbsDist 0;
BA_ "GenSigSendType" SG_ 394 VehObjforADB3AdbClassn 0;
BA_ "GenSigStartValue" SG_ 394 VehObjforADB3AdbHozlAgLe 800;
BA_ "GenSigSendType" SG_ 394 VehObjforADB3AdbHozlAgLe 0;
BA_ "GenSigStartValue" SG_ 394 VehObjforADB3AdbHozlAgRi 800;
BA_ "GenSigSendType" SG_ 394 VehObjforADB3AdbHozlAgRi 0;
BA_ "GenSigSendType" SG_ 394 VehObjforADB3AdbObjDir 0;
BA_ "GenSigStartValue" SG_ 394 VehObjforADB3AdbObjHozlAgSpdLe 250;
BA_ "GenSigSendType" SG_ 394 VehObjforADB3AdbObjHozlAgSpdLe 0;
BA_ "GenSigStartValue" SG_ 394 VehObjforADB3AdbObjHozlAgSpdRi 250;
BA_ "GenSigSendType" SG_ 394 VehObjforADB3AdbObjHozlAgSpdRi 0;
BA_ "GenSigSendType" SG_ 394 VehObjforADB3AdbTrkInfo 0;
BA_ "GenSigStartValue" SG_ 394 VehObjforADB3AdbVertAg 6;
BA_ "GenSigSendType" SG_ 394 VehObjforADB3AdbVertAg 0;
// Frame: CemBodyExpoCommonFr16
BA_ "GenMsgSendType" BO_ 395 0;
BA_ "GenMsgCycleTime" BO_ 395 45.000;
BA_ "GenSigSendType" SG_ 395 VehObjforADB4AdbAbsDist 0;
BA_ "GenSigSendType" SG_ 395 VehObjforADB4AdbClassn 0;
BA_ "GenSigStartValue" SG_ 395 VehObjforADB4AdbHozlAgLe 800;
BA_ "GenSigSendType" SG_ 395 VehObjforADB4AdbHozlAgLe 0;
BA_ "GenSigStartValue" SG_ 395 VehObjforADB4AdbHozlAgRi 800;
BA_ "GenSigSendType" SG_ 395 VehObjforADB4AdbHozlAgRi 0;
BA_ "GenSigSendType" SG_ 395 VehObjforADB4AdbObjDir 0;
BA_ "GenSigStartValue" SG_ 395 VehObjforADB4AdbObjHozlAgSpdLe 250;
BA_ "GenSigSendType" SG_ 395 VehObjforADB4AdbObjHozlAgSpdLe 0;
BA_ "GenSigStartValue" SG_ 395 VehObjforADB4AdbObjHozlAgSpdRi 250;
BA_ "GenSigSendType" SG_ 395 VehObjforADB4AdbObjHozlAgSpdRi 0;
BA_ "GenSigSendType" SG_ 395 VehObjforADB4AdbTrkInfo 0;
BA_ "GenSigStartValue" SG_ 395 VehObjforADB4AdbVertAg 6;
BA_ "GenSigSendType" SG_ 395 VehObjforADB4AdbVertAg 0;
// Frame: CemBodyExpoCommonFr17
BA_ "GenMsgSendType" BO_ 396 0;
BA_ "GenMsgCycleTime" BO_ 396 45.000;
BA_ "GenSigSendType" SG_ 396 VehObjforADB5AdbAbsDist 0;
BA_ "GenSigSendType" SG_ 396 VehObjforADB5AdbClassn 0;
BA_ "GenSigStartValue" SG_ 396 VehObjforADB5AdbHozlAgLe 800;
BA_ "GenSigSendType" SG_ 396 VehObjforADB5AdbHozlAgLe 0;
BA_ "GenSigStartValue" SG_ 396 VehObjforADB5AdbHozlAgRi 800;
BA_ "GenSigSendType" SG_ 396 VehObjforADB5AdbHozlAgRi 0;
BA_ "GenSigSendType" SG_ 396 VehObjforADB5AdbObjDir 0;
BA_ "GenSigStartValue" SG_ 396 VehObjforADB5AdbObjHozlAgSpdLe 250;
BA_ "GenSigSendType" SG_ 396 VehObjforADB5AdbObjHozlAgSpdLe 0;
BA_ "GenSigStartValue" SG_ 396 VehObjforADB5AdbObjHozlAgSpdRi 250;
BA_ "GenSigSendType" SG_ 396 VehObjforADB5AdbObjHozlAgSpdRi 0;
BA_ "GenSigSendType" SG_ 396 VehObjforADB5AdbTrkInfo 0;
BA_ "GenSigStartValue" SG_ 396 VehObjforADB5AdbVertAg 6;
BA_ "GenSigSendType" SG_ 396 VehObjforADB5AdbVertAg 0;
// Frame: CemBodyExpoCommonFr18
BA_ "GenMsgSendType" BO_ 397 0;
BA_ "GenMsgCycleTime" BO_ 397 45.000;
BA_ "GenSigSendType" SG_ 397 VehObjforADB6AdbAbsDist 0;
BA_ "GenSigSendType" SG_ 397 VehObjforADB6AdbClassn 0;
BA_ "GenSigStartValue" SG_ 397 VehObjforADB6AdbHozlAgLe 800;
BA_ "GenSigSendType" SG_ 397 VehObjforADB6AdbHozlAgLe 0;
BA_ "GenSigStartValue" SG_ 397 VehObjforADB6AdbHozlAgRi 800;
BA_ "GenSigSendType" SG_ 397 VehObjforADB6AdbHozlAgRi 0;
BA_ "GenSigSendType" SG_ 397 VehObjforADB6AdbObjDir 0;
BA_ "GenSigStartValue" SG_ 397 VehObjforADB6AdbObjHozlAgSpdLe 250;
BA_ "GenSigSendType" SG_ 397 VehObjforADB6AdbObjHozlAgSpdLe 0;
BA_ "GenSigStartValue" SG_ 397 VehObjforADB6AdbObjHozlAgSpdRi 250;
BA_ "GenSigSendType" SG_ 397 VehObjforADB6AdbObjHozlAgSpdRi 0;
BA_ "GenSigSendType" SG_ 397 VehObjforADB6AdbTrkInfo 0;
BA_ "GenSigStartValue" SG_ 397 VehObjforADB6AdbVertAg 6;
BA_ "GenSigSendType" SG_ 397 VehObjforADB6AdbVertAg 0;
// Frame: CemBodyExpoCommonFr19
BA_ "GenMsgSendType" BO_ 398 0;
BA_ "GenMsgCycleTime" BO_ 398 45.000;
BA_ "GenSigSendType" SG_ 398 VehObjforADB7AdbAbsDist 0;
BA_ "GenSigSendType" SG_ 398 VehObjforADB7AdbClassn 0;
BA_ "GenSigStartValue" SG_ 398 VehObjforADB7AdbHozlAgLe 800;
BA_ "GenSigSendType" SG_ 398 VehObjforADB7AdbHozlAgLe 0;
BA_ "GenSigStartValue" SG_ 398 VehObjforADB7AdbHozlAgRi 800;
BA_ "GenSigSendType" SG_ 398 VehObjforADB7AdbHozlAgRi 0;
BA_ "GenSigSendType" SG_ 398 VehObjforADB7AdbObjDir 0;
BA_ "GenSigStartValue" SG_ 398 VehObjforADB7AdbObjHozlAgSpdLe 250;
BA_ "GenSigSendType" SG_ 398 VehObjforADB7AdbObjHozlAgSpdLe 0;
BA_ "GenSigStartValue" SG_ 398 VehObjforADB7AdbObjHozlAgSpdRi 250;
BA_ "GenSigSendType" SG_ 398 VehObjforADB7AdbObjHozlAgSpdRi 0;
BA_ "GenSigSendType" SG_ 398 VehObjforADB7AdbTrkInfo 0;
BA_ "GenSigStartValue" SG_ 398 VehObjforADB7AdbVertAg 6;
BA_ "GenSigSendType" SG_ 398 VehObjforADB7AdbVertAg 0;
// Frame: CemBodyExpoCommonFr20
BA_ "GenMsgSendType" BO_ 399 0;
BA_ "GenMsgCycleTime" BO_ 399 45.000;
BA_ "GenSigSendType" SG_ 399 VehObjforADB8AdbAbsDist 0;
BA_ "GenSigSendType" SG_ 399 VehObjforADB8AdbClassn 0;
BA_ "GenSigStartValue" SG_ 399 VehObjforADB8AdbHozlAgLe 800;
BA_ "GenSigSendType" SG_ 399 VehObjforADB8AdbHozlAgLe 0;
BA_ "GenSigStartValue" SG_ 399 VehObjforADB8AdbHozlAgRi 800;
BA_ "GenSigSendType" SG_ 399 VehObjforADB8AdbHozlAgRi 0;
BA_ "GenSigSendType" SG_ 399 VehObjforADB8AdbObjDir 0;
BA_ "GenSigStartValue" SG_ 399 VehObjforADB8AdbObjHozlAgSpdLe 250;
BA_ "GenSigSendType" SG_ 399 VehObjforADB8AdbObjHozlAgSpdLe 0;
BA_ "GenSigStartValue" SG_ 399 VehObjforADB8AdbObjHozlAgSpdRi 250;
BA_ "GenSigSendType" SG_ 399 VehObjforADB8AdbObjHozlAgSpdRi 0;
BA_ "GenSigSendType" SG_ 399 VehObjforADB8AdbTrkInfo 0;
BA_ "GenSigStartValue" SG_ 399 VehObjforADB8AdbVertAg 6;
BA_ "GenSigSendType" SG_ 399 VehObjforADB8AdbVertAg 0;
// Frame: CemBodyExpoCommonFr21
BA_ "GenMsgSendType" BO_ 64 0;
BA_ "GenMsgCycleTime" BO_ 64 15.000;
BA_ "GenSigSendType" SG_ 64 CameraStsforAHBC 0;
BA_ "GenSigSendType" SG_ 64 RainLi 0;
BA_ "GenSigSendType" SG_ 64 VehModMngtGlbSafe1CarModSts1 0;
BA_ "GenSigSendType" SG_ 64 VehModMngtGlbSafe1CarModSubtypWdCarModSubtyp 0;
BA_ "GenSigSendType" SG_ 64 VehModMngtGlbSafe1Chks 0;
BA_ "GenSigFuncType" SG_ 64 VehModMngtGlbSafe1Chks 15;
BA_ "GenSigDataID" SG_ 64 VehModMngtGlbSafe1Chks "0x74";
BA_ "GenSigSendType" SG_ 64 VehModMngtGlbSafe1Cntr 0;
BA_ "GenSigFuncType" SG_ 64 VehModMngtGlbSafe1Cntr 16;
BA_ "GenSigSendType" SG_ 64 VehModMngtGlbSafe1EgyLvlElecMai 0;
BA_ "GenSigSendType" SG_ 64 VehModMngtGlbSafe1EgyLvlElecSubtyp 0;
BA_ "GenSigSendType" SG_ 64 VehModMngtGlbSafe1FltEgyCnsWdSts 0;
BA_ "GenSigSendType" SG_ 64 VehModMngtGlbSafe1PwrLvlElecMai 0;
BA_ "GenSigSendType" SG_ 64 VehModMngtGlbSafe1PwrLvlElecSubtyp 0;
BA_ "GenSigStartValue" SG_ 64 VehModMngtGlbSafe1UsgModSts 1;
BA_ "GenSigSendType" SG_ 64 VehModMngtGlbSafe1UsgModSts 0;
BA_ "GenSigSendType" SG_ 64 WipgAutFrntMod 0;
// Frame: CemBodyExpoCommonFr22
BA_ "GenMsgSendType" BO_ 400 0;
BA_ "GenMsgCycleTime" BO_ 400 45.000;
BA_ "GenSigStartValue" SG_ 400 SuspPosnVertAgGenQf 1;
BA_ "GenSigSendType" SG_ 400 SuspPosnVertAgGenQf 0;
BA_ "GenSigSendType" SG_ 400 SuspPosnVertAgSuspPosnVertAg 0;
BA_ "GenSigSendType" SG_ 400 SuspPosnVertLvlFrnt 0;
BA_ "GenSigSendType" SG_ 400 SuspPosnVertLvlFrntQf 0;
BA_ "GenSigSendType" SG_ 400 SuspPosnVertLvlRe 0;
BA_ "GenSigSendType" SG_ 400 SuspPosnVertLvlReQf 0;
// Frame: CemBodyExpoDevDiagFr01
BA_ "GenMsgSendType" BO_ 1432 1;
BA_ "GenMsgDelayTime" BO_ 1432 95.000;
BA_ "GenSigSendType" SG_ 1432 CEMdevelpsignalgrouprespFunctiondevpsignalgroup1 1;
BA_ "GenSigSendType" SG_ 1432 CEMdevelpsignalgrouprespFunctiondevpsignalgroup2 1;
BA_ "GenSigSendType" SG_ 1432 CEMdevelpsignalgrouprespFunctiondevpsignalgroup3 1;
BA_ "GenSigSendType" SG_ 1432 CEMdevelpsignalgrouprespFunctiondevpsignalgroup4 1;
BA_ "GenSigSendType" SG_ 1432 CEMdevelpsignalgrouprespFunctiondevpsignalgroup5 1;
BA_ "GenSigSendType" SG_ 1432 CEMdevelpsignalgrouprespFunctiondevpsignalgroup6 1;
BA_ "GenSigSendType" SG_ 1432 CEMdevelpsignalgrouprespFunctiondevpsignalgroup7 1;
BA_ "GenSigSendType" SG_ 1432 CEMdevelpsignalgrouprespFunctiondevpsignalgroup8 1;
// Frame: CemBodyExpoDevFr02
BA_ "GenMsgSendType" BO_ 1431 1;
BA_ "GenMsgDelayTime" BO_ 1431 95.000;
BA_ "GenSigSendType" SG_ 1431 CEMdevelpsignalgroupcheckFunctiondevpsignalgroup1 1;
BA_ "GenSigSendType" SG_ 1431 CEMdevelpsignalgroupcheckFunctiondevpsignalgroup2 1;
BA_ "GenSigSendType" SG_ 1431 CEMdevelpsignalgroupcheckFunctiondevpsignalgroup3 1;
BA_ "GenSigSendType" SG_ 1431 CEMdevelpsignalgroupcheckFunctiondevpsignalgroup4 1;
BA_ "GenSigSendType" SG_ 1431 CEMdevelpsignalgroupcheckFunctiondevpsignalgroup5 1;
BA_ "GenSigSendType" SG_ 1431 CEMdevelpsignalgroupcheckFunctiondevpsignalgroup6 1;
BA_ "GenSigSendType" SG_ 1431 CEMdevelpsignalgroupcheckFunctiondevpsignalgroup7 1;
BA_ "GenSigSendType" SG_ 1431 CEMdevelpsignalgroupcheckFunctiondevpsignalgroup8 1;
// Frame: CemBodyExpoFr01
BA_ "GenMsgSendType" BO_ 28 1;
BA_ "GenMsgDelayTime" BO_ 28 30.000;
BA_ "GenSigSendType" SG_ 28 CarpetLiActvReq 1;
BA_ "GenSigSendType" SG_ 28 ExtrLiShowActvnReq 1;
BA_ "GenSigSendType" SG_ 28 ExtrLiShowFileTxReq 1;
// Frame: CemBodyExpoFr02
BA_ "GenMsgSendType" BO_ 288 1;
BA_ "GenMsgDelayTime" BO_ 288 30.000;
BA_ "GenSigSendType" SG_ 288 DwnLoadDynLitPrmForLedStopLampRi2ContTiPrm 1;
BA_ "SigGroup" SG_ 288 DwnLoadDynLitPrmForLedStopLampRi2ContTiPrm "DwnLoadDynLitPrmForLedStopLampRi2";
BA_ "GenSigSendType" SG_ 288 DwnLoadDynLitPrmForLedStopLampRi2LowBriPrm 1;
BA_ "SigGroup" SG_ 288 DwnLoadDynLitPrmForLedStopLampRi2LowBriPrm "DwnLoadDynLitPrmForLedStopLampRi2";
BA_ "GenSigSendType" SG_ 288 DwnLoadDynLitPrmForLedStopLampRi2ModePrm 1;
BA_ "SigGroup" SG_ 288 DwnLoadDynLitPrmForLedStopLampRi2ModePrm "DwnLoadDynLitPrmForLedStopLampRi2";
BA_ "GenSigSendType" SG_ 288 DwnLoadDynLitPrmForLedStopLampRi2OffsTiPrm 1;
BA_ "SigGroup" SG_ 288 DwnLoadDynLitPrmForLedStopLampRi2OffsTiPrm "DwnLoadDynLitPrmForLedStopLampRi2";
BA_ "GenSigSendType" SG_ 288 DwnLoadDynLitPrmForLedStopLampRi2Tistamp 1;
BA_ "SigGroup" SG_ 288 DwnLoadDynLitPrmForLedStopLampRi2Tistamp "DwnLoadDynLitPrmForLedStopLampRi2";
BA_ "GenSigSendType" SG_ 288 DwnLoadDynLitPrmForLedStopLampRi2UpprBriPrm 1;
BA_ "SigGroup" SG_ 288 DwnLoadDynLitPrmForLedStopLampRi2UpprBriPrm "DwnLoadDynLitPrmForLedStopLampRi2";
// Frame: CemBodyExpoFr03
BA_ "GenMsgSendType" BO_ 289 1;
BA_ "GenMsgDelayTime" BO_ 289 30.000;
BA_ "GenSigSendType" SG_ 289 DwnLoadDynLitPrmLedReFogLampRi2ContTiPrm 1;
BA_ "GenSigSendType" SG_ 289 DwnLoadDynLitPrmLedReFogLampRi2LowBriPrm 1;
BA_ "GenSigSendType" SG_ 289 DwnLoadDynLitPrmLedReFogLampRi2ModePrm 1;
BA_ "GenSigSendType" SG_ 289 DwnLoadDynLitPrmLedReFogLampRi2OffsTiPrm 1;
BA_ "GenSigSendType" SG_ 289 DwnLoadDynLitPrmLedReFogLampRi2Tistamp 1;
BA_ "GenSigSendType" SG_ 289 DwnLoadDynLitPrmLedReFogLampRi2UpprBriPrm 1;
// Frame: CemBodyExpoFr04
BA_ "GenMsgSendType" BO_ 290 1;
BA_ "GenMsgDelayTime" BO_ 290 30.000;
BA_ "GenSigSendType" SG_ 290 DwnLoadDynLitPrmLedRePosnLampRi2ContTiPrm 1;
BA_ "SigGroup" SG_ 290 DwnLoadDynLitPrmLedRePosnLampRi2ContTiPrm "DwnLoadDynLitPrmLedRePosnLampRi2";
BA_ "GenSigSendType" SG_ 290 DwnLoadDynLitPrmLedRePosnLampRi2LowBriPrm 1;
BA_ "SigGroup" SG_ 290 DwnLoadDynLitPrmLedRePosnLampRi2LowBriPrm "DwnLoadDynLitPrmLedRePosnLampRi2";
BA_ "GenSigSendType" SG_ 290 DwnLoadDynLitPrmLedRePosnLampRi2ModePrm 1;
BA_ "SigGroup" SG_ 290 DwnLoadDynLitPrmLedRePosnLampRi2ModePrm "DwnLoadDynLitPrmLedRePosnLampRi2";
BA_ "GenSigSendType" SG_ 290 DwnLoadDynLitPrmLedRePosnLampRi2OffsTiPrm 1;
BA_ "SigGroup" SG_ 290 DwnLoadDynLitPrmLedRePosnLampRi2OffsTiPrm "DwnLoadDynLitPrmLedRePosnLampRi2";
BA_ "GenSigSendType" SG_ 290 DwnLoadDynLitPrmLedRePosnLampRi2Tistamp 1;
BA_ "SigGroup" SG_ 290 DwnLoadDynLitPrmLedRePosnLampRi2Tistamp "DwnLoadDynLitPrmLedRePosnLampRi2";
BA_ "GenSigSendType" SG_ 290 DwnLoadDynLitPrmLedRePosnLampRi2UpprBriPrm 1;
BA_ "SigGroup" SG_ 290 DwnLoadDynLitPrmLedRePosnLampRi2UpprBriPrm "DwnLoadDynLitPrmLedRePosnLampRi2";
// Frame: CemBodyExpoFr05
BA_ "GenMsgSendType" BO_ 291 1;
BA_ "GenMsgDelayTime" BO_ 291 30.000;
BA_ "GenSigSendType" SG_ 291 DwnLoadDynLitPrmLedReTurnIndcrRi2ContTiPrm 1;
BA_ "SigGroup" SG_ 291 DwnLoadDynLitPrmLedReTurnIndcrRi2ContTiPrm "DwnLoadDynLitPrmLedReTurnIndcrRi2";
BA_ "GenSigSendType" SG_ 291 DwnLoadDynLitPrmLedReTurnIndcrRi2LowBriPrm 1;
BA_ "SigGroup" SG_ 291 DwnLoadDynLitPrmLedReTurnIndcrRi2LowBriPrm "DwnLoadDynLitPrmLedReTurnIndcrRi2";
BA_ "GenSigSendType" SG_ 291 DwnLoadDynLitPrmLedReTurnIndcrRi2ModePrm 1;
BA_ "SigGroup" SG_ 291 DwnLoadDynLitPrmLedReTurnIndcrRi2ModePrm "DwnLoadDynLitPrmLedReTurnIndcrRi2";
BA_ "GenSigSendType" SG_ 291 DwnLoadDynLitPrmLedReTurnIndcrRi2OffsTiPrm 1;
BA_ "SigGroup" SG_ 291 DwnLoadDynLitPrmLedReTurnIndcrRi2OffsTiPrm "DwnLoadDynLitPrmLedReTurnIndcrRi2";
BA_ "GenSigSendType" SG_ 291 DwnLoadDynLitPrmLedReTurnIndcrRi2Tistamp 1;
BA_ "SigGroup" SG_ 291 DwnLoadDynLitPrmLedReTurnIndcrRi2Tistamp "DwnLoadDynLitPrmLedReTurnIndcrRi2";
BA_ "GenSigSendType" SG_ 291 DwnLoadDynLitPrmLedReTurnIndcrRi2UpprBriPrm 1;
BA_ "SigGroup" SG_ 291 DwnLoadDynLitPrmLedReTurnIndcrRi2UpprBriPrm "DwnLoadDynLitPrmLedReTurnIndcrRi2";
// Frame: CemBodyExpoFr06
BA_ "GenMsgSendType" BO_ 292 1;
BA_ "GenMsgDelayTime" BO_ 292 30.000;
BA_ "GenSigSendType" SG_ 292 DwnLoadDynLitPrmForLedMkrLampLe1ContTiPrm 1;
BA_ "SigGroup" SG_ 292 DwnLoadDynLitPrmForLedMkrLampLe1ContTiPrm "DwnLoadDynLitPrmForLedMkrLampLe1";
BA_ "GenSigSendType" SG_ 292 DwnLoadDynLitPrmForLedMkrLampLe1LowBriPrm 1;
BA_ "SigGroup" SG_ 292 DwnLoadDynLitPrmForLedMkrLampLe1LowBriPrm "DwnLoadDynLitPrmForLedMkrLampLe1";
BA_ "GenSigSendType" SG_ 292 DwnLoadDynLitPrmForLedMkrLampLe1ModePrm 1;
BA_ "SigGroup" SG_ 292 DwnLoadDynLitPrmForLedMkrLampLe1ModePrm "DwnLoadDynLitPrmForLedMkrLampLe1";
BA_ "GenSigSendType" SG_ 292 DwnLoadDynLitPrmForLedMkrLampLe1OffsTiPrm 1;
BA_ "SigGroup" SG_ 292 DwnLoadDynLitPrmForLedMkrLampLe1OffsTiPrm "DwnLoadDynLitPrmForLedMkrLampLe1";
BA_ "GenSigSendType" SG_ 292 DwnLoadDynLitPrmForLedMkrLampLe1Tistamp 1;
BA_ "SigGroup" SG_ 292 DwnLoadDynLitPrmForLedMkrLampLe1Tistamp "DwnLoadDynLitPrmForLedMkrLampLe1";
BA_ "GenSigSendType" SG_ 292 DwnLoadDynLitPrmForLedMkrLampLe1UpprBriPrm 1;
BA_ "SigGroup" SG_ 292 DwnLoadDynLitPrmForLedMkrLampLe1UpprBriPrm "DwnLoadDynLitPrmForLedMkrLampLe1";
// Frame: CemBodyExpoFr07
BA_ "GenMsgSendType" BO_ 293 1;
BA_ "GenMsgDelayTime" BO_ 293 30.000;
BA_ "GenSigSendType" SG_ 293 DwnLoadDynLtgPrmForLedLoBeamRiContTiPrm 1;
BA_ "GenSigSendType" SG_ 293 DwnLoadDynLtgPrmForLedLoBeamRiLowBriPrm 1;
BA_ "GenSigSendType" SG_ 293 DwnLoadDynLtgPrmForLedLoBeamRiModePrm 1;
BA_ "GenSigSendType" SG_ 293 DwnLoadDynLtgPrmForLedLoBeamRiOffsTiPrm 1;
BA_ "GenSigSendType" SG_ 293 DwnLoadDynLtgPrmForLedLoBeamRiTistamp 1;
BA_ "GenSigSendType" SG_ 293 DwnLoadDynLtgPrmForLedLoBeamRiUpprBriPrm 1;
// Frame: CemBodyExpoFr08
BA_ "GenMsgSendType" BO_ 294 1;
BA_ "GenMsgDelayTime" BO_ 294 30.000;
BA_ "GenSigSendType" SG_ 294 DwnLoadDynLitPrmForLedMkrLampLe2ContTiPrm 1;
BA_ "SigGroup" SG_ 294 DwnLoadDynLitPrmForLedMkrLampLe2ContTiPrm "DwnLoadDynLitPrmForLedMkrLampLe2";
BA_ "GenSigSendType" SG_ 294 DwnLoadDynLitPrmForLedMkrLampLe2LowBriPrm 1;
BA_ "SigGroup" SG_ 294 DwnLoadDynLitPrmForLedMkrLampLe2LowBriPrm "DwnLoadDynLitPrmForLedMkrLampLe2";
BA_ "GenSigSendType" SG_ 294 DwnLoadDynLitPrmForLedMkrLampLe2ModePrm 1;
BA_ "SigGroup" SG_ 294 DwnLoadDynLitPrmForLedMkrLampLe2ModePrm "DwnLoadDynLitPrmForLedMkrLampLe2";
BA_ "GenSigSendType" SG_ 294 DwnLoadDynLitPrmForLedMkrLampLe2OffsTiPrm 1;
BA_ "SigGroup" SG_ 294 DwnLoadDynLitPrmForLedMkrLampLe2OffsTiPrm "DwnLoadDynLitPrmForLedMkrLampLe2";
BA_ "GenSigSendType" SG_ 294 DwnLoadDynLitPrmForLedMkrLampLe2Tistamp 1;
BA_ "SigGroup" SG_ 294 DwnLoadDynLitPrmForLedMkrLampLe2Tistamp "DwnLoadDynLitPrmForLedMkrLampLe2";
BA_ "GenSigSendType" SG_ 294 DwnLoadDynLitPrmForLedMkrLampLe2UpprBriPrm 1;
BA_ "SigGroup" SG_ 294 DwnLoadDynLitPrmForLedMkrLampLe2UpprBriPrm "DwnLoadDynLitPrmForLedMkrLampLe2";
// Frame: CemBodyExpoFr09
BA_ "GenMsgSendType" BO_ 295 1;
BA_ "GenMsgDelayTime" BO_ 295 30.000;
BA_ "GenSigSendType" SG_ 295 DwnLoadDynLitPrmForLedMkrLampRi1ContTiPrm 1;
BA_ "SigGroup" SG_ 295 DwnLoadDynLitPrmForLedMkrLampRi1ContTiPrm "DwnLoadDynLitPrmForLedMkrLampRi1";
BA_ "GenSigSendType" SG_ 295 DwnLoadDynLitPrmForLedMkrLampRi1LowBriPrm 1;
BA_ "SigGroup" SG_ 295 DwnLoadDynLitPrmForLedMkrLampRi1LowBriPrm "DwnLoadDynLitPrmForLedMkrLampRi1";
BA_ "GenSigSendType" SG_ 295 DwnLoadDynLitPrmForLedMkrLampRi1ModePrm 1;
BA_ "SigGroup" SG_ 295 DwnLoadDynLitPrmForLedMkrLampRi1ModePrm "DwnLoadDynLitPrmForLedMkrLampRi1";
BA_ "GenSigSendType" SG_ 295 DwnLoadDynLitPrmForLedMkrLampRi1OffsTiPrm 1;
BA_ "SigGroup" SG_ 295 DwnLoadDynLitPrmForLedMkrLampRi1OffsTiPrm "DwnLoadDynLitPrmForLedMkrLampRi1";
BA_ "GenSigSendType" SG_ 295 DwnLoadDynLitPrmForLedMkrLampRi1Tistamp 1;
BA_ "SigGroup" SG_ 295 DwnLoadDynLitPrmForLedMkrLampRi1Tistamp "DwnLoadDynLitPrmForLedMkrLampRi1";
BA_ "GenSigSendType" SG_ 295 DwnLoadDynLitPrmForLedMkrLampRi1UpprBriPrm 1;
BA_ "SigGroup" SG_ 295 DwnLoadDynLitPrmForLedMkrLampRi1UpprBriPrm "DwnLoadDynLitPrmForLedMkrLampRi1";
// Frame: CemBodyExpoFr10
BA_ "GenMsgSendType" BO_ 296 1;
BA_ "GenMsgDelayTime" BO_ 296 30.000;
BA_ "GenSigSendType" SG_ 296 DwnLoadDynLitPrmForLedStopLampLe1ContTiPrm 1;
BA_ "SigGroup" SG_ 296 DwnLoadDynLitPrmForLedStopLampLe1ContTiPrm "DwnLoadDynLitPrmForLedStopLampLe1";
BA_ "GenSigSendType" SG_ 296 DwnLoadDynLitPrmForLedStopLampLe1LowBriPrm 1;
BA_ "SigGroup" SG_ 296 DwnLoadDynLitPrmForLedStopLampLe1LowBriPrm "DwnLoadDynLitPrmForLedStopLampLe1";
BA_ "GenSigSendType" SG_ 296 DwnLoadDynLitPrmForLedStopLampLe1ModePrm 1;
BA_ "SigGroup" SG_ 296 DwnLoadDynLitPrmForLedStopLampLe1ModePrm "DwnLoadDynLitPrmForLedStopLampLe1";
BA_ "GenSigSendType" SG_ 296 DwnLoadDynLitPrmForLedStopLampLe1OffsTiPrm 1;
BA_ "SigGroup" SG_ 296 DwnLoadDynLitPrmForLedStopLampLe1OffsTiPrm "DwnLoadDynLitPrmForLedStopLampLe1";
BA_ "GenSigSendType" SG_ 296 DwnLoadDynLitPrmForLedStopLampLe1Tistamp 1;
BA_ "SigGroup" SG_ 296 DwnLoadDynLitPrmForLedStopLampLe1Tistamp "DwnLoadDynLitPrmForLedStopLampLe1";
BA_ "GenSigSendType" SG_ 296 DwnLoadDynLitPrmForLedStopLampLe1UpprBriPrm 1;
BA_ "SigGroup" SG_ 296 DwnLoadDynLitPrmForLedStopLampLe1UpprBriPrm "DwnLoadDynLitPrmForLedStopLampLe1";
// Frame: CemBodyExpoFr100
BA_ "GenMsgSendType" BO_ 834 1;
BA_ "GenMsgDelayTime" BO_ 834 30.000;
BA_ "GenSigSendType" SG_ 834 DwnLoadDynLtgPrmForFrntRIGrp10ContinueTime 1;
BA_ "GenSigSendType" SG_ 834 DwnLoadDynLtgPrmForFrntRIGrp10HighBrightness 1;
BA_ "GenSigSendType" SG_ 834 DwnLoadDynLtgPrmForFrntRIGrp10LowBrightness 1;
BA_ "GenSigSendType" SG_ 834 DwnLoadDynLtgPrmForFrntRIGrp10Mode1 1;
BA_ "GenSigSendType" SG_ 834 DwnLoadDynLtgPrmForFrntRIGrp10OffsetTime 1;
BA_ "GenSigSendType" SG_ 834 DwnLoadDynLtgPrmForFrntRIGrp10Timestamp 1;
// Frame: CemBodyExpoFr101
BA_ "GenMsgSendType" BO_ 835 1;
BA_ "GenMsgDelayTime" BO_ 835 30.000;
BA_ "GenSigSendType" SG_ 835 DwnLoadDynLtgPrmForFrntRIGrp11ContinueTime 1;
BA_ "GenSigSendType" SG_ 835 DwnLoadDynLtgPrmForFrntRIGrp11HighBrightness 1;
BA_ "GenSigSendType" SG_ 835 DwnLoadDynLtgPrmForFrntRIGrp11LowBrightness 1;
BA_ "GenSigSendType" SG_ 835 DwnLoadDynLtgPrmForFrntRIGrp11Mode1 1;
BA_ "GenSigSendType" SG_ 835 DwnLoadDynLtgPrmForFrntRIGrp11OffsetTime 1;
BA_ "GenSigSendType" SG_ 835 DwnLoadDynLtgPrmForFrntRIGrp11Timestamp 1;
// Frame: CemBodyExpoFr102
BA_ "GenMsgSendType" BO_ 836 1;
BA_ "GenMsgDelayTime" BO_ 836 30.000;
BA_ "GenSigSendType" SG_ 836 DwnLoadDynLtgPrmForFrntRIGrp12ContinueTime 1;
BA_ "GenSigSendType" SG_ 836 DwnLoadDynLtgPrmForFrntRIGrp12HighBrightness 1;
BA_ "GenSigSendType" SG_ 836 DwnLoadDynLtgPrmForFrntRIGrp12LowBrightness 1;
BA_ "GenSigSendType" SG_ 836 DwnLoadDynLtgPrmForFrntRIGrp12Mode1 1;
BA_ "GenSigSendType" SG_ 836 DwnLoadDynLtgPrmForFrntRIGrp12OffsetTime 1;
BA_ "GenSigSendType" SG_ 836 DwnLoadDynLtgPrmForFrntRIGrp12Timestamp 1;
// Frame: CemBodyExpoFr103
BA_ "GenMsgSendType" BO_ 837 1;
BA_ "GenMsgDelayTime" BO_ 837 30.000;
BA_ "GenSigSendType" SG_ 837 DwnLoadDynLtgPrmForFrntRIGrp13ContinueTime 1;
BA_ "GenSigSendType" SG_ 837 DwnLoadDynLtgPrmForFrntRIGrp13HighBrightness 1;
BA_ "GenSigSendType" SG_ 837 DwnLoadDynLtgPrmForFrntRIGrp13LowBrightness 1;
BA_ "GenSigSendType" SG_ 837 DwnLoadDynLtgPrmForFrntRIGrp13Mode1 1;
BA_ "GenSigSendType" SG_ 837 DwnLoadDynLtgPrmForFrntRIGrp13OffsetTime 1;
BA_ "GenSigSendType" SG_ 837 DwnLoadDynLtgPrmForFrntRIGrp13Timestamp 1;
// Frame: CemBodyExpoFr104
BA_ "GenMsgSendType" BO_ 838 1;
BA_ "GenMsgDelayTime" BO_ 838 30.000;
BA_ "GenSigSendType" SG_ 838 DwnLoadDynLtgPrmForFrntRIGrp14ContinueTime 1;
BA_ "GenSigSendType" SG_ 838 DwnLoadDynLtgPrmForFrntRIGrp14HighBrightness 1;
BA_ "GenSigSendType" SG_ 838 DwnLoadDynLtgPrmForFrntRIGrp14LowBrightness 1;
BA_ "GenSigSendType" SG_ 838 DwnLoadDynLtgPrmForFrntRIGrp14Mode1 1;
BA_ "GenSigSendType" SG_ 838 DwnLoadDynLtgPrmForFrntRIGrp14OffsetTime 1;
BA_ "GenSigSendType" SG_ 838 DwnLoadDynLtgPrmForFrntRIGrp14Timestamp 1;
// Frame: CemBodyExpoFr105
BA_ "GenMsgSendType" BO_ 839 1;
BA_ "GenMsgDelayTime" BO_ 839 30.000;
BA_ "GenSigSendType" SG_ 839 DwnLoadDynLtgPrmForFrntRIGrp15ContinueTime 1;
BA_ "GenSigSendType" SG_ 839 DwnLoadDynLtgPrmForFrntRIGrp15HighBrightness 1;
BA_ "GenSigSendType" SG_ 839 DwnLoadDynLtgPrmForFrntRIGrp15LowBrightness 1;
BA_ "GenSigSendType" SG_ 839 DwnLoadDynLtgPrmForFrntRIGrp15Mode1 1;
BA_ "GenSigSendType" SG_ 839 DwnLoadDynLtgPrmForFrntRIGrp15OffsetTime 1;
BA_ "GenSigSendType" SG_ 839 DwnLoadDynLtgPrmForFrntRIGrp15Timestamp 1;
// Frame: CemBodyExpoFr106
BA_ "GenMsgSendType" BO_ 840 1;
BA_ "GenMsgDelayTime" BO_ 840 30.000;
BA_ "GenSigSendType" SG_ 840 DwnLoadDynLtgPrmForFrntRIGrp16ContinueTime 1;
BA_ "GenSigSendType" SG_ 840 DwnLoadDynLtgPrmForFrntRIGrp16HighBrightness 1;
BA_ "GenSigSendType" SG_ 840 DwnLoadDynLtgPrmForFrntRIGrp16LowBrightness 1;
BA_ "GenSigSendType" SG_ 840 DwnLoadDynLtgPrmForFrntRIGrp16Mode1 1;
BA_ "GenSigSendType" SG_ 840 DwnLoadDynLtgPrmForFrntRIGrp16OffsetTime 1;
BA_ "GenSigSendType" SG_ 840 DwnLoadDynLtgPrmForFrntRIGrp16Timestamp 1;
// Frame: CemBodyExpoFr107
BA_ "GenMsgSendType" BO_ 841 1;
BA_ "GenMsgDelayTime" BO_ 841 30.000;
BA_ "GenSigSendType" SG_ 841 DwnLoadDynLtgPrmForFrntRIGrp17ContinueTime 1;
BA_ "GenSigSendType" SG_ 841 DwnLoadDynLtgPrmForFrntRIGrp17HighBrightness 1;
BA_ "GenSigSendType" SG_ 841 DwnLoadDynLtgPrmForFrntRIGrp17LowBrightness 1;
BA_ "GenSigSendType" SG_ 841 DwnLoadDynLtgPrmForFrntRIGrp17Mode1 1;
BA_ "GenSigSendType" SG_ 841 DwnLoadDynLtgPrmForFrntRIGrp17OffsetTime 1;
BA_ "GenSigSendType" SG_ 841 DwnLoadDynLtgPrmForFrntRIGrp17Timestamp 1;
// Frame: CemBodyExpoFr108
BA_ "GenMsgSendType" BO_ 842 1;
BA_ "GenMsgDelayTime" BO_ 842 30.000;
BA_ "GenSigSendType" SG_ 842 DwnLoadDynLtgPrmForFrntRIGrp18ContinueTime 1;
BA_ "GenSigSendType" SG_ 842 DwnLoadDynLtgPrmForFrntRIGrp18HighBrightness 1;
BA_ "GenSigSendType" SG_ 842 DwnLoadDynLtgPrmForFrntRIGrp18LowBrightness 1;
BA_ "GenSigSendType" SG_ 842 DwnLoadDynLtgPrmForFrntRIGrp18Mode1 1;
BA_ "GenSigSendType" SG_ 842 DwnLoadDynLtgPrmForFrntRIGrp18OffsetTime 1;
BA_ "GenSigSendType" SG_ 842 DwnLoadDynLtgPrmForFrntRIGrp18Timestamp 1;
// Frame: CemBodyExpoFr109
BA_ "GenMsgSendType" BO_ 843 1;
BA_ "GenMsgDelayTime" BO_ 843 30.000;
BA_ "GenSigSendType" SG_ 843 DwnLoadDynLtgPrmForFrntRIGrp19ContinueTime 1;
BA_ "GenSigSendType" SG_ 843 DwnLoadDynLtgPrmForFrntRIGrp19HighBrightness 1;
BA_ "GenSigSendType" SG_ 843 DwnLoadDynLtgPrmForFrntRIGrp19LowBrightness 1;
BA_ "GenSigSendType" SG_ 843 DwnLoadDynLtgPrmForFrntRIGrp19Mode1 1;
BA_ "GenSigSendType" SG_ 843 DwnLoadDynLtgPrmForFrntRIGrp19OffsetTime 1;
BA_ "GenSigSendType" SG_ 843 DwnLoadDynLtgPrmForFrntRIGrp19Timestamp 1;
// Frame: CemBodyExpoFr11
BA_ "GenMsgSendType" BO_ 297 1;
BA_ "GenMsgDelayTime" BO_ 297 30.000;
BA_ "GenSigSendType" SG_ 297 DwnLoadDynLitPrmForLedStopLampLe2ContTiPrm 1;
BA_ "SigGroup" SG_ 297 DwnLoadDynLitPrmForLedStopLampLe2ContTiPrm "DwnLoadDynLitPrmForLedStopLampLe2";
BA_ "GenSigSendType" SG_ 297 DwnLoadDynLitPrmForLedStopLampLe2LowBriPrm 1;
BA_ "SigGroup" SG_ 297 DwnLoadDynLitPrmForLedStopLampLe2LowBriPrm "DwnLoadDynLitPrmForLedStopLampLe2";
BA_ "GenSigSendType" SG_ 297 DwnLoadDynLitPrmForLedStopLampLe2ModePrm 1;
BA_ "SigGroup" SG_ 297 DwnLoadDynLitPrmForLedStopLampLe2ModePrm "DwnLoadDynLitPrmForLedStopLampLe2";
BA_ "GenSigSendType" SG_ 297 DwnLoadDynLitPrmForLedStopLampLe2OffsTiPrm 1;
BA_ "SigGroup" SG_ 297 DwnLoadDynLitPrmForLedStopLampLe2OffsTiPrm "DwnLoadDynLitPrmForLedStopLampLe2";
BA_ "GenSigSendType" SG_ 297 DwnLoadDynLitPrmForLedStopLampLe2Tistamp 1;
BA_ "SigGroup" SG_ 297 DwnLoadDynLitPrmForLedStopLampLe2Tistamp "DwnLoadDynLitPrmForLedStopLampLe2";
BA_ "GenSigSendType" SG_ 297 DwnLoadDynLitPrmForLedStopLampLe2UpprBriPrm 1;
BA_ "SigGroup" SG_ 297 DwnLoadDynLitPrmForLedStopLampLe2UpprBriPrm "DwnLoadDynLitPrmForLedStopLampLe2";
// Frame: CemBodyExpoFr110
BA_ "GenMsgSendType" BO_ 844 1;
BA_ "GenMsgDelayTime" BO_ 844 30.000;
BA_ "GenSigSendType" SG_ 844 DwnLoadDynLtgPrmForFrntRIGrp20ContinueTime 1;
BA_ "GenSigSendType" SG_ 844 DwnLoadDynLtgPrmForFrntRIGrp20HighBrightness 1;
BA_ "GenSigSendType" SG_ 844 DwnLoadDynLtgPrmForFrntRIGrp20LowBrightness 1;
BA_ "GenSigSendType" SG_ 844 DwnLoadDynLtgPrmForFrntRIGrp20Mode1 1;
BA_ "GenSigSendType" SG_ 844 DwnLoadDynLtgPrmForFrntRIGrp20OffsetTime 1;
BA_ "GenSigSendType" SG_ 844 DwnLoadDynLtgPrmForFrntRIGrp20Timestamp 1;
// Frame: CemBodyExpoFr111
BA_ "GenMsgSendType" BO_ 845 1;
BA_ "GenMsgDelayTime" BO_ 845 30.000;
BA_ "GenSigSendType" SG_ 845 DwnLoadDynLtgPrmForFrntRIGrp21ContinueTime 1;
BA_ "GenSigSendType" SG_ 845 DwnLoadDynLtgPrmForFrntRIGrp21HighBrightness 1;
BA_ "GenSigSendType" SG_ 845 DwnLoadDynLtgPrmForFrntRIGrp21LowBrightness 1;
BA_ "GenSigSendType" SG_ 845 DwnLoadDynLtgPrmForFrntRIGrp21Mode1 1;
BA_ "GenSigSendType" SG_ 845 DwnLoadDynLtgPrmForFrntRIGrp21OffsetTime 1;
BA_ "GenSigSendType" SG_ 845 DwnLoadDynLtgPrmForFrntRIGrp21Timestamp 1;
// Frame: CemBodyExpoFr112
BA_ "GenMsgSendType" BO_ 846 1;
BA_ "GenMsgDelayTime" BO_ 846 30.000;
BA_ "GenSigSendType" SG_ 846 DwnLoadDynLtgPrmForFrntRIGrp22ContinueTime 1;
BA_ "GenSigSendType" SG_ 846 DwnLoadDynLtgPrmForFrntRIGrp22HighBrightness 1;
BA_ "GenSigSendType" SG_ 846 DwnLoadDynLtgPrmForFrntRIGrp22LowBrightness 1;
BA_ "GenSigSendType" SG_ 846 DwnLoadDynLtgPrmForFrntRIGrp22Mode1 1;
BA_ "GenSigSendType" SG_ 846 DwnLoadDynLtgPrmForFrntRIGrp22OffsetTime 1;
BA_ "GenSigSendType" SG_ 846 DwnLoadDynLtgPrmForFrntRIGrp22Timestamp 1;
// Frame: CemBodyExpoFr113
BA_ "GenMsgSendType" BO_ 847 1;
BA_ "GenMsgDelayTime" BO_ 847 30.000;
BA_ "GenSigSendType" SG_ 847 DwnLoadDynLtgPrmForFrntRIGrp23ContinueTime 1;
BA_ "GenSigSendType" SG_ 847 DwnLoadDynLtgPrmForFrntRIGrp23HighBrightness 1;
BA_ "GenSigSendType" SG_ 847 DwnLoadDynLtgPrmForFrntRIGrp23LowBrightness 1;
BA_ "GenSigSendType" SG_ 847 DwnLoadDynLtgPrmForFrntRIGrp23Mode1 1;
BA_ "GenSigSendType" SG_ 847 DwnLoadDynLtgPrmForFrntRIGrp23OffsetTime 1;
BA_ "GenSigSendType" SG_ 847 DwnLoadDynLtgPrmForFrntRIGrp23Timestamp 1;
// Frame: CemBodyExpoFr114
BA_ "GenMsgSendType" BO_ 848 1;
BA_ "GenMsgDelayTime" BO_ 848 30.000;
BA_ "GenSigSendType" SG_ 848 DwnLoadDynLtgPrmForFrntRIGrp24ContinueTime 1;
BA_ "GenSigSendType" SG_ 848 DwnLoadDynLtgPrmForFrntRIGrp24HighBrightness 1;
BA_ "GenSigSendType" SG_ 848 DwnLoadDynLtgPrmForFrntRIGrp24LowBrightness 1;
BA_ "GenSigSendType" SG_ 848 DwnLoadDynLtgPrmForFrntRIGrp24Mode1 1;
BA_ "GenSigSendType" SG_ 848 DwnLoadDynLtgPrmForFrntRIGrp24OffsetTime 1;
BA_ "GenSigSendType" SG_ 848 DwnLoadDynLtgPrmForFrntRIGrp24Timestamp 1;
// Frame: CemBodyExpoFr115
BA_ "GenMsgSendType" BO_ 784 0;
BA_ "GenMsgCycleTime" BO_ 784 100.000;
BA_ "GenSigSendType" SG_ 784 ActvnOfADB 0;
BA_ "GenSigSendType" SG_ 784 ActvnOfLiForComity 0;
BA_ "GenSigSendType" SG_ 784 ActvnOfLiForSpkr 0;
BA_ "GenSigSendType" SG_ 784 ActvnOfLiForWait 0;
BA_ "GenSigSendType" SG_ 784 CabPressPodCalc 0;
BA_ "GenSigSendType" SG_ 784 DoorDrvrLatPawlSt 0;
BA_ "GenSigSendType" SG_ 784 DoorDrvrLatPosn 0;
BA_ "GenSigSendType" SG_ 784 DoorLeReLatPawlSt 0;
BA_ "GenSigSendType" SG_ 784 DoorLeReLatPosn 0;
BA_ "GenSigSendType" SG_ 784 DoorPassLatPawlSt 0;
BA_ "GenSigSendType" SG_ 784 DoorPassLatPosn 0;
BA_ "GenSigSendType" SG_ 784 DoorRiReLatPawlSt 0;
BA_ "GenSigSendType" SG_ 784 DoorRiReLatPosn 0;
BA_ "GenSigSendType" SG_ 784 LockgCenStsLockSt 0;
BA_ "GenSigSendType" SG_ 784 LockgCenStsTrigSrc 0;
BA_ "GenSigSendType" SG_ 784 LockgCenStsUpdEve 0;
BA_ "GenSigSendType" SG_ 784 VehMtnStChks 0;
BA_ "GenSigFuncType" SG_ 784 VehMtnStChks 15;
BA_ "GenSigDataID" SG_ 784 VehMtnStChks "0x36";
BA_ "GenSigSendType" SG_ 784 VehMtnStCntr 0;
BA_ "GenSigFuncType" SG_ 784 VehMtnStCntr 16;
BA_ "GenSigSendType" SG_ 784 VehMtnStVehMtnSt 0;
// Frame: CemBodyExpoFr116
BA_ "GenMsgSendType" BO_ 1152 0;
BA_ "GenMsgCycleTime" BO_ 1152 1000.000;
BA_ "GenSigSendType" SG_ 1152 TiAndDateIndcnDataValid 0;
BA_ "GenSigStartValue" SG_ 1152 TiAndDateIndcnDay 1;
BA_ "GenSigSendType" SG_ 1152 TiAndDateIndcnDay 0;
BA_ "GenSigSendType" SG_ 1152 TiAndDateIndcnHr1 0;
BA_ "GenSigSendType" SG_ 1152 TiAndDateIndcnMins1 0;
BA_ "GenSigStartValue" SG_ 1152 TiAndDateIndcnMth1 1;
BA_ "GenSigSendType" SG_ 1152 TiAndDateIndcnMth1 0;
BA_ "GenSigSendType" SG_ 1152 TiAndDateIndcnSec1 0;
BA_ "GenSigSendType" SG_ 1152 TiAndDateIndcnYr1 0;
// Frame: CemBodyExpoFr117
BA_ "GenMsgSendType" BO_ 361 0;
BA_ "GenMsgCycleTime" BO_ 361 60.000;
BA_ "GenSigSendType" SG_ 361 CarpetLiDownloadFinish 1;
BA_ "GenSigSendType" SG_ 361 CarpetLiDownloadReq 1;
BA_ "GenSigSendType" SG_ 361 CarpetLiDowSwt 1;
BA_ "GenSigSendType" SG_ 361 DoorDrvrAutoManReq 0;
BA_ "GenSigStartValue" SG_ 361 DoorOpenerDrvrReqChks 255;
BA_ "GenSigSendType" SG_ 361 DoorOpenerDrvrReqChks 0;
BA_ "GenSigFuncType" SG_ 361 DoorOpenerDrvrReqChks 15;
BA_ "GenSigDataID" SG_ 361 DoorOpenerDrvrReqChks "0x43B";
BA_ "GenSigSendType" SG_ 361 DoorOpenerDrvrReqCntr 0;
BA_ "GenSigFuncType" SG_ 361 DoorOpenerDrvrReqCntr 16;
BA_ "GenSigSendType" SG_ 361 DoorOpenerDrvrReqDoorOpenerReq 0;
BA_ "GenSigSendType" SG_ 361 DoorOpenerDrvrReqTrigSrc 0;
BA_ "GenSigStartValue" SG_ 361 DoorOpenerLeReReqChks 255;
BA_ "GenSigSendType" SG_ 361 DoorOpenerLeReReqChks 0;
BA_ "GenSigFuncType" SG_ 361 DoorOpenerLeReReqChks 15;
BA_ "GenSigDataID" SG_ 361 DoorOpenerLeReReqChks "0x43C";
BA_ "GenSigSendType" SG_ 361 DoorOpenerLeReReqCntr 0;
BA_ "GenSigFuncType" SG_ 361 DoorOpenerLeReReqCntr 16;
BA_ "GenSigSendType" SG_ 361 DoorOpenerLeReReqDoorOpenerReq 0;
BA_ "GenSigSendType" SG_ 361 DoorOpenerLeReReqTrigSrc 0;
BA_ "GenSigSendType" SG_ 361 OpenDrvrSwt 0;
BA_ "GenSigSendType" SG_ 361 OpenLeReSwt 0;
BA_ "GenSigSendType" SG_ 361 OpenPassSwt 0;
BA_ "GenSigSendType" SG_ 361 OpenRiReSwt 0;
BA_ "GenSigSendType" SG_ 361 PawlDrvrSwt 0;
BA_ "GenSigSendType" SG_ 361 PawlLeReSwt 0;
BA_ "GenSigSendType" SG_ 361 PawlPassSwt 0;
BA_ "GenSigSendType" SG_ 361 PawlRiReSwt 0;

VAL_ 82 AutWinWipgCmd 0 "WipgSpd2_WipgSpd0Rpm" 1 "WipgSpd2_WipgSpd40Rpm" 2 "WipgSpd2_WipgSpd43Rpm" 3 "WipgSpd2_WipgSpd46Rpm" 4 "WipgSpd2_WipgSpd50Rpm" 5 "WipgSpd2_WipgSpd54Rpm" 6 "WipgSpd2_WipgSpd57Rpm" 7 "WipgSpd2_WipgSpd60Rpm";
VAL_ 82 LiOprnMod 0 "LiOperMod_Night" 1 "LiOperMod_Day" 2 "LiOperMod_Twli" 3 "LiOperMod_Tnl";
VAL_ 82 SteerWhlSnsrQf 0 "GenQf1_UndefindDataAccur" 1 "GenQf1_TmpUndefdData" 2 "GenQf1_DataAccurNotWithinSpcn" 3 "GenQf1_AccurData";
VAL_ 768 ActvnOfRvsg 0 "OnOff1_Off" 1 "OnOff1_On";
VAL_ 768 BrkPedlrRatQf 0 "GenQf1_UndefindDataAccur" 1 "GenQf1_TmpUndefdData" 2 "GenQf1_DataAccurNotWithinSpcn" 3 "GenQf1_AccurData";
VAL_ 80 DoorPassSts 0 "DoorSts2_Ukwn" 1 "DoorSts2_Opend" 2 "DoorSts2_Clsd";
VAL_ 80 DoorRiReSts 0 "DoorSts2_Ukwn" 1 "DoorSts2_Opend" 2 "DoorSts2_Clsd";
VAL_ 80 VehSpdLgtQf 0 "GenQf1_UndefindDataAccur" 1 "GenQf1_TmpUndefdData" 2 "GenQf1_DataAccurNotWithinSpcn" 3 "GenQf1_AccurData";
VAL_ 512 ExtrLiRlyPwrDwn 0 "Boolean_FALSE" 1 "Boolean_TRUE";
VAL_ 512 VehBattUSysUQf 0 "GenQf1_UndefindDataAccur" 1 "GenQf1_TmpUndefdData" 2 "GenQf1_DataAccurNotWithinSpcn" 3 "GenQf1_AccurData";
VAL_ 544 ActnOfLedFrntCrossLamp 0 "OnOff1_Off" 1 "OnOff1_On";
VAL_ 544 ActnOfLedGrilleLamp 0 "OnOff1_Off" 1 "OnOff1_On";
VAL_ 544 ActnOfLedLeLogoLamp 0 "OnOff1_Off" 1 "OnOff1_On";
VAL_ 544 ActnOfLedRiLogoLamp 0 "OnOff1_Off" 1 "OnOff1_On";
VAL_ 544 TrSts 0 "DoorSts2_Ukwn" 1 "DoorSts2_Opend" 2 "DoorSts2_Clsd";
VAL_ 128 AmbTRawQly 0 "GenQf1_UndefindDataAccur" 1 "GenQf1_TmpUndefdData" 2 "GenQf1_DataAccurNotWithinSpcn" 3 "GenQf1_AccurData";
VAL_ 128 BrkPedlSnsrQf 0 "GenQf1_UndefindDataAccur" 1 "GenQf1_TmpUndefdData" 2 "GenQf1_DataAccurNotWithinSpcn" 3 "GenQf1_AccurData";
VAL_ 128 BrkPedlSnsrSt 0 "PsdNotPsd2_NoInfo1" 1 "PsdNotPsd2_NotPsd" 2 "PsdNotPsd2_Psd" 3 "PsdNotPsd2_NoInfo2";
VAL_ 128 TooManyCars 0 "NoYes1_No" 1 "NoYes1_Yes";
VAL_ 389 TrafficSignForADB1AdbDetdQly 0 "ClassnQly_Low" 1 "ClassnQly_Medium" 2 "ClassnQly_High";
VAL_ 389 TrafficSignForADB1AdbTrkInfo 0 "NotTracked" 1 "Tracking";
VAL_ 390 TrafficSignForADB2AdbDetdQly 0 "ClassnQly_Low" 1 "ClassnQly_Medium" 2 "ClassnQly_High";
VAL_ 390 TrafficSignForADB2AdbTrkInfo 0 "NotTracked" 1 "Tracking";
VAL_ 391 VehObjforAHBAdbClassn 0 "AdbClassn_NoVehicle" 1 "AdbClassn_Car" 2 "AdbClassn_Truck" 3 "AdbClassn_Bus" 4 "AdbClassn_BikeOrMotorBike" 5 "AdbClassn_Pedestrain" 6 "AdbClassn_Mixed" 7 "AdbClassn_Unknown";
VAL_ 391 VehObjforAHBAdbClassnQly 0 "ClassnQly_Low" 1 "ClassnQly_Medium" 2 "ClassnQly_High";
VAL_ 391 VehObjforAHBAdbDetdQly 0 "ClassnQly_Low" 1 "ClassnQly_Medium" 2 "ClassnQly_High";
VAL_ 391 VehObjforAHBAdbObjDir 0 "AdbObjDir_Idle" 1 "AdbObjDir_Oncoming" 2 "AdbObjDir_Preceding" 3 "AdbObjDir_Others";
VAL_ 391 VehObjforAHBAdbTrkInfo 0 "NotTracked" 1 "Tracking";
VAL_ 392 VehObjforADB1AdbClassn 0 "AdbClassn_NoVehicle" 1 "AdbClassn_Car" 2 "AdbClassn_Truck" 3 "AdbClassn_Bus" 4 "AdbClassn_BikeOrMotorBike" 5 "AdbClassn_Pedestrain" 6 "AdbClassn_Mixed" 7 "AdbClassn_Unknown";
VAL_ 392 VehObjforADB1AdbObjDir 0 "AdbObjDir_Idle" 1 "AdbObjDir_Oncoming" 2 "AdbObjDir_Preceding" 3 "AdbObjDir_Others";
VAL_ 392 VehObjforADB1AdbTrkInfo 0 "NotTracked" 1 "Tracking";
VAL_ 393 VehObjforADB2AdbClassn 0 "AdbClassn_NoVehicle" 1 "AdbClassn_Car" 2 "AdbClassn_Truck" 3 "AdbClassn_Bus" 4 "AdbClassn_BikeOrMotorBike" 5 "AdbClassn_Pedestrain" 6 "AdbClassn_Mixed" 7 "AdbClassn_Unknown";
VAL_ 393 VehObjforADB2AdbObjDir 0 "AdbObjDir_Idle" 1 "AdbObjDir_Oncoming" 2 "AdbObjDir_Preceding" 3 "AdbObjDir_Others";
VAL_ 393 VehObjforADB2AdbTrkInfo 0 "NotTracked" 1 "Tracking";
VAL_ 394 VehObjforADB3AdbClassn 0 "AdbClassn_NoVehicle" 1 "AdbClassn_Car" 2 "AdbClassn_Truck" 3 "AdbClassn_Bus" 4 "AdbClassn_BikeOrMotorBike" 5 "AdbClassn_Pedestrain" 6 "AdbClassn_Mixed" 7 "AdbClassn_Unknown";
VAL_ 394 VehObjforADB3AdbObjDir 0 "AdbObjDir_Idle" 1 "AdbObjDir_Oncoming" 2 "AdbObjDir_Preceding" 3 "AdbObjDir_Others";
VAL_ 394 VehObjforADB3AdbTrkInfo 0 "NotTracked" 1 "Tracking";
VAL_ 395 VehObjforADB4AdbClassn 0 "AdbClassn_NoVehicle" 1 "AdbClassn_Car" 2 "AdbClassn_Truck" 3 "AdbClassn_Bus" 4 "AdbClassn_BikeOrMotorBike" 5 "AdbClassn_Pedestrain" 6 "AdbClassn_Mixed" 7 "AdbClassn_Unknown";
VAL_ 395 VehObjforADB4AdbObjDir 0 "AdbObjDir_Idle" 1 "AdbObjDir_Oncoming" 2 "AdbObjDir_Preceding" 3 "AdbObjDir_Others";
VAL_ 395 VehObjforADB4AdbTrkInfo 0 "NotTracked" 1 "Tracking";
VAL_ 396 VehObjforADB5AdbClassn 0 "AdbClassn_NoVehicle" 1 "AdbClassn_Car" 2 "AdbClassn_Truck" 3 "AdbClassn_Bus" 4 "AdbClassn_BikeOrMotorBike" 5 "AdbClassn_Pedestrain" 6 "AdbClassn_Mixed" 7 "AdbClassn_Unknown";
VAL_ 396 VehObjforADB5AdbObjDir 0 "AdbObjDir_Idle" 1 "AdbObjDir_Oncoming" 2 "AdbObjDir_Preceding" 3 "AdbObjDir_Others";
VAL_ 396 VehObjforADB5AdbTrkInfo 0 "NotTracked" 1 "Tracking";
VAL_ 397 VehObjforADB6AdbClassn 0 "AdbClassn_NoVehicle" 1 "AdbClassn_Car" 2 "AdbClassn_Truck" 3 "AdbClassn_Bus" 4 "AdbClassn_BikeOrMotorBike" 5 "AdbClassn_Pedestrain" 6 "AdbClassn_Mixed" 7 "AdbClassn_Unknown";
VAL_ 397 VehObjforADB6AdbObjDir 0 "AdbObjDir_Idle" 1 "AdbObjDir_Oncoming" 2 "AdbObjDir_Preceding" 3 "AdbObjDir_Others";
VAL_ 397 VehObjforADB6AdbTrkInfo 0 "NotTracked" 1 "Tracking";
VAL_ 398 VehObjforADB7AdbClassn 0 "AdbClassn_NoVehicle" 1 "AdbClassn_Car" 2 "AdbClassn_Truck" 3 "AdbClassn_Bus" 4 "AdbClassn_BikeOrMotorBike" 5 "AdbClassn_Pedestrain" 6 "AdbClassn_Mixed" 7 "AdbClassn_Unknown";
VAL_ 398 VehObjforADB7AdbObjDir 0 "AdbObjDir_Idle" 1 "AdbObjDir_Oncoming" 2 "AdbObjDir_Preceding" 3 "AdbObjDir_Others";
VAL_ 398 VehObjforADB7AdbTrkInfo 0 "NotTracked" 1 "Tracking";
VAL_ 399 VehObjforADB8AdbClassn 0 "AdbClassn_NoVehicle" 1 "AdbClassn_Car" 2 "AdbClassn_Truck" 3 "AdbClassn_Bus" 4 "AdbClassn_BikeOrMotorBike" 5 "AdbClassn_Pedestrain" 6 "AdbClassn_Mixed" 7 "AdbClassn_Unknown";
VAL_ 399 VehObjforADB8AdbObjDir 0 "AdbObjDir_Idle" 1 "AdbObjDir_Oncoming" 2 "AdbObjDir_Preceding" 3 "AdbObjDir_Others";
VAL_ 399 VehObjforADB8AdbTrkInfo 0 "NotTracked" 1 "Tracking";
VAL_ 64 CameraStsforAHBC 0 "AdbCamSts_Idle" 1 "AdbCamSts_Normal" 2 "AdbCamSts_Blocking" 3 "AdbCamSts_Unknown";
VAL_ 64 RainLi 0 "OnOff1_Off" 1 "OnOff1_On";
VAL_ 64 VehModMngtGlbSafe1CarModSts1 0 "CarModSts1_CarModNorm" 1 "CarModSts1_CarModTrnsp" 2 "CarModSts1_CarModFcy" 3 "CarModSts1_CarModCrash" 5 "CarModSts1_CarModDyno";
VAL_ 64 VehModMngtGlbSafe1FltEgyCnsWdSts 0 "FltEgyCns1_NoFlt" 1 "FltEgyCns1_Flt";
VAL_ 64 VehModMngtGlbSafe1UsgModSts 0 "UsgModSts1_UsgModAbdnd" 1 "UsgModSts1_UsgModInActv" 2 "UsgModSts1_UsgModCnvinc" 11 "UsgModSts1_UsgModActv" 13 "UsgModSts1_UsgModDrvg";
VAL_ 64 WipgAutFrntMod 0 "WipgAutFrntMod_Off" 1 "WipgAutFrntMod_ImdtMod" 2 "WipgAutFrntMod_IntlMod" 3 "WipgAutFrntMod_ContnsMod";
VAL_ 400 SuspPosnVertAgGenQf 0 "GenQf1_UndefindDataAccur" 1 "GenQf1_TmpUndefdData" 2 "GenQf1_DataAccurNotWithinSpcn" 3 "GenQf1_AccurData";
VAL_ 400 SuspPosnVertLvlFrntQf 0 "GenQf1_UndefindDataAccur" 1 "GenQf1_TmpUndefdData" 2 "GenQf1_DataAccurNotWithinSpcn" 3 "GenQf1_AccurData";
VAL_ 400 SuspPosnVertLvlReQf 0 "GenQf1_UndefindDataAccur" 1 "GenQf1_TmpUndefdData" 2 "GenQf1_DataAccurNotWithinSpcn" 3 "GenQf1_AccurData";
VAL_ 28 CarpetLiActvReq 0 "ActvnAvl2_NoCmd" 1 "ActvnAvl2_Actvn" 2 "ActvnAvl2_Deactvn";
VAL_ 28 ExtrLiShowActvnReq 0 "OnOff1_Off" 1 "OnOff1_On";
VAL_ 28 ExtrLiShowFileTxReq 0 "OnOff1_Off" 1 "OnOff1_On";
VAL_ 288 DwnLoadDynLitPrmForLedStopLampRi2ModePrm 0 "Mode1_Off" 1 "Mode1_On" 2 "Mode1_GradualOn" 3 "Mode1_GradualOff" 4 "Mode1_ForwardWipingOn" 5 "Mode1_BackwardWipingOn" 6 "Mode1_OutwardWipingOn" 7 "Mode1_InwardWipingOn" 8 "Mode1_ForwardWipingOff" 9 "Mode1_BackwardWipingOff" 10 "Mode1_OutwardWipingOff" 11 "Mode1_InwardWipingOff" 12 "Mode1_ForwardScanning" 13 "Mode1_BackwardScanning" 14 "Mode1_BreathOn" 15 "Mode1_BreathOff" 16 "Mode1_Spare1" 17 "Mode1_Spare2";
VAL_ 289 DwnLoadDynLitPrmLedReFogLampRi2ModePrm 0 "Mode1_Off" 1 "Mode1_On" 2 "Mode1_GradualOn" 3 "Mode1_GradualOff" 4 "Mode1_ForwardWipingOn" 5 "Mode1_BackwardWipingOn" 6 "Mode1_OutwardWipingOn" 7 "Mode1_InwardWipingOn" 8 "Mode1_ForwardWipingOff" 9 "Mode1_BackwardWipingOff" 10 "Mode1_OutwardWipingOff" 11 "Mode1_InwardWipingOff" 12 "Mode1_ForwardScanning" 13 "Mode1_BackwardScanning" 14 "Mode1_BreathOn" 15 "Mode1_BreathOff" 16 "Mode1_Spare1" 17 "Mode1_Spare2";
VAL_ 290 DwnLoadDynLitPrmLedRePosnLampRi2ModePrm 0 "Mode1_Off" 1 "Mode1_On" 2 "Mode1_GradualOn" 3 "Mode1_GradualOff" 4 "Mode1_ForwardWipingOn" 5 "Mode1_BackwardWipingOn" 6 "Mode1_OutwardWipingOn" 7 "Mode1_InwardWipingOn" 8 "Mode1_ForwardWipingOff" 9 "Mode1_BackwardWipingOff" 10 "Mode1_OutwardWipingOff" 11 "Mode1_InwardWipingOff" 12 "Mode1_ForwardScanning" 13 "Mode1_BackwardScanning" 14 "Mode1_BreathOn" 15 "Mode1_BreathOff" 16 "Mode1_Spare1" 17 "Mode1_Spare2";
VAL_ 291 DwnLoadDynLitPrmLedReTurnIndcrRi2ModePrm 0 "Mode1_Off" 1 "Mode1_On" 2 "Mode1_GradualOn" 3 "Mode1_GradualOff" 4 "Mode1_ForwardWipingOn" 5 "Mode1_BackwardWipingOn" 6 "Mode1_OutwardWipingOn" 7 "Mode1_InwardWipingOn" 8 "Mode1_ForwardWipingOff" 9 "Mode1_BackwardWipingOff" 10 "Mode1_OutwardWipingOff" 11 "Mode1_InwardWipingOff" 12 "Mode1_ForwardScanning" 13 "Mode1_BackwardScanning" 14 "Mode1_BreathOn" 15 "Mode1_BreathOff" 16 "Mode1_Spare1" 17 "Mode1_Spare2";
VAL_ 292 DwnLoadDynLitPrmForLedMkrLampLe1ModePrm 0 "Mode1_Off" 1 "Mode1_On" 2 "Mode1_GradualOn" 3 "Mode1_GradualOff" 4 "Mode1_ForwardWipingOn" 5 "Mode1_BackwardWipingOn" 6 "Mode1_OutwardWipingOn" 7 "Mode1_InwardWipingOn" 8 "Mode1_ForwardWipingOff" 9 "Mode1_BackwardWipingOff" 10 "Mode1_OutwardWipingOff" 11 "Mode1_InwardWipingOff" 12 "Mode1_ForwardScanning" 13 "Mode1_BackwardScanning" 14 "Mode1_BreathOn" 15 "Mode1_BreathOff" 16 "Mode1_Spare1" 17 "Mode1_Spare2";
VAL_ 293 DwnLoadDynLtgPrmForLedLoBeamRiModePrm 0 "Mode1_Off" 1 "Mode1_On" 2 "Mode1_GradualOn" 3 "Mode1_GradualOff" 4 "Mode1_ForwardWipingOn" 5 "Mode1_BackwardWipingOn" 6 "Mode1_OutwardWipingOn" 7 "Mode1_InwardWipingOn" 8 "Mode1_ForwardWipingOff" 9 "Mode1_BackwardWipingOff" 10 "Mode1_OutwardWipingOff" 11 "Mode1_InwardWipingOff" 12 "Mode1_ForwardScanning" 13 "Mode1_BackwardScanning" 14 "Mode1_BreathOn" 15 "Mode1_BreathOff" 16 "Mode1_Spare1" 17 "Mode1_Spare2";
VAL_ 294 DwnLoadDynLitPrmForLedMkrLampLe2ModePrm 0 "Mode1_Off" 1 "Mode1_On" 2 "Mode1_GradualOn" 3 "Mode1_GradualOff" 4 "Mode1_ForwardWipingOn" 5 "Mode1_BackwardWipingOn" 6 "Mode1_OutwardWipingOn" 7 "Mode1_InwardWipingOn" 8 "Mode1_ForwardWipingOff" 9 "Mode1_BackwardWipingOff" 10 "Mode1_OutwardWipingOff" 11 "Mode1_InwardWipingOff" 12 "Mode1_ForwardScanning" 13 "Mode1_BackwardScanning" 14 "Mode1_BreathOn" 15 "Mode1_BreathOff" 16 "Mode1_Spare1" 17 "Mode1_Spare2";
VAL_ 295 DwnLoadDynLitPrmForLedMkrLampRi1ModePrm 0 "Mode1_Off" 1 "Mode1_On" 2 "Mode1_GradualOn" 3 "Mode1_GradualOff" 4 "Mode1_ForwardWipingOn" 5 "Mode1_BackwardWipingOn" 6 "Mode1_OutwardWipingOn" 7 "Mode1_InwardWipingOn" 8 "Mode1_ForwardWipingOff" 9 "Mode1_BackwardWipingOff" 10 "Mode1_OutwardWipingOff" 11 "Mode1_InwardWipingOff" 12 "Mode1_ForwardScanning" 13 "Mode1_BackwardScanning" 14 "Mode1_BreathOn" 15 "Mode1_BreathOff" 16 "Mode1_Spare1" 17 "Mode1_Spare2";
VAL_ 296 DwnLoadDynLitPrmForLedStopLampLe1ModePrm 0 "Mode1_Off" 1 "Mode1_On" 2 "Mode1_GradualOn" 3 "Mode1_GradualOff" 4 "Mode1_ForwardWipingOn" 5 "Mode1_BackwardWipingOn" 6 "Mode1_OutwardWipingOn" 7 "Mode1_InwardWipingOn" 8 "Mode1_ForwardWipingOff" 9 "Mode1_BackwardWipingOff" 10 "Mode1_OutwardWipingOff" 11 "Mode1_InwardWipingOff" 12 "Mode1_ForwardScanning" 13 "Mode1_BackwardScanning" 14 "Mode1_BreathOn" 15 "Mode1_BreathOff" 16 "Mode1_Spare1" 17 "Mode1_Spare2";
VAL_ 834 DwnLoadDynLtgPrmForFrntRIGrp10Mode1 0 "Mode4_Off" 1 "Mode4_On" 2 "Mode4_GradualOn" 3 "Mode4_GradualOff" 4 "Mode4_ForwardWipingOn" 5 "Mode4_BackwardWipingOn" 6 "Mode4_OutwardWipingOn" 7 "Mode4_InwardWipingOn" 8 "Mode4_ForwardWipingOff" 9 "Mode4_BackwardWipingOff" 10 "Mode4_OutwardWipingOff" 11 "Mode4_InwardWipingOff" 12 "Mode4_ForwardScanning" 13 "Mode4_BackwardScanning" 14 "Mode4_BreathOn" 15 "Mode4_BreathOff" 16 "Mode4_1stHalfONand2ndHalfOFF" 17 "Mode4_HalfOFFHalfON" 18 "Mode4_HalfDimmingONHalfOFF" 19 "Mode4_HalfDimmingONHalfON" 20 "Mode4_HalfOFFHalfDimmingON" 21 "Mode4_HalfONHalfDimmingON" 22 "Mode4_HalfDimmingOFFHalfOFF" 23 "Mode4_HalfDimmingOFFHalfON" 24 "Mode4_HalfOFFHalfDimmingOFF" 25 "Mode4_HalfONHalfDimmingOFF" 26 "Mode4_SingleOn1" 27 "Mode4_SingleOn2" 28 "Mode4_SingleOn3" 29 "Mode4_SingleOn4" 30 "Mode4_SingleOn5" 31 "Mode4_SingleOn6" 32 "Mode4_SingleOn7" 33 "Mode4_SingleOn8" 34 "Mode4_SingleOn9" 35 "Mode4_SingleOn10" 36 "Mode4_SingleOn11" 37 "Mode4_SingleOn12" 38 "Mode4_SingleOff1" 39 "Mode4_SingleOff2" 40 "Mode4_SingleOff3" 41 "Mode4_SingleOff4" 42 "Mode4_SingleOff5" 43 "Mode4_SingleOff6" 44 "Mode4_SingleOff7" 45 "Mode4_SingleOff8" 46 "Mode4_SingleOff9" 47 "Mode4_SingleOff10" 48 "Mode4_SingleOff11" 49 "Mode4_SingleOff12";
VAL_ 835 DwnLoadDynLtgPrmForFrntRIGrp11Mode1 0 "Mode4_Off" 1 "Mode4_On" 2 "Mode4_GradualOn" 3 "Mode4_GradualOff" 4 "Mode4_ForwardWipingOn" 5 "Mode4_BackwardWipingOn" 6 "Mode4_OutwardWipingOn" 7 "Mode4_InwardWipingOn" 8 "Mode4_ForwardWipingOff" 9 "Mode4_BackwardWipingOff" 10 "Mode4_OutwardWipingOff" 11 "Mode4_InwardWipingOff" 12 "Mode4_ForwardScanning" 13 "Mode4_BackwardScanning" 14 "Mode4_BreathOn" 15 "Mode4_BreathOff" 16 "Mode4_1stHalfONand2ndHalfOFF" 17 "Mode4_HalfOFFHalfON" 18 "Mode4_HalfDimmingONHalfOFF" 19 "Mode4_HalfDimmingONHalfON" 20 "Mode4_HalfOFFHalfDimmingON" 21 "Mode4_HalfONHalfDimmingON" 22 "Mode4_HalfDimmingOFFHalfOFF" 23 "Mode4_HalfDimmingOFFHalfON" 24 "Mode4_HalfOFFHalfDimmingOFF" 25 "Mode4_HalfONHalfDimmingOFF" 26 "Mode4_SingleOn1" 27 "Mode4_SingleOn2" 28 "Mode4_SingleOn3" 29 "Mode4_SingleOn4" 30 "Mode4_SingleOn5" 31 "Mode4_SingleOn6" 32 "Mode4_SingleOn7" 33 "Mode4_SingleOn8" 34 "Mode4_SingleOn9" 35 "Mode4_SingleOn10" 36 "Mode4_SingleOn11" 37 "Mode4_SingleOn12" 38 "Mode4_SingleOff1" 39 "Mode4_SingleOff2" 40 "Mode4_SingleOff3" 41 "Mode4_SingleOff4" 42 "Mode4_SingleOff5" 43 "Mode4_SingleOff6" 44 "Mode4_SingleOff7" 45 "Mode4_SingleOff8" 46 "Mode4_SingleOff9" 47 "Mode4_SingleOff10" 48 "Mode4_SingleOff11" 49 "Mode4_SingleOff12";
VAL_ 836 DwnLoadDynLtgPrmForFrntRIGrp12Mode1 0 "Mode4_Off" 1 "Mode4_On" 2 "Mode4_GradualOn" 3 "Mode4_GradualOff" 4 "Mode4_ForwardWipingOn" 5 "Mode4_BackwardWipingOn" 6 "Mode4_OutwardWipingOn" 7 "Mode4_InwardWipingOn" 8 "Mode4_ForwardWipingOff" 9 "Mode4_BackwardWipingOff" 10 "Mode4_OutwardWipingOff" 11 "Mode4_InwardWipingOff" 12 "Mode4_ForwardScanning" 13 "Mode4_BackwardScanning" 14 "Mode4_BreathOn" 15 "Mode4_BreathOff" 16 "Mode4_1stHalfONand2ndHalfOFF" 17 "Mode4_HalfOFFHalfON" 18 "Mode4_HalfDimmingONHalfOFF" 19 "Mode4_HalfDimmingONHalfON" 20 "Mode4_HalfOFFHalfDimmingON" 21 "Mode4_HalfONHalfDimmingON" 22 "Mode4_HalfDimmingOFFHalfOFF" 23 "Mode4_HalfDimmingOFFHalfON" 24 "Mode4_HalfOFFHalfDimmingOFF" 25 "Mode4_HalfONHalfDimmingOFF" 26 "Mode4_SingleOn1" 27 "Mode4_SingleOn2" 28 "Mode4_SingleOn3" 29 "Mode4_SingleOn4" 30 "Mode4_SingleOn5" 31 "Mode4_SingleOn6" 32 "Mode4_SingleOn7" 33 "Mode4_SingleOn8" 34 "Mode4_SingleOn9" 35 "Mode4_SingleOn10" 36 "Mode4_SingleOn11" 37 "Mode4_SingleOn12" 38 "Mode4_SingleOff1" 39 "Mode4_SingleOff2" 40 "Mode4_SingleOff3" 41 "Mode4_SingleOff4" 42 "Mode4_SingleOff5" 43 "Mode4_SingleOff6" 44 "Mode4_SingleOff7" 45 "Mode4_SingleOff8" 46 "Mode4_SingleOff9" 47 "Mode4_SingleOff10" 48 "Mode4_SingleOff11" 49 "Mode4_SingleOff12";
VAL_ 837 DwnLoadDynLtgPrmForFrntRIGrp13Mode1 0 "Mode4_Off" 1 "Mode4_On" 2 "Mode4_GradualOn" 3 "Mode4_GradualOff" 4 "Mode4_ForwardWipingOn" 5 "Mode4_BackwardWipingOn" 6 "Mode4_OutwardWipingOn" 7 "Mode4_InwardWipingOn" 8 "Mode4_ForwardWipingOff" 9 "Mode4_BackwardWipingOff" 10 "Mode4_OutwardWipingOff" 11 "Mode4_InwardWipingOff" 12 "Mode4_ForwardScanning" 13 "Mode4_BackwardScanning" 14 "Mode4_BreathOn" 15 "Mode4_BreathOff" 16 "Mode4_1stHalfONand2ndHalfOFF" 17 "Mode4_HalfOFFHalfON" 18 "Mode4_HalfDimmingONHalfOFF" 19 "Mode4_HalfDimmingONHalfON" 20 "Mode4_HalfOFFHalfDimmingON" 21 "Mode4_HalfONHalfDimmingON" 22 "Mode4_HalfDimmingOFFHalfOFF" 23 "Mode4_HalfDimmingOFFHalfON" 24 "Mode4_HalfOFFHalfDimmingOFF" 25 "Mode4_HalfONHalfDimmingOFF" 26 "Mode4_SingleOn1" 27 "Mode4_SingleOn2" 28 "Mode4_SingleOn3" 29 "Mode4_SingleOn4" 30 "Mode4_SingleOn5" 31 "Mode4_SingleOn6" 32 "Mode4_SingleOn7" 33 "Mode4_SingleOn8" 34 "Mode4_SingleOn9" 35 "Mode4_SingleOn10" 36 "Mode4_SingleOn11" 37 "Mode4_SingleOn12" 38 "Mode4_SingleOff1" 39 "Mode4_SingleOff2" 40 "Mode4_SingleOff3" 41 "Mode4_SingleOff4" 42 "Mode4_SingleOff5" 43 "Mode4_SingleOff6" 44 "Mode4_SingleOff7" 45 "Mode4_SingleOff8" 46 "Mode4_SingleOff9" 47 "Mode4_SingleOff10" 48 "Mode4_SingleOff11" 49 "Mode4_SingleOff12";
VAL_ 838 DwnLoadDynLtgPrmForFrntRIGrp14Mode1 0 "Mode4_Off" 1 "Mode4_On" 2 "Mode4_GradualOn" 3 "Mode4_GradualOff" 4 "Mode4_ForwardWipingOn" 5 "Mode4_BackwardWipingOn" 6 "Mode4_OutwardWipingOn" 7 "Mode4_InwardWipingOn" 8 "Mode4_ForwardWipingOff" 9 "Mode4_BackwardWipingOff" 10 "Mode4_OutwardWipingOff" 11 "Mode4_InwardWipingOff" 12 "Mode4_ForwardScanning" 13 "Mode4_BackwardScanning" 14 "Mode4_BreathOn" 15 "Mode4_BreathOff" 16 "Mode4_1stHalfONand2ndHalfOFF" 17 "Mode4_HalfOFFHalfON" 18 "Mode4_HalfDimmingONHalfOFF" 19 "Mode4_HalfDimmingONHalfON" 20 "Mode4_HalfOFFHalfDimmingON" 21 "Mode4_HalfONHalfDimmingON" 22 "Mode4_HalfDimmingOFFHalfOFF" 23 "Mode4_HalfDimmingOFFHalfON" 24 "Mode4_HalfOFFHalfDimmingOFF" 25 "Mode4_HalfONHalfDimmingOFF" 26 "Mode4_SingleOn1" 27 "Mode4_SingleOn2" 28 "Mode4_SingleOn3" 29 "Mode4_SingleOn4" 30 "Mode4_SingleOn5" 31 "Mode4_SingleOn6" 32 "Mode4_SingleOn7" 33 "Mode4_SingleOn8" 34 "Mode4_SingleOn9" 35 "Mode4_SingleOn10" 36 "Mode4_SingleOn11" 37 "Mode4_SingleOn12" 38 "Mode4_SingleOff1" 39 "Mode4_SingleOff2" 40 "Mode4_SingleOff3" 41 "Mode4_SingleOff4" 42 "Mode4_SingleOff5" 43 "Mode4_SingleOff6" 44 "Mode4_SingleOff7" 45 "Mode4_SingleOff8" 46 "Mode4_SingleOff9" 47 "Mode4_SingleOff10" 48 "Mode4_SingleOff11" 49 "Mode4_SingleOff12";
VAL_ 839 DwnLoadDynLtgPrmForFrntRIGrp15Mode1 0 "Mode4_Off" 1 "Mode4_On" 2 "Mode4_GradualOn" 3 "Mode4_GradualOff" 4 "Mode4_ForwardWipingOn" 5 "Mode4_BackwardWipingOn" 6 "Mode4_OutwardWipingOn" 7 "Mode4_InwardWipingOn" 8 "Mode4_ForwardWipingOff" 9 "Mode4_BackwardWipingOff" 10 "Mode4_OutwardWipingOff" 11 "Mode4_InwardWipingOff" 12 "Mode4_ForwardScanning" 13 "Mode4_BackwardScanning" 14 "Mode4_BreathOn" 15 "Mode4_BreathOff" 16 "Mode4_1stHalfONand2ndHalfOFF" 17 "Mode4_HalfOFFHalfON" 18 "Mode4_HalfDimmingONHalfOFF" 19 "Mode4_HalfDimmingONHalfON" 20 "Mode4_HalfOFFHalfDimmingON" 21 "Mode4_HalfONHalfDimmingON" 22 "Mode4_HalfDimmingOFFHalfOFF" 23 "Mode4_HalfDimmingOFFHalfON" 24 "Mode4_HalfOFFHalfDimmingOFF" 25 "Mode4_HalfONHalfDimmingOFF" 26 "Mode4_SingleOn1" 27 "Mode4_SingleOn2" 28 "Mode4_SingleOn3" 29 "Mode4_SingleOn4" 30 "Mode4_SingleOn5" 31 "Mode4_SingleOn6" 32 "Mode4_SingleOn7" 33 "Mode4_SingleOn8" 34 "Mode4_SingleOn9" 35 "Mode4_SingleOn10" 36 "Mode4_SingleOn11" 37 "Mode4_SingleOn12" 38 "Mode4_SingleOff1" 39 "Mode4_SingleOff2" 40 "Mode4_SingleOff3" 41 "Mode4_SingleOff4" 42 "Mode4_SingleOff5" 43 "Mode4_SingleOff6" 44 "Mode4_SingleOff7" 45 "Mode4_SingleOff8" 46 "Mode4_SingleOff9" 47 "Mode4_SingleOff10" 48 "Mode4_SingleOff11" 49 "Mode4_SingleOff12";
VAL_ 840 DwnLoadDynLtgPrmForFrntRIGrp16Mode1 0 "Mode4_Off" 1 "Mode4_On" 2 "Mode4_GradualOn" 3 "Mode4_GradualOff" 4 "Mode4_ForwardWipingOn" 5 "Mode4_BackwardWipingOn" 6 "Mode4_OutwardWipingOn" 7 "Mode4_InwardWipingOn" 8 "Mode4_ForwardWipingOff" 9 "Mode4_BackwardWipingOff" 10 "Mode4_OutwardWipingOff" 11 "Mode4_InwardWipingOff" 12 "Mode4_ForwardScanning" 13 "Mode4_BackwardScanning" 14 "Mode4_BreathOn" 15 "Mode4_BreathOff" 16 "Mode4_1stHalfONand2ndHalfOFF" 17 "Mode4_HalfOFFHalfON" 18 "Mode4_HalfDimmingONHalfOFF" 19 "Mode4_HalfDimmingONHalfON" 20 "Mode4_HalfOFFHalfDimmingON" 21 "Mode4_HalfONHalfDimmingON" 22 "Mode4_HalfDimmingOFFHalfOFF" 23 "Mode4_HalfDimmingOFFHalfON" 24 "Mode4_HalfOFFHalfDimmingOFF" 25 "Mode4_HalfONHalfDimmingOFF" 26 "Mode4_SingleOn1" 27 "Mode4_SingleOn2" 28 "Mode4_SingleOn3" 29 "Mode4_SingleOn4" 30 "Mode4_SingleOn5" 31 "Mode4_SingleOn6" 32 "Mode4_SingleOn7" 33 "Mode4_SingleOn8" 34 "Mode4_SingleOn9" 35 "Mode4_SingleOn10" 36 "Mode4_SingleOn11" 37 "Mode4_SingleOn12" 38 "Mode4_SingleOff1" 39 "Mode4_SingleOff2" 40 "Mode4_SingleOff3" 41 "Mode4_SingleOff4" 42 "Mode4_SingleOff5" 43 "Mode4_SingleOff6" 44 "Mode4_SingleOff7" 45 "Mode4_SingleOff8" 46 "Mode4_SingleOff9" 47 "Mode4_SingleOff10" 48 "Mode4_SingleOff11" 49 "Mode4_SingleOff12";
VAL_ 841 DwnLoadDynLtgPrmForFrntRIGrp17Mode1 0 "Mode4_Off" 1 "Mode4_On" 2 "Mode4_GradualOn" 3 "Mode4_GradualOff" 4 "Mode4_ForwardWipingOn" 5 "Mode4_BackwardWipingOn" 6 "Mode4_OutwardWipingOn" 7 "Mode4_InwardWipingOn" 8 "Mode4_ForwardWipingOff" 9 "Mode4_BackwardWipingOff" 10 "Mode4_OutwardWipingOff" 11 "Mode4_InwardWipingOff" 12 "Mode4_ForwardScanning" 13 "Mode4_BackwardScanning" 14 "Mode4_BreathOn" 15 "Mode4_BreathOff" 16 "Mode4_1stHalfONand2ndHalfOFF" 17 "Mode4_HalfOFFHalfON" 18 "Mode4_HalfDimmingONHalfOFF" 19 "Mode4_HalfDimmingONHalfON" 20 "Mode4_HalfOFFHalfDimmingON" 21 "Mode4_HalfONHalfDimmingON" 22 "Mode4_HalfDimmingOFFHalfOFF" 23 "Mode4_HalfDimmingOFFHalfON" 24 "Mode4_HalfOFFHalfDimmingOFF" 25 "Mode4_HalfONHalfDimmingOFF" 26 "Mode4_SingleOn1" 27 "Mode4_SingleOn2" 28 "Mode4_SingleOn3" 29 "Mode4_SingleOn4" 30 "Mode4_SingleOn5" 31 "Mode4_SingleOn6" 32 "Mode4_SingleOn7" 33 "Mode4_SingleOn8" 34 "Mode4_SingleOn9" 35 "Mode4_SingleOn10" 36 "Mode4_SingleOn11" 37 "Mode4_SingleOn12" 38 "Mode4_SingleOff1" 39 "Mode4_SingleOff2" 40 "Mode4_SingleOff3" 41 "Mode4_SingleOff4" 42 "Mode4_SingleOff5" 43 "Mode4_SingleOff6" 44 "Mode4_SingleOff7" 45 "Mode4_SingleOff8" 46 "Mode4_SingleOff9" 47 "Mode4_SingleOff10" 48 "Mode4_SingleOff11" 49 "Mode4_SingleOff12";
VAL_ 842 DwnLoadDynLtgPrmForFrntRIGrp18Mode1 0 "Mode4_Off" 1 "Mode4_On" 2 "Mode4_GradualOn" 3 "Mode4_GradualOff" 4 "Mode4_ForwardWipingOn" 5 "Mode4_BackwardWipingOn" 6 "Mode4_OutwardWipingOn" 7 "Mode4_InwardWipingOn" 8 "Mode4_ForwardWipingOff" 9 "Mode4_BackwardWipingOff" 10 "Mode4_OutwardWipingOff" 11 "Mode4_InwardWipingOff" 12 "Mode4_ForwardScanning" 13 "Mode4_BackwardScanning" 14 "Mode4_BreathOn" 15 "Mode4_BreathOff" 16 "Mode4_1stHalfONand2ndHalfOFF" 17 "Mode4_HalfOFFHalfON" 18 "Mode4_HalfDimmingONHalfOFF" 19 "Mode4_HalfDimmingONHalfON" 20 "Mode4_HalfOFFHalfDimmingON" 21 "Mode4_HalfONHalfDimmingON" 22 "Mode4_HalfDimmingOFFHalfOFF" 23 "Mode4_HalfDimmingOFFHalfON" 24 "Mode4_HalfOFFHalfDimmingOFF" 25 "Mode4_HalfONHalfDimmingOFF" 26 "Mode4_SingleOn1" 27 "Mode4_SingleOn2" 28 "Mode4_SingleOn3" 29 "Mode4_SingleOn4" 30 "Mode4_SingleOn5" 31 "Mode4_SingleOn6" 32 "Mode4_SingleOn7" 33 "Mode4_SingleOn8" 34 "Mode4_SingleOn9" 35 "Mode4_SingleOn10" 36 "Mode4_SingleOn11" 37 "Mode4_SingleOn12" 38 "Mode4_SingleOff1" 39 "Mode4_SingleOff2" 40 "Mode4_SingleOff3" 41 "Mode4_SingleOff4" 42 "Mode4_SingleOff5" 43 "Mode4_SingleOff6" 44 "Mode4_SingleOff7" 45 "Mode4_SingleOff8" 46 "Mode4_SingleOff9" 47 "Mode4_SingleOff10" 48 "Mode4_SingleOff11" 49 "Mode4_SingleOff12";
VAL_ 843 DwnLoadDynLtgPrmForFrntRIGrp19Mode1 0 "Mode4_Off" 1 "Mode4_On" 2 "Mode4_GradualOn" 3 "Mode4_GradualOff" 4 "Mode4_ForwardWipingOn" 5 "Mode4_BackwardWipingOn" 6 "Mode4_OutwardWipingOn" 7 "Mode4_InwardWipingOn" 8 "Mode4_ForwardWipingOff" 9 "Mode4_BackwardWipingOff" 10 "Mode4_OutwardWipingOff" 11 "Mode4_InwardWipingOff" 12 "Mode4_ForwardScanning" 13 "Mode4_BackwardScanning" 14 "Mode4_BreathOn" 15 "Mode4_BreathOff" 16 "Mode4_1stHalfONand2ndHalfOFF" 17 "Mode4_HalfOFFHalfON" 18 "Mode4_HalfDimmingONHalfOFF" 19 "Mode4_HalfDimmingONHalfON" 20 "Mode4_HalfOFFHalfDimmingON" 21 "Mode4_HalfONHalfDimmingON" 22 "Mode4_HalfDimmingOFFHalfOFF" 23 "Mode4_HalfDimmingOFFHalfON" 24 "Mode4_HalfOFFHalfDimmingOFF" 25 "Mode4_HalfONHalfDimmingOFF" 26 "Mode4_SingleOn1" 27 "Mode4_SingleOn2" 28 "Mode4_SingleOn3" 29 "Mode4_SingleOn4" 30 "Mode4_SingleOn5" 31 "Mode4_SingleOn6" 32 "Mode4_SingleOn7" 33 "Mode4_SingleOn8" 34 "Mode4_SingleOn9" 35 "Mode4_SingleOn10" 36 "Mode4_SingleOn11" 37 "Mode4_SingleOn12" 38 "Mode4_SingleOff1" 39 "Mode4_SingleOff2" 40 "Mode4_SingleOff3" 41 "Mode4_SingleOff4" 42 "Mode4_SingleOff5" 43 "Mode4_SingleOff6" 44 "Mode4_SingleOff7" 45 "Mode4_SingleOff8" 46 "Mode4_SingleOff9" 47 "Mode4_SingleOff10" 48 "Mode4_SingleOff11" 49 "Mode4_SingleOff12";
VAL_ 297 DwnLoadDynLitPrmForLedStopLampLe2ModePrm 0 "Mode1_Off" 1 "Mode1_On" 2 "Mode1_GradualOn" 3 "Mode1_GradualOff" 4 "Mode1_ForwardWipingOn" 5 "Mode1_BackwardWipingOn" 6 "Mode1_OutwardWipingOn" 7 "Mode1_InwardWipingOn" 8 "Mode1_ForwardWipingOff" 9 "Mode1_BackwardWipingOff" 10 "Mode1_OutwardWipingOff" 11 "Mode1_InwardWipingOff" 12 "Mode1_ForwardScanning" 13 "Mode1_BackwardScanning" 14 "Mode1_BreathOn" 15 "Mode1_BreathOff" 16 "Mode1_Spare1" 17 "Mode1_Spare2";
VAL_ 844 DwnLoadDynLtgPrmForFrntRIGrp20Mode1 0 "Mode4_Off" 1 "Mode4_On" 2 "Mode4_GradualOn" 3 "Mode4_GradualOff" 4 "Mode4_ForwardWipingOn" 5 "Mode4_BackwardWipingOn" 6 "Mode4_OutwardWipingOn" 7 "Mode4_InwardWipingOn" 8 "Mode4_ForwardWipingOff" 9 "Mode4_BackwardWipingOff" 10 "Mode4_OutwardWipingOff" 11 "Mode4_InwardWipingOff" 12 "Mode4_ForwardScanning" 13 "Mode4_BackwardScanning" 14 "Mode4_BreathOn" 15 "Mode4_BreathOff" 16 "Mode4_1stHalfONand2ndHalfOFF" 17 "Mode4_HalfOFFHalfON" 18 "Mode4_HalfDimmingONHalfOFF" 19 "Mode4_HalfDimmingONHalfON" 20 "Mode4_HalfOFFHalfDimmingON" 21 "Mode4_HalfONHalfDimmingON" 22 "Mode4_HalfDimmingOFFHalfOFF" 23 "Mode4_HalfDimmingOFFHalfON" 24 "Mode4_HalfOFFHalfDimmingOFF" 25 "Mode4_HalfONHalfDimmingOFF" 26 "Mode4_SingleOn1" 27 "Mode4_SingleOn2" 28 "Mode4_SingleOn3" 29 "Mode4_SingleOn4" 30 "Mode4_SingleOn5" 31 "Mode4_SingleOn6" 32 "Mode4_SingleOn7" 33 "Mode4_SingleOn8" 34 "Mode4_SingleOn9" 35 "Mode4_SingleOn10" 36 "Mode4_SingleOn11" 37 "Mode4_SingleOn12" 38 "Mode4_SingleOff1" 39 "Mode4_SingleOff2" 40 "Mode4_SingleOff3" 41 "Mode4_SingleOff4" 42 "Mode4_SingleOff5" 43 "Mode4_SingleOff6" 44 "Mode4_SingleOff7" 45 "Mode4_SingleOff8" 46 "Mode4_SingleOff9" 47 "Mode4_SingleOff10" 48 "Mode4_SingleOff11" 49 "Mode4_SingleOff12";
VAL_ 845 DwnLoadDynLtgPrmForFrntRIGrp21Mode1 0 "Mode4_Off" 1 "Mode4_On" 2 "Mode4_GradualOn" 3 "Mode4_GradualOff" 4 "Mode4_ForwardWipingOn" 5 "Mode4_BackwardWipingOn" 6 "Mode4_OutwardWipingOn" 7 "Mode4_InwardWipingOn" 8 "Mode4_ForwardWipingOff" 9 "Mode4_BackwardWipingOff" 10 "Mode4_OutwardWipingOff" 11 "Mode4_InwardWipingOff" 12 "Mode4_ForwardScanning" 13 "Mode4_BackwardScanning" 14 "Mode4_BreathOn" 15 "Mode4_BreathOff" 16 "Mode4_1stHalfONand2ndHalfOFF" 17 "Mode4_HalfOFFHalfON" 18 "Mode4_HalfDimmingONHalfOFF" 19 "Mode4_HalfDimmingONHalfON" 20 "Mode4_HalfOFFHalfDimmingON" 21 "Mode4_HalfONHalfDimmingON" 22 "Mode4_HalfDimmingOFFHalfOFF" 23 "Mode4_HalfDimmingOFFHalfON" 24 "Mode4_HalfOFFHalfDimmingOFF" 25 "Mode4_HalfONHalfDimmingOFF" 26 "Mode4_SingleOn1" 27 "Mode4_SingleOn2" 28 "Mode4_SingleOn3" 29 "Mode4_SingleOn4" 30 "Mode4_SingleOn5" 31 "Mode4_SingleOn6" 32 "Mode4_SingleOn7" 33 "Mode4_SingleOn8" 34 "Mode4_SingleOn9" 35 "Mode4_SingleOn10" 36 "Mode4_SingleOn11" 37 "Mode4_SingleOn12" 38 "Mode4_SingleOff1" 39 "Mode4_SingleOff2" 40 "Mode4_SingleOff3" 41 "Mode4_SingleOff4" 42 "Mode4_SingleOff5" 43 "Mode4_SingleOff6" 44 "Mode4_SingleOff7" 45 "Mode4_SingleOff8" 46 "Mode4_SingleOff9" 47 "Mode4_SingleOff10" 48 "Mode4_SingleOff11" 49 "Mode4_SingleOff12";
VAL_ 846 DwnLoadDynLtgPrmForFrntRIGrp22Mode1 0 "Mode4_Off" 1 "Mode4_On" 2 "Mode4_GradualOn" 3 "Mode4_GradualOff" 4 "Mode4_ForwardWipingOn" 5 "Mode4_BackwardWipingOn" 6 "Mode4_OutwardWipingOn" 7 "Mode4_InwardWipingOn" 8 "Mode4_ForwardWipingOff" 9 "Mode4_BackwardWipingOff" 10 "Mode4_OutwardWipingOff" 11 "Mode4_InwardWipingOff" 12 "Mode4_ForwardScanning" 13 "Mode4_BackwardScanning" 14 "Mode4_BreathOn" 15 "Mode4_BreathOff" 16 "Mode4_1stHalfONand2ndHalfOFF" 17 "Mode4_HalfOFFHalfON" 18 "Mode4_HalfDimmingONHalfOFF" 19 "Mode4_HalfDimmingONHalfON" 20 "Mode4_HalfOFFHalfDimmingON" 21 "Mode4_HalfONHalfDimmingON" 22 "Mode4_HalfDimmingOFFHalfOFF" 23 "Mode4_HalfDimmingOFFHalfON" 24 "Mode4_HalfOFFHalfDimmingOFF" 25 "Mode4_HalfONHalfDimmingOFF" 26 "Mode4_SingleOn1" 27 "Mode4_SingleOn2" 28 "Mode4_SingleOn3" 29 "Mode4_SingleOn4" 30 "Mode4_SingleOn5" 31 "Mode4_SingleOn6" 32 "Mode4_SingleOn7" 33 "Mode4_SingleOn8" 34 "Mode4_SingleOn9" 35 "Mode4_SingleOn10" 36 "Mode4_SingleOn11" 37 "Mode4_SingleOn12" 38 "Mode4_SingleOff1" 39 "Mode4_SingleOff2" 40 "Mode4_SingleOff3" 41 "Mode4_SingleOff4" 42 "Mode4_SingleOff5" 43 "Mode4_SingleOff6" 44 "Mode4_SingleOff7" 45 "Mode4_SingleOff8" 46 "Mode4_SingleOff9" 47 "Mode4_SingleOff10" 48 "Mode4_SingleOff11" 49 "Mode4_SingleOff12";
VAL_ 847 DwnLoadDynLtgPrmForFrntRIGrp23Mode1 0 "Mode4_Off" 1 "Mode4_On" 2 "Mode4_GradualOn" 3 "Mode4_GradualOff" 4 "Mode4_ForwardWipingOn" 5 "Mode4_BackwardWipingOn" 6 "Mode4_OutwardWipingOn" 7 "Mode4_InwardWipingOn" 8 "Mode4_ForwardWipingOff" 9 "Mode4_BackwardWipingOff" 10 "Mode4_OutwardWipingOff" 11 "Mode4_InwardWipingOff" 12 "Mode4_ForwardScanning" 13 "Mode4_BackwardScanning" 14 "Mode4_BreathOn" 15 "Mode4_BreathOff" 16 "Mode4_1stHalfONand2ndHalfOFF" 17 "Mode4_HalfOFFHalfON" 18 "Mode4_HalfDimmingONHalfOFF" 19 "Mode4_HalfDimmingONHalfON" 20 "Mode4_HalfOFFHalfDimmingON" 21 "Mode4_HalfONHalfDimmingON" 22 "Mode4_HalfDimmingOFFHalfOFF" 23 "Mode4_HalfDimmingOFFHalfON" 24 "Mode4_HalfOFFHalfDimmingOFF" 25 "Mode4_HalfONHalfDimmingOFF" 26 "Mode4_SingleOn1" 27 "Mode4_SingleOn2" 28 "Mode4_SingleOn3" 29 "Mode4_SingleOn4" 30 "Mode4_SingleOn5" 31 "Mode4_SingleOn6" 32 "Mode4_SingleOn7" 33 "Mode4_SingleOn8" 34 "Mode4_SingleOn9" 35 "Mode4_SingleOn10" 36 "Mode4_SingleOn11" 37 "Mode4_SingleOn12" 38 "Mode4_SingleOff1" 39 "Mode4_SingleOff2" 40 "Mode4_SingleOff3" 41 "Mode4_SingleOff4" 42 "Mode4_SingleOff5" 43 "Mode4_SingleOff6" 44 "Mode4_SingleOff7" 45 "Mode4_SingleOff8" 46 "Mode4_SingleOff9" 47 "Mode4_SingleOff10" 48 "Mode4_SingleOff11" 49 "Mode4_SingleOff12";
VAL_ 848 DwnLoadDynLtgPrmForFrntRIGrp24Mode1 0 "Mode4_Off" 1 "Mode4_On" 2 "Mode4_GradualOn" 3 "Mode4_GradualOff" 4 "Mode4_ForwardWipingOn" 5 "Mode4_BackwardWipingOn" 6 "Mode4_OutwardWipingOn" 7 "Mode4_InwardWipingOn" 8 "Mode4_ForwardWipingOff" 9 "Mode4_BackwardWipingOff" 10 "Mode4_OutwardWipingOff" 11 "Mode4_InwardWipingOff" 12 "Mode4_ForwardScanning" 13 "Mode4_BackwardScanning" 14 "Mode4_BreathOn" 15 "Mode4_BreathOff" 16 "Mode4_1stHalfONand2ndHalfOFF" 17 "Mode4_HalfOFFHalfON" 18 "Mode4_HalfDimmingONHalfOFF" 19 "Mode4_HalfDimmingONHalfON" 20 "Mode4_HalfOFFHalfDimmingON" 21 "Mode4_HalfONHalfDimmingON" 22 "Mode4_HalfDimmingOFFHalfOFF" 23 "Mode4_HalfDimmingOFFHalfON" 24 "Mode4_HalfOFFHalfDimmingOFF" 25 "Mode4_HalfONHalfDimmingOFF" 26 "Mode4_SingleOn1" 27 "Mode4_SingleOn2" 28 "Mode4_SingleOn3" 29 "Mode4_SingleOn4" 30 "Mode4_SingleOn5" 31 "Mode4_SingleOn6" 32 "Mode4_SingleOn7" 33 "Mode4_SingleOn8" 34 "Mode4_SingleOn9" 35 "Mode4_SingleOn10" 36 "Mode4_SingleOn11" 37 "Mode4_SingleOn12" 38 "Mode4_SingleOff1" 39 "Mode4_SingleOff2" 40 "Mode4_SingleOff3" 41 "Mode4_SingleOff4" 42 "Mode4_SingleOff5" 43 "Mode4_SingleOff6" 44 "Mode4_SingleOff7" 45 "Mode4_SingleOff8" 46 "Mode4_SingleOff9" 47 "Mode4_SingleOff10" 48 "Mode4_SingleOff11" 49 "Mode4_SingleOff12";
VAL_ 784 ActvnOfADB 0 "OnOff1_Off" 1 "OnOff1_On";
VAL_ 784 ActvnOfLiForComity 0 "OnOff1_Off" 1 "OnOff1_On";
VAL_ 784 ActvnOfLiForSpkr 0 "OnOff1_Off" 1 "OnOff1_On";
VAL_ 784 ActvnOfLiForWait 0 "OnOff1_Off" 1 "OnOff1_On";
VAL_ 784 CabPressPodCalc 0 "PresScale_Undefined" 1 "PresScale_VeryLow" 2 "PresScale_Low" 3 "PresScale_Medium" 4 "PresScale_High" 5 "PresScale_VeryHigh";
VAL_ 784 DoorDrvrLatPawlSt 0 "DoorSts2_Ukwn" 1 "DoorSts2_Opend" 2 "DoorSts2_Clsd";
VAL_ 784 DoorDrvrLatPosn 0 "DoorPos_Undefined" 1 "DoorPos_FullyClosed" 2 "DoorPos_SecondaryPosition" 3 "DoorPos_FullyOpen";
VAL_ 784 DoorLeReLatPawlSt 0 "DoorSts2_Ukwn" 1 "DoorSts2_Opend" 2 "DoorSts2_Clsd";
VAL_ 784 DoorLeReLatPosn 0 "DoorPos_Undefined" 1 "DoorPos_FullyClosed" 2 "DoorPos_SecondaryPosition" 3 "DoorPos_FullyOpen";
VAL_ 784 DoorPassLatPawlSt 0 "DoorSts2_Ukwn" 1 "DoorSts2_Opend" 2 "DoorSts2_Clsd";
VAL_ 784 DoorPassLatPosn 0 "DoorPos_Undefined" 1 "DoorPos_FullyClosed" 2 "DoorPos_SecondaryPosition" 3 "DoorPos_FullyOpen";
VAL_ 784 DoorRiReLatPawlSt 0 "DoorSts2_Ukwn" 1 "DoorSts2_Opend" 2 "DoorSts2_Clsd";
VAL_ 784 DoorRiReLatPosn 0 "DoorPos_Undefined" 1 "DoorPos_FullyClosed" 2 "DoorPos_SecondaryPosition" 3 "DoorPos_FullyOpen";
VAL_ 784 LockgCenStsLockSt 0 "LockSt3_LockUndefd" 1 "LockSt3_LockUnlckd" 2 "LockSt3_LockTrUnlckd" 3 "LockSt3_LockLockd";
VAL_ 784 LockgCenStsTrigSrc 0 "LockTrigSrc2_NoTrigSrc" 1 "LockTrigSrc2_KeyRem" 2 "LockTrigSrc2_Keyls" 3 "LockTrigSrc2_IntrSwt" 4 "LockTrigSrc2_SpdAut" 5 "LockTrigSrc2_TmrAut" 6 "LockTrigSrc2_Slam" 7 "LockTrigSrc2_Telm" 8 "LockTrigSrc2_Crash" 9 "LockTrigSrc2_Apprch" 10 "LockTrigSrc2_OutsOth" 11 "LockTrigSrc2_InsOth";
VAL_ 784 LockgCenStsUpdEve 0 "Boolean_FALSE" 1 "Boolean_TRUE";
VAL_ 784 VehMtnStVehMtnSt 0 "VehMtnSt2_Ukwn" 1 "VehMtnSt2_StandStillVal1" 2 "VehMtnSt2_StandStillVal2" 3 "VehMtnSt2_StandStillVal3" 4 "VehMtnSt2_RollgFwdVal1" 5 "VehMtnSt2_RollgFwdVal2" 6 "VehMtnSt2_RollgBackwVal1" 7 "VehMtnSt2_RollgBackwVal2";
VAL_ 1152 TiAndDateIndcnDataValid 0 "NoYes1_No" 1 "NoYes1_Yes";
VAL_ 361 CarpetLiDownloadFinish 0 "OkNotOk_NotOk" 1 "OkNotOk_Ok";
VAL_ 361 CarpetLiDownloadReq 0 "ReqSts1_NotReqd" 1 "ReqSts1_Reqd";
VAL_ 361 CarpetLiDowSwt 0 "OnOff1_Off" 1 "OnOff1_On";
VAL_ 361 DoorDrvrAutoManReq 0 "OnOffNoReq_NoReq" 1 "OnOffNoReq_On" 2 "OnOffNoReq_Off";
VAL_ 361 DoorOpenerDrvrReqDoorOpenerReq 0 "DoorOpenerIdle" 1 "DoorOpenerOpen" 2 "DoorOpenerCls" 3 "DoorOpenerStop";
VAL_ 361 DoorOpenerDrvrReqTrigSrc 0 "NoTrigSrc" 1 "KeyRem" 2 "HMI" 3 "Telm" 4 "OutdSwt" 5 "InsdSwt";
VAL_ 361 DoorOpenerLeReReqDoorOpenerReq 0 "DoorOpenerIdle" 1 "DoorOpenerOpen" 2 "DoorOpenerCls" 3 "DoorOpenerStop";
VAL_ 361 DoorOpenerLeReReqTrigSrc 0 "NoTrigSrc" 1 "KeyRem" 2 "HMI" 3 "Telm" 4 "OutdSwt" 5 "InsdSwt";
VAL_ 361 OpenDrvrSwt 0 "PsdNotPsd1_NotPsd" 1 "PsdNotPsd1_Psd";
VAL_ 361 OpenLeReSwt 0 "PsdNotPsd1_NotPsd" 1 "PsdNotPsd1_Psd";
VAL_ 361 OpenPassSwt 0 "PsdNotPsd1_NotPsd" 1 "PsdNotPsd1_Psd";
VAL_ 361 OpenRiReSwt 0 "PsdNotPsd1_NotPsd" 1 "PsdNotPsd1_Psd";
VAL_ 361 PawlDrvrSwt 0 "PsdNotPsd1_NotPsd" 1 "PsdNotPsd1_Psd";
VAL_ 361 PawlLeReSwt 0 "PsdNotPsd1_NotPsd" 1 "PsdNotPsd1_Psd";
VAL_ 361 PawlPassSwt 0 "PsdNotPsd1_NotPsd" 1 "PsdNotPsd1_Psd";
VAL_ 361 PawlRiReSwt 0 "PsdNotPsd1_NotPsd" 1 "PsdNotPsd1_Psd";
SIG_GROUP_ 128 AccrPedlRat 1 : AccrPedlRatAccrPedlRat AccrPedlRatChks AccrPedlRatCntr;
SIG_GROUP_ 128 AmbTRaw 1 : AmbTRawAmbTVal AmbTRawQly;
SIG_GROUP_ 768 BrkPedlrRat 1 : BrkPedlrRatPerc BrkPedlrRatQf;
SIG_GROUP_ 128 BrkPedlSnsr 1 : BrkPedlSnsrChks BrkPedlSnsrCntr BrkPedlSnsrQf BrkPedlSnsrSt;
SIG_GROUP_ 1431 CEMdevelpsignalgroupcheck 1 : CEMdevelpsignalgroupcheckFunctiondevpsignalgroup1 CEMdevelpsignalgroupcheckFunctiondevpsignalgroup2 CEMdevelpsignalgroupcheckFunctiondevpsignalgroup3 CEMdevelpsignalgroupcheckFunctiondevpsignalgroup4 CEMdevelpsignalgroupcheckFunctiondevpsignalgroup5 CEMdevelpsignalgroupcheckFunctiondevpsignalgroup6 CEMdevelpsignalgroupcheckFunctiondevpsignalgroup7 CEMdevelpsignalgroupcheckFunctiondevpsignalgroup8;
SIG_GROUP_ 1432 CEMdevelpsignalgroupresp 1 : CEMdevelpsignalgrouprespFunctiondevpsignalgroup1 CEMdevelpsignalgrouprespFunctiondevpsignalgroup2 CEMdevelpsignalgrouprespFunctiondevpsignalgroup3 CEMdevelpsignalgrouprespFunctiondevpsignalgroup4 CEMdevelpsignalgrouprespFunctiondevpsignalgroup5 CEMdevelpsignalgrouprespFunctiondevpsignalgroup6 CEMdevelpsignalgrouprespFunctiondevpsignalgroup7 CEMdevelpsignalgrouprespFunctiondevpsignalgroup8;
SIG_GROUP_ 361 DoorOpenerDrvrReq 1 : DoorOpenerDrvrReqChks DoorOpenerDrvrReqCntr DoorOpenerDrvrReqDoorOpenerReq DoorOpenerDrvrReqTrigSrc;
SIG_GROUP_ 361 DoorOpenerLeReReq 1 : DoorOpenerLeReReqChks DoorOpenerLeReReqCntr DoorOpenerLeReReqDoorOpenerReq DoorOpenerLeReReqTrigSrc;
SIG_GROUP_ 292 DwnLoadDynLitPrmForLedMkrLampLe1 1 : DwnLoadDynLitPrmForLedMkrLampLe1ContTiPrm DwnLoadDynLitPrmForLedMkrLampLe1LowBriPrm DwnLoadDynLitPrmForLedMkrLampLe1ModePrm DwnLoadDynLitPrmForLedMkrLampLe1OffsTiPrm DwnLoadDynLitPrmForLedMkrLampLe1Tistamp DwnLoadDynLitPrmForLedMkrLampLe1UpprBriPrm;
SIG_GROUP_ 294 DwnLoadDynLitPrmForLedMkrLampLe2 1 : DwnLoadDynLitPrmForLedMkrLampLe2ContTiPrm DwnLoadDynLitPrmForLedMkrLampLe2LowBriPrm DwnLoadDynLitPrmForLedMkrLampLe2ModePrm DwnLoadDynLitPrmForLedMkrLampLe2OffsTiPrm DwnLoadDynLitPrmForLedMkrLampLe2Tistamp DwnLoadDynLitPrmForLedMkrLampLe2UpprBriPrm;
SIG_GROUP_ 295 DwnLoadDynLitPrmForLedMkrLampRi1 1 : DwnLoadDynLitPrmForLedMkrLampRi1ContTiPrm DwnLoadDynLitPrmForLedMkrLampRi1LowBriPrm DwnLoadDynLitPrmForLedMkrLampRi1ModePrm DwnLoadDynLitPrmForLedMkrLampRi1OffsTiPrm DwnLoadDynLitPrmForLedMkrLampRi1Tistamp DwnLoadDynLitPrmForLedMkrLampRi1UpprBriPrm;
SIG_GROUP_ 296 DwnLoadDynLitPrmForLedStopLampLe1 1 : DwnLoadDynLitPrmForLedStopLampLe1ContTiPrm DwnLoadDynLitPrmForLedStopLampLe1LowBriPrm DwnLoadDynLitPrmForLedStopLampLe1ModePrm DwnLoadDynLitPrmForLedStopLampLe1OffsTiPrm DwnLoadDynLitPrmForLedStopLampLe1Tistamp DwnLoadDynLitPrmForLedStopLampLe1UpprBriPrm;
SIG_GROUP_ 297 DwnLoadDynLitPrmForLedStopLampLe2 1 : DwnLoadDynLitPrmForLedStopLampLe2ContTiPrm DwnLoadDynLitPrmForLedStopLampLe2LowBriPrm DwnLoadDynLitPrmForLedStopLampLe2ModePrm DwnLoadDynLitPrmForLedStopLampLe2OffsTiPrm DwnLoadDynLitPrmForLedStopLampLe2Tistamp DwnLoadDynLitPrmForLedStopLampLe2UpprBriPrm;
SIG_GROUP_ 288 DwnLoadDynLitPrmForLedStopLampRi2 1 : DwnLoadDynLitPrmForLedStopLampRi2ContTiPrm DwnLoadDynLitPrmForLedStopLampRi2LowBriPrm DwnLoadDynLitPrmForLedStopLampRi2ModePrm DwnLoadDynLitPrmForLedStopLampRi2OffsTiPrm DwnLoadDynLitPrmForLedStopLampRi2Tistamp DwnLoadDynLitPrmForLedStopLampRi2UpprBriPrm;
SIG_GROUP_ 289 DwnLoadDynLitPrmLedReFogLampRi2 1 : DwnLoadDynLitPrmLedReFogLampRi2ContTiPrm DwnLoadDynLitPrmLedReFogLampRi2LowBriPrm DwnLoadDynLitPrmLedReFogLampRi2ModePrm DwnLoadDynLitPrmLedReFogLampRi2OffsTiPrm DwnLoadDynLitPrmLedReFogLampRi2Tistamp DwnLoadDynLitPrmLedReFogLampRi2UpprBriPrm;
SIG_GROUP_ 290 DwnLoadDynLitPrmLedRePosnLampRi2 1 : DwnLoadDynLitPrmLedRePosnLampRi2ContTiPrm DwnLoadDynLitPrmLedRePosnLampRi2LowBriPrm DwnLoadDynLitPrmLedRePosnLampRi2ModePrm DwnLoadDynLitPrmLedRePosnLampRi2OffsTiPrm DwnLoadDynLitPrmLedRePosnLampRi2Tistamp DwnLoadDynLitPrmLedRePosnLampRi2UpprBriPrm;
SIG_GROUP_ 291 DwnLoadDynLitPrmLedReTurnIndcrRi2 1 : DwnLoadDynLitPrmLedReTurnIndcrRi2ContTiPrm DwnLoadDynLitPrmLedReTurnIndcrRi2LowBriPrm DwnLoadDynLitPrmLedReTurnIndcrRi2ModePrm DwnLoadDynLitPrmLedReTurnIndcrRi2OffsTiPrm DwnLoadDynLitPrmLedReTurnIndcrRi2Tistamp DwnLoadDynLitPrmLedReTurnIndcrRi2UpprBriPrm;
SIG_GROUP_ 834 DwnLoadDynLtgPrmForFrntRIGrp10 1 : DwnLoadDynLtgPrmForFrntRIGrp10ContinueTime DwnLoadDynLtgPrmForFrntRIGrp10HighBrightness DwnLoadDynLtgPrmForFrntRIGrp10LowBrightness DwnLoadDynLtgPrmForFrntRIGrp10Mode1 DwnLoadDynLtgPrmForFrntRIGrp10OffsetTime DwnLoadDynLtgPrmForFrntRIGrp10Timestamp;
SIG_GROUP_ 835 DwnLoadDynLtgPrmForFrntRIGrp11 1 : DwnLoadDynLtgPrmForFrntRIGrp11ContinueTime DwnLoadDynLtgPrmForFrntRIGrp11HighBrightness DwnLoadDynLtgPrmForFrntRIGrp11LowBrightness DwnLoadDynLtgPrmForFrntRIGrp11Mode1 DwnLoadDynLtgPrmForFrntRIGrp11OffsetTime DwnLoadDynLtgPrmForFrntRIGrp11Timestamp;
SIG_GROUP_ 836 DwnLoadDynLtgPrmForFrntRIGrp12 1 : DwnLoadDynLtgPrmForFrntRIGrp12ContinueTime DwnLoadDynLtgPrmForFrntRIGrp12HighBrightness DwnLoadDynLtgPrmForFrntRIGrp12LowBrightness DwnLoadDynLtgPrmForFrntRIGrp12Mode1 DwnLoadDynLtgPrmForFrntRIGrp12OffsetTime DwnLoadDynLtgPrmForFrntRIGrp12Timestamp;
SIG_GROUP_ 837 DwnLoadDynLtgPrmForFrntRIGrp13 1 : DwnLoadDynLtgPrmForFrntRIGrp13ContinueTime DwnLoadDynLtgPrmForFrntRIGrp13HighBrightness DwnLoadDynLtgPrmForFrntRIGrp13LowBrightness DwnLoadDynLtgPrmForFrntRIGrp13Mode1 DwnLoadDynLtgPrmForFrntRIGrp13OffsetTime DwnLoadDynLtgPrmForFrntRIGrp13Timestamp;
SIG_GROUP_ 838 DwnLoadDynLtgPrmForFrntRIGrp14 1 : DwnLoadDynLtgPrmForFrntRIGrp14ContinueTime DwnLoadDynLtgPrmForFrntRIGrp14HighBrightness DwnLoadDynLtgPrmForFrntRIGrp14LowBrightness DwnLoadDynLtgPrmForFrntRIGrp14Mode1 DwnLoadDynLtgPrmForFrntRIGrp14OffsetTime DwnLoadDynLtgPrmForFrntRIGrp14Timestamp;
SIG_GROUP_ 839 DwnLoadDynLtgPrmForFrntRIGrp15 1 : DwnLoadDynLtgPrmForFrntRIGrp15ContinueTime DwnLoadDynLtgPrmForFrntRIGrp15HighBrightness DwnLoadDynLtgPrmForFrntRIGrp15LowBrightness DwnLoadDynLtgPrmForFrntRIGrp15Mode1 DwnLoadDynLtgPrmForFrntRIGrp15OffsetTime DwnLoadDynLtgPrmForFrntRIGrp15Timestamp;
SIG_GROUP_ 840 DwnLoadDynLtgPrmForFrntRIGrp16 1 : DwnLoadDynLtgPrmForFrntRIGrp16ContinueTime DwnLoadDynLtgPrmForFrntRIGrp16HighBrightness DwnLoadDynLtgPrmForFrntRIGrp16LowBrightness DwnLoadDynLtgPrmForFrntRIGrp16Mode1 DwnLoadDynLtgPrmForFrntRIGrp16OffsetTime DwnLoadDynLtgPrmForFrntRIGrp16Timestamp;
SIG_GROUP_ 841 DwnLoadDynLtgPrmForFrntRIGrp17 1 : DwnLoadDynLtgPrmForFrntRIGrp17ContinueTime DwnLoadDynLtgPrmForFrntRIGrp17HighBrightness DwnLoadDynLtgPrmForFrntRIGrp17LowBrightness DwnLoadDynLtgPrmForFrntRIGrp17Mode1 DwnLoadDynLtgPrmForFrntRIGrp17OffsetTime DwnLoadDynLtgPrmForFrntRIGrp17Timestamp;
SIG_GROUP_ 842 DwnLoadDynLtgPrmForFrntRIGrp18 1 : DwnLoadDynLtgPrmForFrntRIGrp18ContinueTime DwnLoadDynLtgPrmForFrntRIGrp18HighBrightness DwnLoadDynLtgPrmForFrntRIGrp18LowBrightness DwnLoadDynLtgPrmForFrntRIGrp18Mode1 DwnLoadDynLtgPrmForFrntRIGrp18OffsetTime DwnLoadDynLtgPrmForFrntRIGrp18Timestamp;
SIG_GROUP_ 843 DwnLoadDynLtgPrmForFrntRIGrp19 1 : DwnLoadDynLtgPrmForFrntRIGrp19ContinueTime DwnLoadDynLtgPrmForFrntRIGrp19HighBrightness DwnLoadDynLtgPrmForFrntRIGrp19LowBrightness DwnLoadDynLtgPrmForFrntRIGrp19Mode1 DwnLoadDynLtgPrmForFrntRIGrp19OffsetTime DwnLoadDynLtgPrmForFrntRIGrp19Timestamp;
SIG_GROUP_ 844 DwnLoadDynLtgPrmForFrntRIGrp20 1 : DwnLoadDynLtgPrmForFrntRIGrp20ContinueTime DwnLoadDynLtgPrmForFrntRIGrp20HighBrightness DwnLoadDynLtgPrmForFrntRIGrp20LowBrightness DwnLoadDynLtgPrmForFrntRIGrp20Mode1 DwnLoadDynLtgPrmForFrntRIGrp20OffsetTime DwnLoadDynLtgPrmForFrntRIGrp20Timestamp;
SIG_GROUP_ 845 DwnLoadDynLtgPrmForFrntRIGrp21 1 : DwnLoadDynLtgPrmForFrntRIGrp21ContinueTime DwnLoadDynLtgPrmForFrntRIGrp21HighBrightness DwnLoadDynLtgPrmForFrntRIGrp21LowBrightness DwnLoadDynLtgPrmForFrntRIGrp21Mode1 DwnLoadDynLtgPrmForFrntRIGrp21OffsetTime DwnLoadDynLtgPrmForFrntRIGrp21Timestamp;
SIG_GROUP_ 846 DwnLoadDynLtgPrmForFrntRIGrp22 1 : DwnLoadDynLtgPrmForFrntRIGrp22ContinueTime DwnLoadDynLtgPrmForFrntRIGrp22HighBrightness DwnLoadDynLtgPrmForFrntRIGrp22LowBrightness DwnLoadDynLtgPrmForFrntRIGrp22Mode1 DwnLoadDynLtgPrmForFrntRIGrp22OffsetTime DwnLoadDynLtgPrmForFrntRIGrp22Timestamp;
SIG_GROUP_ 847 DwnLoadDynLtgPrmForFrntRIGrp23 1 : DwnLoadDynLtgPrmForFrntRIGrp23ContinueTime DwnLoadDynLtgPrmForFrntRIGrp23HighBrightness DwnLoadDynLtgPrmForFrntRIGrp23LowBrightness DwnLoadDynLtgPrmForFrntRIGrp23Mode1 DwnLoadDynLtgPrmForFrntRIGrp23OffsetTime DwnLoadDynLtgPrmForFrntRIGrp23Timestamp;
SIG_GROUP_ 848 DwnLoadDynLtgPrmForFrntRIGrp24 1 : DwnLoadDynLtgPrmForFrntRIGrp24ContinueTime DwnLoadDynLtgPrmForFrntRIGrp24HighBrightness DwnLoadDynLtgPrmForFrntRIGrp24LowBrightness DwnLoadDynLtgPrmForFrntRIGrp24Mode1 DwnLoadDynLtgPrmForFrntRIGrp24OffsetTime DwnLoadDynLtgPrmForFrntRIGrp24Timestamp;
SIG_GROUP_ 293 DwnLoadDynLtgPrmForLedLoBeamRi 1 : DwnLoadDynLtgPrmForLedLoBeamRiContTiPrm DwnLoadDynLtgPrmForLedLoBeamRiLowBriPrm DwnLoadDynLtgPrmForLedLoBeamRiModePrm DwnLoadDynLtgPrmForLedLoBeamRiOffsTiPrm DwnLoadDynLtgPrmForLedLoBeamRiTistamp DwnLoadDynLtgPrmForLedLoBeamRiUpprBriPrm;
SIG_GROUP_ 784 LockgCenSts 1 : LockgCenStsLockSt LockgCenStsTrigSrc LockgCenStsUpdEve;
SIG_GROUP_ 82 SteerWhlSnsr 1 : SteerWhlSnsrAg SteerWhlSnsrAgSpd SteerWhlSnsrChks SteerWhlSnsrCntr SteerWhlSnsrQf;
SIG_GROUP_ 400 SuspPosnVertAg 1 : SuspPosnVertAgGenQf SuspPosnVertAgSuspPosnVertAg;
SIG_GROUP_ 400 SuspPosnVertLvl 1 : SuspPosnVertLvlFrnt SuspPosnVertLvlFrntQf SuspPosnVertLvlRe SuspPosnVertLvlReQf;
SIG_GROUP_ 1152 TiAndDateIndcn 1 : TiAndDateIndcnDataValid TiAndDateIndcnDay TiAndDateIndcnHr1 TiAndDateIndcnMins1 TiAndDateIndcnMth1 TiAndDateIndcnSec1 TiAndDateIndcnYr1;
SIG_GROUP_ 389 TrafficSignForADB1 1 : TrafficSignForADB1AdbAbsDist TrafficSignForADB1AdbDetdQly TrafficSignForADB1AdbHozlAgLe TrafficSignForADB1AdbHozlAgRi TrafficSignForADB1AdbTrkInfo TrafficSignForADB1AdbVertAgBot TrafficSignForADB1AdbVertAgTop;
SIG_GROUP_ 390 TrafficSignForADB2 1 : TrafficSignForADB2AdbAbsDist TrafficSignForADB2AdbDetdQly TrafficSignForADB2AdbHozlAgLe TrafficSignForADB2AdbHozlAgRi TrafficSignForADB2AdbTrkInfo TrafficSignForADB2AdbVertAgBot TrafficSignForADB2AdbVertAgTop;
SIG_GROUP_ 512 VehBattU 1 : VehBattUSysU VehBattUSysUQf;
SIG_GROUP_ 384 VehCfgPrm 1 : VehCfgPrmBlkIDBytePosn1 VehCfgPrmCCPBytePosn2 VehCfgPrmCCPBytePosn3 VehCfgPrmCCPBytePosn4 VehCfgPrmCCPBytePosn5 VehCfgPrmCCPBytePosn6 VehCfgPrmCCPBytePosn7 VehCfgPrmCCPBytePosn8;
SIG_GROUP_ 387 VehCfgPrmExt 1 : VehCfgPrmExtBlkIDBytePosn1 VehCfgPrmExtCCPBytePosn2 VehCfgPrmExtCCPBytePosn3 VehCfgPrmExtCCPBytePosn4 VehCfgPrmExtCCPBytePosn5 VehCfgPrmExtCCPBytePosn6 VehCfgPrmExtCCPBytePosn7 VehCfgPrmExtCCPBytePosn8;
SIG_GROUP_ 64 VehModMngtGlbSafe1 1 : VehModMngtGlbSafe1CarModSts1 VehModMngtGlbSafe1CarModSubtypWdCarModSubtyp VehModMngtGlbSafe1Chks VehModMngtGlbSafe1Cntr VehModMngtGlbSafe1EgyLvlElecMai VehModMngtGlbSafe1EgyLvlElecSubtyp VehModMngtGlbSafe1FltEgyCnsWdSts VehModMngtGlbSafe1PwrLvlElecMai VehModMngtGlbSafe1PwrLvlElecSubtyp VehModMngtGlbSafe1UsgModSts;
SIG_GROUP_ 784 VehMtnSt 1 : VehMtnStChks VehMtnStCntr VehMtnStVehMtnSt;
SIG_GROUP_ 392 VehObjforADB1 1 : VehObjforADB1AdbAbsDist VehObjforADB1AdbClassn VehObjforADB1AdbHozlAgLe VehObjforADB1AdbHozlAgRi VehObjforADB1AdbObjDir VehObjforADB1AdbObjHozlAgSpdLe VehObjforADB1AdbObjHozlAgSpdRi VehObjforADB1AdbTrkInfo VehObjforADB1AdbVertAg;
SIG_GROUP_ 393 VehObjforADB2 1 : VehObjforADB2AdbAbsDist VehObjforADB2AdbClassn VehObjforADB2AdbHozlAgLe VehObjforADB2AdbHozlAgRi VehObjforADB2AdbObjDir VehObjforADB2AdbObjHozlAgSpdLe VehObjforADB2AdbObjHozlAgSpdRi VehObjforADB2AdbTrkInfo VehObjforADB2AdbVertAg;
SIG_GROUP_ 394 VehObjforADB3 1 : VehObjforADB3AdbAbsDist VehObjforADB3AdbClassn VehObjforADB3AdbHozlAgLe VehObjforADB3AdbHozlAgRi VehObjforADB3AdbObjDir VehObjforADB3AdbObjHozlAgSpdLe VehObjforADB3AdbObjHozlAgSpdRi VehObjforADB3AdbTrkInfo VehObjforADB3AdbVertAg;
SIG_GROUP_ 395 VehObjforADB4 1 : VehObjforADB4AdbAbsDist VehObjforADB4AdbClassn VehObjforADB4AdbHozlAgLe VehObjforADB4AdbHozlAgRi VehObjforADB4AdbObjDir VehObjforADB4AdbObjHozlAgSpdLe VehObjforADB4AdbObjHozlAgSpdRi VehObjforADB4AdbTrkInfo VehObjforADB4AdbVertAg;
SIG_GROUP_ 396 VehObjforADB5 1 : VehObjforADB5AdbAbsDist VehObjforADB5AdbClassn VehObjforADB5AdbHozlAgLe VehObjforADB5AdbHozlAgRi VehObjforADB5AdbObjDir VehObjforADB5AdbObjHozlAgSpdLe VehObjforADB5AdbObjHozlAgSpdRi VehObjforADB5AdbTrkInfo VehObjforADB5AdbVertAg;
SIG_GROUP_ 397 VehObjforADB6 1 : VehObjforADB6AdbAbsDist VehObjforADB6AdbClassn VehObjforADB6AdbHozlAgLe VehObjforADB6AdbHozlAgRi VehObjforADB6AdbObjDir VehObjforADB6AdbObjHozlAgSpdLe VehObjforADB6AdbObjHozlAgSpdRi VehObjforADB6AdbTrkInfo VehObjforADB6AdbVertAg;
SIG_GROUP_ 398 VehObjforADB7 1 : VehObjforADB7AdbAbsDist VehObjforADB7AdbClassn VehObjforADB7AdbHozlAgLe VehObjforADB7AdbHozlAgRi VehObjforADB7AdbObjDir VehObjforADB7AdbObjHozlAgSpdLe VehObjforADB7AdbObjHozlAgSpdRi VehObjforADB7AdbTrkInfo VehObjforADB7AdbVertAg;
SIG_GROUP_ 399 VehObjforADB8 1 : VehObjforADB8AdbAbsDist VehObjforADB8AdbClassn VehObjforADB8AdbHozlAgLe VehObjforADB8AdbHozlAgRi VehObjforADB8AdbObjDir VehObjforADB8AdbObjHozlAgSpdLe VehObjforADB8AdbObjHozlAgSpdRi VehObjforADB8AdbTrkInfo VehObjforADB8AdbVertAg;
SIG_GROUP_ 391 VehObjforAHB 1 : VehObjforAHBAdbAbsDist VehObjforAHBAdbClassn VehObjforAHBAdbClassnQly VehObjforAHBAdbDetdQly VehObjforAHBAdbHozlAg VehObjforAHBAdbObjDir VehObjforAHBAdbObjHozlAgSpd VehObjforAHBAdbObjVertAgSpd VehObjforAHBAdbTrkInfo VehObjforAHBAdbVertAg;
SIG_GROUP_ 80 VehSpdLgt 1 : VehSpdLgtA VehSpdLgtChks VehSpdLgtCntr VehSpdLgtQf;
